VERSION "FL_PT_CANFD"

NS_ :

BS_:

BU_: EMS_ICE EMS_PHEV FLZCU FMCU PDCS1 PDCS2 RMCU RXCU TCU_PHEV TCUR TESTER

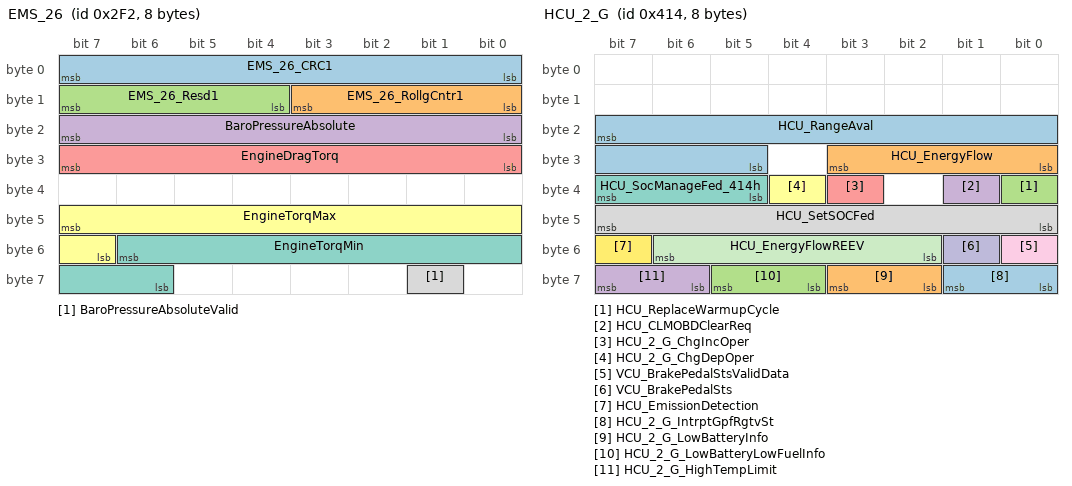
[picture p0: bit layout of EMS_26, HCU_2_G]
BO_ 754 EMS_26: 8 EMS_PHEV
 SG_ EMS_26_CRC1 : 7|8@0+ (1,0) [0|255] "" RXCU
 SG_ EMS_26_RollgCntr1 : 11|4@0+ (1,0) [0|14] "" RXCU
 SG_ EMS_26_Resd1 : 15|4@0+ (1,0) [0|15] "" RXCU
 SG_ BaroPressureAbsolute : 23|8@0+ (0.5,0) [0|127.5] "kPa" RXCU
 SG_ EngineDragTorq : 31|8@0+ (0.5,-125) [-125|0] "NM" RXCU
 SG_ EngineTorqMax : 47|9@0+ (1,-50) [-50|400] "NM" RXCU
 SG_ EngineTorqMin : 54|9@0+ (1,-50) [-50|400] "NM" RXCU
 SG_ BaroPressureAbsoluteValid : 57|1@0+ (1,0) [0|1] "" RXCU

BO_ 777 ISGF_2: 8 FMCU
 SG_ ISGF_ErrLvl : 20|4@0+ (1,0) [0|15] "" RXCU

BO_ 782 RMCU_6: 24 RXCU
 SG_ RMCU_6_CRC : 7|8@0+ (1,0) [0|255] "" Vector__XXX
 SG_ RMCU_6_RollgCntr : 11|4@0+ (1,0) [0|14] "" Vector__XXX
 SG_ RMCU_6_Resd : 15|4@0+ (1,0) [0|15] "" Vector__XXX
 SG_ RMCU_6_Ratio : 23|12@0+ (0.01,1) [8|41.95] "" PDCS1,PDCS2
 SG_ TCUR_SubFaultFlag : 39|32@0+ (1,0) [0|16777215] "" Vector__XXX
 SG_ TCUR_ActrFailrSt : 87|5@0+ (1,0) [0|31] "" Vector__XXX

BO_ 786 ISGF_3: 8 FMCU
 SG_ ISGF_GateDrvSt : 50|2@0+ (1,0) [0|3] "" RXCU

BO_ 808 RMCU_2: 16 RXCU
 SG_ RMCU_2_CRC1 : 7|8@0+ (1,0) [0|255] "" FLZCU,PDCS1,PDCS2
 SG_ RMCU_2_RollgCntr1 : 11|4@0+ (1,0) [0|14] "" FLZCU,PDCS1,PDCS2
 SG_ RMCU_2_Resd1 : 15|4@0+ (1,0) [0|15] "" FLZCU,PDCS1,PDCS2
 SG_ RMCU_2_InverterTemperature : 23|8@0+ (1,-40) [-40|213] "oC" FLZCU,PDCS1,PDCS2
 SG_ RMCU_2_StatorTemperature : 38|9@0+ (1,-40) [-40|460] "oC" FLZCU,PDCS1,PDCS2
 SG_ RMCU_HeatRunFlg : 39|1@0+ (1,0) [0|1] "" FLZCU
 SG_ RMCU_Ratio : 45|11@0+ (0.01,1) [8|15] "" FLZCU
 SG_ RMCU_LowPwrSts : 48|1@0+ (1,0) [0|1] "" FLZCU,PDCS1,PDCS2
 SG_ RMCU_InvSampTemperature : 63|8@0+ (1,-40) [-40|213] "oC" FLZCU,PDCS1,PDCS2
 SG_ RMCU_2_CRC2 : 71|8@0+ (1,0) [0|255] "" FLZCU
 SG_ RMCU_2_RollgCntr2 : 75|4@0+ (1,0) [0|14] "" FLZCU
 SG_ RMCU_2_Resd2 : 79|4@0+ (1,0) [0|15] "" FLZCU
 SG_ RMCU_2_MaxHeatSpeed : 87|16@0+ (1,-32767) [-32767|32766] "rpm" FLZCU
 SG_ RMCU_2_MaxHeatTorque : 103|12@0+ (0.25,0) [0|500] "Nm" FLZCU
 SG_ RMCU_immoResult : 107|3@0+ (1,0) [0|7] "" FLZCU

BO_ 859 FLZCU_5: 8 FLZCU
 SG_ TorqueReductReqRAValidData : 39|1@0+ (1,0) [0|1] "" RXCU

BO_ 884 TMS_4: 64 FLZCU
 SG_ WPump3Duty : 303|8@0+ (0.4,0) [0|100] "%" RXCU
 SG_ CoolingFanDuty : 382|7@0+ (1,0) [0|100] "%" RXCU

BO_ 929 IMMO_MCU_13: 8 FLZCU
 SG_ IMMO_Auth_MCU : 7|64@0+ (1,0) [0|18446744073709551615] "" RXCU

BO_ 938 IMMO_MCU_14: 8 FLZCU
 SG_ IMMO_Teach_MCU : 7|64@0+ (1,0) [0|18446744073709551615] "" RXCU

BO_ 947 MCU_IMMO_13: 8 RXCU
 SG_ MCU_Chall_IMMO : 7|64@0+ (1,0) [0|18446744073709551615] "" FLZCU

BO_ 952 MCU_IMMO_14: 8 RXCU
 SG_ MCU_Teach_IMMO : 7|64@0+ (1,0) [0|18446744073709551615] "" FLZCU

BO_ 1022 FLZCU_40: 64 FLZCU
 SG_ FLZCU_CarMode : 23|3@0+ (1,0) [0|7] "" RXCU

BO_ 1034 HCU_1_G: 8 RXCU
 SG_ HCU_1_G_CRC1 : 7|8@0+ (1,0) [0|255] "" EMS_PHEV,FLZCU
 SG_ HCU_1_G_RollgCntr1 : 11|4@0+ (1,0) [0|14] "" EMS_PHEV,FLZCU
 SG_ HCU_1_G_Resd1 : 15|4@0+ (1,0) [0|15] "" EMS_PHEV,FLZCU
 SG_ HCU_EmPwr : 23|8@0+ (1,-128) [-100|100] "%" FLZCU
 SG_ HCU_VehicleState : 27|4@0+ (1,0) [0|15] "" FLZCU
 SG_ HCU_RunMode : 29|2@0+ (1,0) [0|3] "" FLZCU,FMCU,TCU_PHEV
 SG_ HCU_TMNumber : 31|2@0+ (1,0) [0|3] "" FLZCU
 SG_ HCU_PwrTrnModeDisp : 34|3@0+ (1,0) [0|7] "" FLZCU
 SG_ HCU_IntelligentPowerSupply : 37|3@0+ (1,0) [0|7] "" FLZCU
 SG_ HCU_PowerModeFed : 39|2@0+ (1,0) [0|3] "" FLZCU,TCU_PHEV
 SG_ HCU_LimpHomeMode : 41|2@0+ (1,0) [0|3] "" FLZCU,TCU_PHEV
 SG_ HCU_ISGRegenerateSts : 42|1@0+ (1,0) [0|1] "" FLZCU
 SG_ HCU_EmOverSpdWarn : 43|1@0+ (1,0) [0|1] "" FLZCU
 SG_ HCU_PowertrainFault : 44|1@0+ (1,0) [0|1] "" FLZCU
 SG_ HCU_PrePTReady : 45|1@0+ (1,0) [0|1] "" EMS_PHEV,FLZCU
 SG_ HCU_PowerModeChangeFail : 46|1@0+ (1,0) [0|1] "" FLZCU
 SG_ BMSH_MILReq : 47|1@0+ (1,0) [0|1] "" EMS_PHEV,FLZCU
 SG_ TMF_EngMilLampReq : 48|1@0+ (1,0) [0|1] "" EMS_PHEV,FLZCU
 SG_ TMR_EngMilLampReq : 49|1@0+ (1,0) [0|1] "" EMS_PHEV,FLZCU
 SG_ HCU_MILReq : 50|1@0+ (1,0) [0|1] "" EMS_PHEV,FLZCU
 SG_ HCU_HVReady : 51|1@0+ (1,0) [0|1] "" EMS_PHEV,FLZCU,TCU_PHEV
 SG_ HCU_PTReady : 52|1@0+ (1,0) [0|1] "" EMS_PHEV,FLZCU,TCU_PHEV
 SG_ HCU_ChargingSts : 54|2@0+ (1,0) [0|3] "" FLZCU,FMCU
 SG_ HCU_PtSts : 59|4@0+ (1,0) [0|15] "" FLZCU
 SG_ HCU_InHbStrtRes : 63|4@0+ (1,0) [0|15] "" FLZCU

BO_ 1044 HCU_2_G: 8 RXCU
 SG_ HCU_RangeAval : 23|11@0+ (1,0) [0|2046] "KM" Vector__XXX
 SG_ HCU_EnergyFlow : 27|4@0+ (1,0) [0|15] "" Vector__XXX
 SG_ HCU_ReplaceWarmupCycle : 32|1@0+ (1,0) [0|1] "" EMS_PHEV,FMCU
 SG_ HCU_CLMOBDClearReq : 33|1@0+ (1,0) [0|1] "" Vector__XXX
 SG_ HCU_2_G_ChgIncOper : 35|1@0+ (1,0) [0|1] "" EMS_PHEV
 SG_ HCU_2_G_ChgDepOper : 36|1@0+ (1,0) [0|1] "" EMS_PHEV
 SG_ HCU_SocManageFed_414h : 39|3@0+ (1,0) [0|7] "" Vector__XXX
 SG_ HCU_SetSOCFed : 47|8@0+ (1,0) [0|100] "" Vector__XXX
 SG_ VCU_BrakePedalStsValidData : 48|1@0+ (1,0) [0|1] "" EMS_PHEV,FMCU
 SG_ VCU_BrakePedalSts : 49|1@0+ (1,0) [0|1] "" EMS_PHEV,FMCU
 SG_ HCU_EnergyFlowREEV : 54|5@0+ (1,0) [0|31] "" Vector__XXX
 SG_ HCU_EmissionDetection : 55|1@0+ (1,0) [0|1] "" Vector__XXX
 SG_ HCU_2_G_IntrptGpfRgtvSt : 57|2@0+ (1,0) [0|3] "" EMS_PHEV
 SG_ HCU_2_G_LowBatteryInfo : 59|2@0+ (1,0) [0|3] "" Vector__XXX
 SG_ HCU_2_G_LowBatteryLowFuelInfo : 61|2@0+ (1,0) [0|3] "" Vector__XXX
 SG_ HCU_2_G_HighTempLimit : 63|2@0+ (1,0) [0|3] "" Vector__XXX

BO_ 1057 VCU_7_G: 32 RXCU
 SG_ VCU_shfChk : 16|1@0+ (1,0) [0|1] "" Vector__XXX
 SG_ VCU_PowerLimitSOCLow : 19|3@0+ (1,0) [0|7] "" Vector__XXX
 SG_ VCU_MCU_MilLampReq : 20|1@0+ (1,0) [0|1] "" Vector__XXX
 SG_ VCU_OPDinfo : 23|3@0+ (1,0) [0|7] "" Vector__XXX
 SG_ VCU_ePTDrvPowerPcent : 31|8@0+ (1,-100) [-100|100] "%" Vector__XXX
 SG_ VCU_TowingMode : 33|2@0+ (1,0) [0|3] "" Vector__XXX
 SG_ VCU_EgyRegenLevelHighAllowed : 35|2@0+ (1,0) [0|3] "" Vector__XXX
 SG_ VCU_SportDriveModeAvailable : 36|1@0+ (1,0) [0|1] "" Vector__XXX
 SG_ VCU_RainSnowDriveModeAvailable : 37|1@0+ (1,0) [0|1] "" Vector__XXX
 SG_ VCU_OffRoadDriveModeAvailable : 38|1@0+ (1,0) [0|1] "" Vector__XXX
 SG_ VCU_CampAvailable : 39|1@0+ (1,0) [0|1] "" Vector__XXX
 SG_ VCU_DisChgSOCHighLim : 47|8@0+ (1,0) [1|100] "%" Vector__XXX
 SG_ VCU_DisChgSOCLowLim : 55|8@0+ (1,0) [1|50] "%" Vector__XXX
 SG_ VCU_ChgSocSetFed : 63|8@0+ (1,0) [50|100] "%" Vector__XXX
 SG_ VCU_EngyConsuPer10Km : 87|12@0+ (0.1,-100) [-100|100] "" Vector__XXX
 SG_ VCU_EngyConsuPer25Km : 91|12@0+ (0.1,-100) [-100|100] "" Vector__XXX
 SG_ VCU_EngyConsuPer50Km : 111|12@0+ (0.1,-100) [-100|100] "" Vector__XXX
 SG_ VCU_EngyConsuPer100m : 115|12@0+ (0.1,-100) [-100|100] "" Vector__XXX
 SG_ VCU_DisChrgPwr : 151|8@0+ (0.1,0) [0|25.5] "kW" Vector__XXX
 SG_ VCU_BookChrgSetFailRes : 154|3@0+ (1,0) [0|7] "" Vector__XXX
 SG_ VCU_BookChrgFailRes : 158|4@0+ (1,0) [0|15] "" Vector__XXX
 SG_ VCU_HVILFault : 159|1@0+ (1,0) [0|1] "" Vector__XXX
 SG_ VCUExtendRang : 167|10@0+ (1,0) [0|1022] "KM" Vector__XXX
 SG_ VCU_KeepWarmFailReason : 171|4@0+ (1,0) [0|15] "" Vector__XXX
 SG_ VCU_ExtremeEnergySavingModeAv : 173|1@0+ (1,0) [0|1] "" Vector__XXX
 SG_ VCU_TowModeAvailable : 176|1@0+ (1,0) [0|1] "" Vector__XXX
 SG_ VCU_StopModeSWStsResp : 178|2@0+ (1,0) [0|3] "" Vector__XXX
 SG_ VCU_StopModeSWAllowed : 179|1@0+ (1,0) [0|1] "" Vector__XXX
 SG_ VCU_ChgDisChgLedCtrl : 183|4@0+ (1,0) [0|15] "" Vector__XXX
 SG_ VCU_CPMaxVolt : 191|8@0+ (0.1,0) [0|20] "V" Vector__XXX
 SG_ VCUExtremeEnergySavingModeReq : 211|2@0+ (1,0) [0|3] "" Vector__XXX
 SG_ VCU_EpedalModeSts : 213|1@0+ (1,0) [0|1] "" Vector__XXX
 SG_ VCU_BookChrgStsFb : 215|2@0+ (1,0) [0|3] "" Vector__XXX
 SG_ VCU_HVNM : 219|2@0+ (1,0) [0|3] "" Vector__XXX
 SG_ VCU_DriveMode : 223|3@0+ (1,0) [0|7] "" Vector__XXX
 SG_ HCU_EnterForceEVFailRes : 229|3@0+ (1,0) [0|7] "" Vector__XXX
 SG_ HCU_EngineSelfMaintain : 231|2@0+ (1,0) [0|3] "" Vector__XXX
 SG_ HCU_EnterForceChrgFailRes : 234|3@0+ (1,0) [0|7] "" Vector__XXX
 SG_ HCU_InStartRes : 242|3@0+ (1,0) [0|7] "" Vector__XXX
 SG_ HCU_EnergyRegSetFed : 255|8@0+ (1,0) [0|100] "%" Vector__XXX

BO_ 1064 FLZCU_428h: 32 FLZCU
 SG_ WorkingSts : 28|1@0+ (1,0) [0|1] "" RXCU
 SG_ ADCC_AdsLowPowSts_333h : 37|2@0+ (1,0) [0|3] "" RXCU

BO_ 1075 VCC_2: 8 FLZCU
 SG_ VCC_2_ConfigurationMessageTrg : 23|1@0+ (1,0) [0|1] "" RXCU

BO_ 1097 TMS_HW_449h: 48 FLZCU
 SG_ TMS_RMCU_MotSelfHeatLvlReq : 86|3@0+ (1,0) [0|7] "" RXCU
 SG_ TMS_RMCU_MotSelfHeatEnReq : 87|1@0+ (1,0) [0|1] "" RXCU

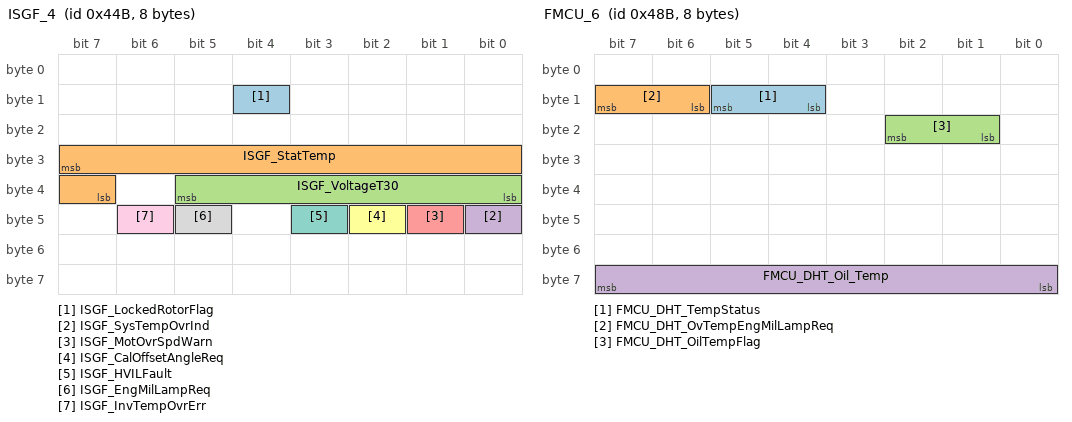
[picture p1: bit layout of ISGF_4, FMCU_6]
BO_ 1099 ISGF_4: 8 FMCU
 SG_ ISGF_LockedRotorFlag : 12|1@0+ (1,0) [0|1] "" RXCU
 SG_ ISGF_StatTemp : 31|9@0+ (1,-40) [-40|469] "oC" RXCU
 SG_ ISGF_VoltageT30 : 37|6@0+ (0.5,0) [0|31] "V" RXCU
 SG_ ISGF_SysTempOvrInd : 40|1@0+ (1,0) [0|1] "" RXCU
 SG_ ISGF_MotOvrSpdWarn : 41|1@0+ (1,0) [0|1] "" RXCU
 SG_ ISGF_CalOffsetAngleReq : 42|1@0+ (1,0) [0|1] "" RXCU
 SG_ ISGF_HVILFault : 43|1@0+ (1,0) [0|1] "" RXCU
 SG_ ISGF_EngMilLampReq : 45|1@0+ (1,0) [0|1] "" RXCU
 SG_ ISGF_InvTempOvrErr : 46|1@0+ (1,0) [0|1] "" RXCU

BO_ 1103 RMCU_4: 24 RXCU
 SG_ RMCU_WPhasecurrent : 23|11@0+ (1,-1023) [-1023|1023] "A" FLZCU
 SG_ RMCU_VPhasecurrent : 26|11@0+ (1,-1023) [-1023|1023] "A" FLZCU
 SG_ RMCU_UPhasecurrent : 47|11@0+ (1,-1023) [-1023|1023] "A" FLZCU
 SG_ RMCU_4_CRC : 71|8@0+ (1,0) [0|255] "" FLZCU
 SG_ RMCU_4_RollgCntr : 75|4@0+ (1,0) [0|14] "" FLZCU
 SG_ RMCU_4_Resd : 79|4@0+ (1,0) [0|15] "" FLZCU
 SG_ RMCU_TempW : 87|8@0+ (1,-40) [-40|213] "oC" FLZCU
 SG_ RMCU_TempV : 95|8@0+ (1,-40) [-40|213] "oC" FLZCU
 SG_ RMCU_TempU : 103|8@0+ (1,-40) [-40|213] "oC" FLZCU
 SG_ RMCU_CoolantTemp : 111|8@0+ (1,-40) [-40|213] "oC" FLZCU,FMCU
 SG_ RMCU_RotorTemp : 119|8@0+ (1,-40) [-40|213] "oC" FLZCU
 SG_ RMCU_Delta_TJ_Coolant : 127|8@0+ (1,-40) [-40|213] "oC" FLZCU
 SG_ RMCU_TMS_MotSelfHeatLvlFb : 147|3@0+ (1,0) [0|7] "" FLZCU,PDCS1,PDCS2
 SG_ RMCU_TMS_MotSelfHeatEnSts : 148|1@0+ (1,0) [0|1] "" FLZCU,PDCS1,PDCS2
 SG_ RMCU_IGBTmode : 151|3@0+ (1,0) [0|7] "" FLZCU

BO_ 1130 TCU_23: 64 PDCS1
 SG_ TCU_23_CRC1 : 7|8@0+ (1,0) [0|255] "" RXCU
 SG_ TCU_23_RollgCntr1 : 11|4@0+ (1,0) [0|14] "" RXCU
 SG_ TCU_23_Resd1 : 15|4@0+ (1,0) [0|15] "" RXCU
 SG_ TCU_23_ErrLever : 17|3@0+ (1,0) [0|7] "" RXCU
 SG_ TCU_23_GBFaultstatus : 23|2@0+ (1,0) [0|3] "" RXCU
 SG_ TCU_23_STAT_LeverModeDisp : 26|3@0+ (1,0) [0|7] "" RXCU
 SG_ TCU_23_GBWarmUpReq : 27|1@0+ (1,0) [0|1] "" RXCU
 SG_ TCU_23_TeachInState : 30|3@0+ (1,0) [0|7] "" RXCU
 SG_ TCU_23_CluSelfLrng : 39|1@0+ (1,0) [0|1] "" RXCU

BO_ 1136 VCC_3: 32 FLZCU
 SG_ VCC_3_CRC : 7|8@0+ (1,0) [0|255] "" RXCU
 SG_ VCC_3_RollgCntr : 11|4@0+ (1,0) [0|14] "" RXCU
 SG_ VCC_3_Resd1 : 15|4@0+ (1,0) [0|15] "" RXCU
 SG_ VCC_3_SN : 23|8@0+ (1,0) [1|32] "" RXCU

BO_ 1162 ONEBOX_1_G: 8 FLZCU
 SG_ VehicleSpeedVSOSig : 23|13@0+ (0.0625,0) [0|511.875] "km/h" RXCU
 SG_ VehicleSpeedVSOSigValidData : 26|1@0+ (1,0) [0|1] "" RXCU

BO_ 1163 FMCU_6: 8 FMCU
 SG_ FMCU_DHT_TempStatus : 13|2@0+ (1,0) [0|3] "" RXCU
 SG_ FMCU_DHT_OvTempEngMilLampReq : 15|2@0+ (1,0) [0|3] "" RXCU
 SG_ FMCU_DHT_OilTempFlag : 18|2@0+ (1,0) [0|3] "" RXCU
 SG_ FMCU_DHT_Oil_Temp : 63|8@0+ (1,0) [0|255] "?C" RXCU

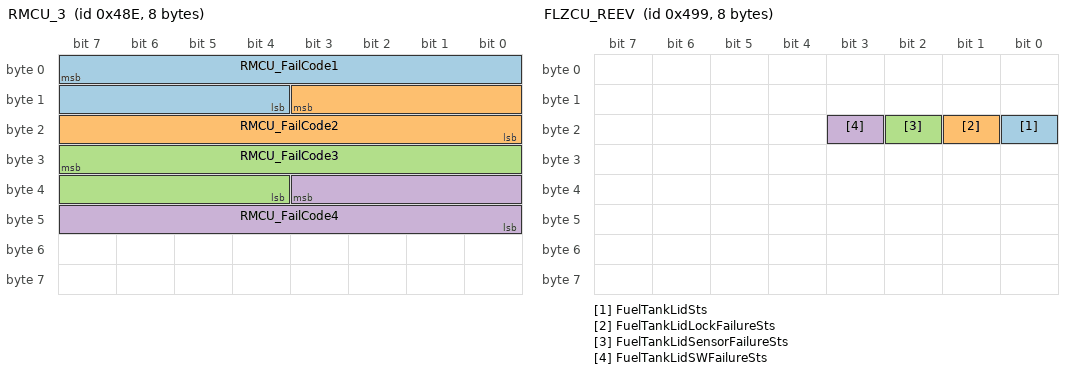
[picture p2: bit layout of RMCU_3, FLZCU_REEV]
BO_ 1166 RMCU_3: 8 RXCU
 SG_ RMCU_FailCode1 : 7|12@0+ (1,0) [0|4095] "" FLZCU,PDCS1,PDCS2
 SG_ RMCU_FailCode2 : 11|12@0+ (1,0) [0|4095] "" FLZCU,PDCS1,PDCS2
 SG_ RMCU_FailCode3 : 31|12@0+ (1,0) [0|4095] "" FLZCU,PDCS1,PDCS2
 SG_ RMCU_FailCode4 : 35|12@0+ (1,0) [0|4095] "" FLZCU,PDCS1,PDCS2

BO_ 1177 FLZCU_REEV: 8 FLZCU
 SG_ FuelTankLidSts : 16|1@0+ (1,0) [0|1] "" RXCU
 SG_ FuelTankLidLockFailureSts : 17|1@0+ (1,0) [0|1] "" RXCU
 SG_ FuelTankLidSensorFailureSts : 18|1@0+ (1,0) [0|1] "" RXCU
 SG_ FuelTankLidSWFailureSts : 19|1@0+ (1,0) [0|1] "" RXCU

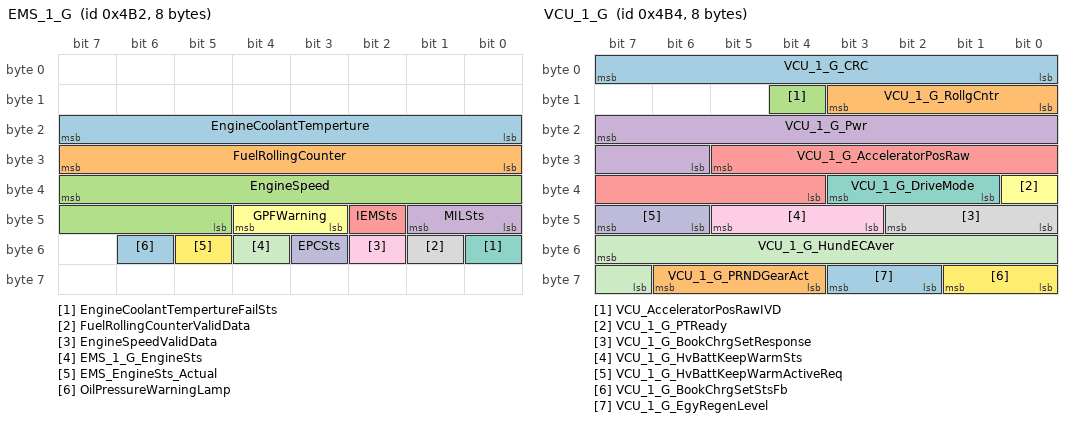
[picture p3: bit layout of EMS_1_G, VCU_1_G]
BO_ 1202 EMS_1_G: 8 EMS_PHEV
 SG_ EngineCoolantTemperture : 23|8@0+ (0.75,-48) [-48|142.5] "℃" RXCU
 SG_ FuelRollingCounter : 31|8@0+ (0.0000788519,0) [0|0.0200283826] "ltr" RXCU
 SG_ EngineSpeed : 39|11@0+ (4,0) [0|8000] "rpm" RXCU
 SG_ MILSts : 41|2@0+ (1,0) [0|3] "" RXCU
 SG_ IEMSts : 42|1@0+ (1,0) [0|1] "" RXCU
 SG_ GPFWarning : 44|2@0+ (1,0) [0|3] "" RXCU
 SG_ EngineCoolantTempertureFailSts : 48|1@0+ (1,0) [0|1] "" RXCU
 SG_ FuelRollingCounterValidData : 49|1@0+ (1,0) [0|1] "" RXCU
 SG_ EngineSpeedValidData : 50|1@0+ (1,0) [0|1] "" RXCU
 SG_ EPCSts : 51|1@0+ (1,0) [0|1] "" RXCU
 SG_ EMS_1_G_EngineSts : 52|1@0+ (1,0) [0|1] "" RXCU
 SG_ EMS_EngineSts_Actual : 53|1@0+ (1,0) [0|1] "" RXCU
 SG_ OilPressureWarningLamp : 54|1@0+ (1,0) [0|1] "" RXCU

BO_ 1204 VCU_1_G: 8 RXCU
 SG_ VCU_1_G_CRC : 7|8@0+ (1,0) [0|255] "" TCU_PHEV
 SG_ VCU_1_G_RollgCntr : 11|4@0+ (1,0) [0|14] "" TCU_PHEV
 SG_ VCU_AcceleratorPosRawIVD : 12|1@0+ (1,0) [0|1] "" FMCU
 SG_ VCU_1_G_Pwr : 23|10@0+ (1,-500) [-500|500] "" Vector__XXX
 SG_ VCU_1_G_AcceleratorPosRaw : 29|10@0+ (0.1,0) [0|100] "%" FMCU
 SG_ VCU_1_G_PTReady : 32|1@0+ (1,0) [0|1] "" RMCU,TCUR
 SG_ VCU_1_G_DriveMode : 35|3@0+ (1,0) [0|7] "" Vector__XXX
 SG_ VCU_1_G_BookChrgSetResponse : 42|3@0+ (1,0) [0|7] "" Vector__XXX
 SG_ VCU_1_G_HvBattKeepWarmSts : 45|3@0+ (1,0) [0|7] "" Vector__XXX
 SG_ VCU_1_G_HvBattKeepWarmActiveReq : 47|2@0+ (1,0) [0|3] "" Vector__XXX
 SG_ VCU_1_G_HundECAver : 55|9@0+ (0.1,0) [0|51] "kwh" Vector__XXX
 SG_ VCU_1_G_BookChrgSetStsFb : 57|2@0+ (1,0) [0|3] "" Vector__XXX
 SG_ VCU_1_G_EgyRegenLevel : 59|2@0+ (1,0) [0|3] "" Vector__XXX
 SG_ VCU_1_G_PRNDGearAct : 62|3@0+ (1,0) [0|7] "" EMS_PHEV,FMCU,RMCU,TCU_PHEV,TCUR

BO_ 1207 TMS_TDU_2: 64 FLZCU
 SG_ WPump3Duty_FB : 87|8@0+ (0.4,0) [0|100] "%" RXCU
 SG_ WPump3FltSt : 91|4@0+ (1,0) [0|15] "" RXCU
 SG_ CoolingFanFlt : 250|3@0+ (1,0) [0|7] "" RXCU

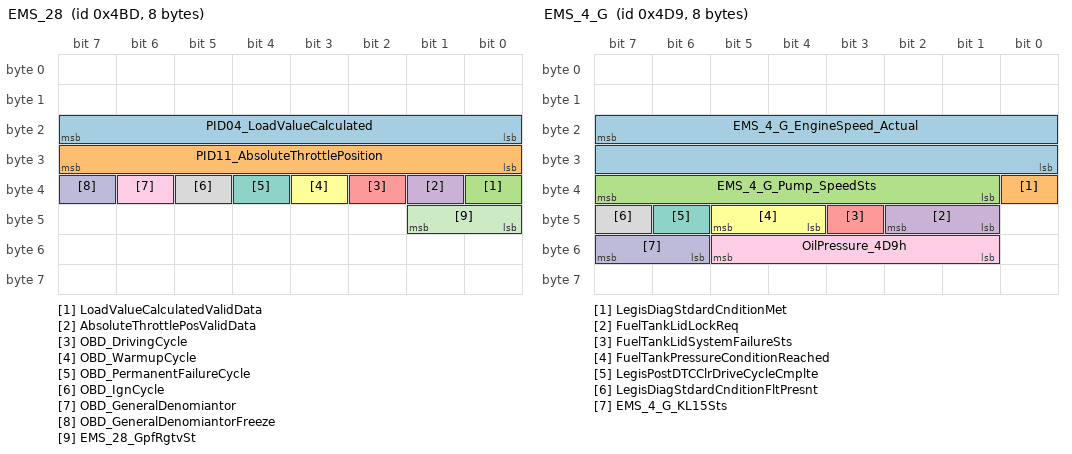
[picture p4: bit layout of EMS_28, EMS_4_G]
BO_ 1213 EMS_28: 8 EMS_PHEV
 SG_ PID04_LoadValueCalculated : 23|8@0+ (0.392,0) [0|99.96] "%" RXCU
 SG_ PID11_AbsoluteThrottlePosition : 31|8@0+ (0.392,0) [0|99.96] "%" RXCU
 SG_ LoadValueCalculatedValidData : 32|1@0+ (1,0) [0|1] "" RXCU
 SG_ AbsoluteThrottlePosValidData : 33|1@0+ (1,0) [0|1] "" RXCU
 SG_ OBD_DrivingCycle : 34|1@0+ (1,0) [0|1] "" RXCU
 SG_ OBD_WarmupCycle : 35|1@0+ (1,0) [0|1] "" RXCU
 SG_ OBD_PermanentFailureCycle : 36|1@0+ (1,0) [0|1] "" RXCU
 SG_ OBD_IgnCycle : 37|1@0+ (1,0) [0|1] "" RXCU
 SG_ OBD_GeneralDenomiantor : 38|1@0+ (1,0) [0|1] "" RXCU
 SG_ OBD_GeneralDenomiantorFreeze : 39|1@0+ (1,0) [0|1] "" RXCU
 SG_ EMS_28_GpfRgtvSt : 41|2@0+ (1,0) [0|3] "" RXCU

BO_ 1241 EMS_4_G: 8 EMS_PHEV
 SG_ EMS_4_G_EngineSpeed_Actual : 23|16@0+ (0.25,0) [0|16383] "rpm" RXCU
 SG_ LegisDiagStdardCnditionMet : 32|1@0+ (1,0) [0|1] "" RXCU
 SG_ EMS_4_G_Pump_SpeedSts : 39|7@0+ (1,0) [0|100] "%" RXCU
 SG_ FuelTankLidLockReq : 42|2@0+ (1,0) [0|3] "" RXCU
 SG_ FuelTankLidSystemFailureSts : 43|1@0+ (1,0) [0|1] "" RXCU
 SG_ FuelTankPressureConditionReached : 45|2@0+ (1,0) [0|3] "" RXCU
 SG_ LegisPostDTCClrDriveCycleCmplte : 46|1@0+ (1,0) [0|1] "" RXCU
 SG_ LegisDiagStdardCnditionFltPresnt : 47|1@0+ (1,0) [0|1] "" RXCU
 SG_ OilPressure_4D9h : 53|5@0+ (0.05,0) [0|1.15] "Mpa" RXCU
 SG_ EMS_4_G_KL15Sts : 55|2@0+ (1,0) [0|3] "" RXCU

BO_ 1252 ICC_COM_1: 8 FLZCU
 SG_ TotalOdometer_km_OBD : 23|24@0+ (0.1,0) [0|999999.9] "km" RXCU
 SG_ TotalOdometer_km_OBDValidData : 60|1@0+ (1,0) [0|1] "" RXCU

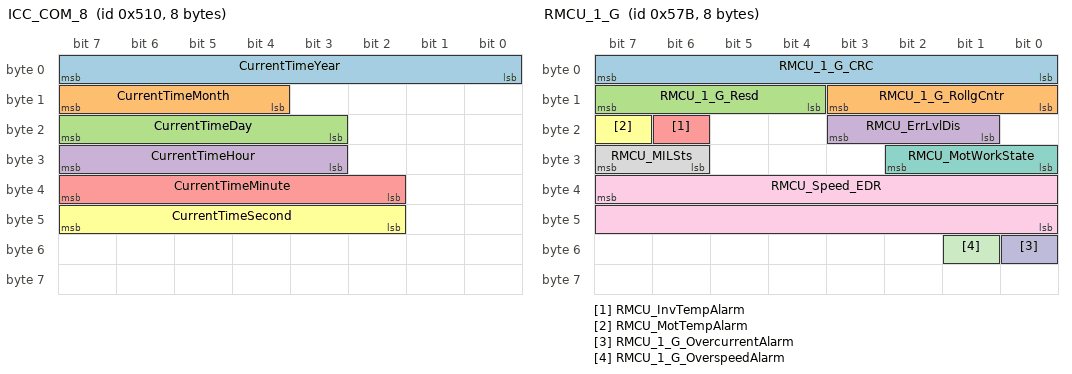
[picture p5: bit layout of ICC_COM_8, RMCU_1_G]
BO_ 1296 ICC_COM_8: 8 FLZCU
 SG_ CurrentTimeYear : 7|8@0+ (1,2000) [2000|2255] "" RXCU
 SG_ CurrentTimeMonth : 15|4@0+ (1,0) [1|12] "" RXCU
 SG_ CurrentTimeDay : 23|5@0+ (1,0) [1|31] "" RXCU
 SG_ CurrentTimeHour : 31|5@0+ (1,0) [0|23] "" RXCU
 SG_ CurrentTimeMinute : 39|6@0+ (1,0) [0|59] "" RXCU
 SG_ CurrentTimeSecond : 47|6@0+ (1,0) [0|59] "" RXCU

BO_ 1307 RMCU_RemoteDiag_51Bh: 32 RXCU
 SG_ RMCU_TotalFaultNum_51Bh : 7|8@0+ (1,0) [0|255] "" FLZCU
 SG_ RMCU_FrameIndex_51Bh : 12|5@0+ (1,0) [0|31] "" FLZCU
 SG_ RMCU_SupplierNum_51Bh : 15|3@0+ (1,0) [0|7] "" FLZCU
 SG_ RMCU_FaultNum1_51Bh : 23|12@0+ (1,0) [0|4095] "" FLZCU
 SG_ RMCU_FaultNum2_51Bh : 27|12@0+ (1,0) [0|4095] "" FLZCU
 SG_ RMCU_FaultNum3_51Bh : 47|12@0+ (1,0) [0|4095] "" FLZCU
 SG_ RMCU_FaultNum4_51Bh : 51|12@0+ (1,0) [0|4095] "" FLZCU
 SG_ RMCU_FaultNum5_51Bh : 71|12@0+ (1,0) [0|4095] "" FLZCU
 SG_ RMCU_FaultNum6_51Bh : 75|12@0+ (1,0) [0|4095] "" FLZCU
 SG_ RMCU_FaultNum7_51Bh : 95|12@0+ (1,0) [0|4095] "" FLZCU
 SG_ RMCU_FaultNum8_51Bh : 99|12@0+ (1,0) [0|4095] "" FLZCU
 SG_ RMCU_FaultNum9_51Bh : 119|12@0+ (1,0) [0|4095] "" FLZCU
 SG_ RMCU_FaultNum10_51Bh : 123|12@0+ (1,0) [0|4095] "" FLZCU
 SG_ RMCU_FaultNum11_51Bh : 143|12@0+ (1,0) [0|4095] "" FLZCU
 SG_ RMCU_FaultNum12_51Bh : 147|12@0+ (1,0) [0|4095] "" FLZCU
 SG_ RMCU_FaultNum13_51Bh : 167|12@0+ (1,0) [0|4095] "" FLZCU
 SG_ RMCU_FaultNum14_51Bh : 171|12@0+ (1,0) [0|4095] "" FLZCU
 SG_ RMCU_FaultNum15_51Bh : 191|12@0+ (1,0) [0|4095] "" FLZCU
 SG_ RMCU_FaultNum16_51Bh : 195|12@0+ (1,0) [0|4095] "" FLZCU
 SG_ RMCU_FaultNum17_51Bh : 215|12@0+ (1,0) [0|4095] "" FLZCU
 SG_ RMCU_FaultNum18_51Bh : 219|12@0+ (1,0) [0|4095] "" FLZCU
 SG_ RMCU_FaultNum19_51Bh : 239|12@0+ (1,0) [0|4095] "" FLZCU
 SG_ RMCU_FaultNum20_51Bh : 243|12@0+ (1,0) [0|4095] "" FLZCU

BO_ 1314 HCU_25: 64 RXCU
 SG_ HCU_CRC1_522h : 7|8@0+ (1,0) [0|255] "" Vector__XXX
 SG_ HCU_RollgCntr1_522h : 11|4@0+ (1,0) [0|14] "" Vector__XXX
 SG_ HCU_Resd1_522h : 15|4@0+ (1,0) [0|15] "" Vector__XXX
 SG_ HCU_V2lDisChgBck : 17|2@0+ (1,0) [0|3] "" Vector__XXX
 SG_ HCU_DisChgMemFed : 19|2@0+ (1,0) [0|3] "" Vector__XXX
 SG_ HCU_V2VDisChgBck : 21|2@0+ (1,0) [0|3] "" Vector__XXX
 SG_ HCU_V2l_IntlDisChgBck : 23|2@0+ (1,0) [0|3] "" Vector__XXX
 SG_ HCU_FuelDetnOpDefeated : 25|2@0+ (1,0) [0|3] "" Vector__XXX
 SG_ HCU_FuelDetnModSwtFed : 27|2@0+ (1,0) [0|3] "" Vector__XXX
 SG_ HCU_FuelDetnStateFed : 29|2@0+ (1,0) [0|3] "" Vector__XXX
 SG_ HCU_HVDownRepairModeFed : 31|2@0+ (1,0) [0|3] "" Vector__XXX
 SG_ HCU_SumFuCns : 37|9@0+ (0.1,0) [0|50] "L/km" Vector__XXX
 SG_ HCU_TrailerMode : 39|2@0+ (1,0) [0|3] "" Vector__XXX
 SG_ HCU_TABSwtFed_522h : 40|2@0+ (1,0) [0|3] "" Vector__XXX
 SG_ HCU_MotSelfHeatLvlReq : 43|3@0+ (1,0) [0|7] "" RMCU
 SG_ HCU_MotSelfHeatEnReq : 44|1@0+ (1,0) [0|1] "" RMCU
 SG_ HCU_KeyDriveModememory : 49|2@0+ (1,0) [0|3] "" Vector__XXX
 SG_ HCU_DrivePowerDispSetFed : 51|2@0+ (1,0) [0|3] "" Vector__XXX
 SG_ HCU_TCMStsReq_522h : 54|1@0+ (1,0) [0|1] "" Vector__XXX
 SG_ HCU_EXPERTNormFed : 57|2@0+ (1,0) [0|3] "" Vector__XXX
 SG_ HCU_4LModeFed : 58|1@0+ (1,0) [0|1] "" Vector__XXX
 SG_ HCU_EXPERTEcoFed : 60|2@0+ (1,0) [0|3] "" Vector__XXX
 SG_ HCU_SingleRegnRmn : 61|1@0+ (1,0) [0|1] "" Vector__XXX
 SG_ HCU_DRIFTModeSts : 63|2@0+ (1,0) [0|3] "" Vector__XXX
 SG_ HCU_CRC2_522h : 71|8@0+ (1,0) [0|255] "" Vector__XXX
 SG_ HCU_RollgCntr2_522h : 75|4@0+ (1,0) [0|14] "" Vector__XXX
 SG_ HCU_Resd2_522h : 79|4@0+ (1,0) [0|15] "" Vector__XXX
 SG_ HCU_EXPERTAWDFed : 81|2@0+ (1,0) [0|3] "" Vector__XXX
 SG_ HCU_EXPERTRWDFed : 83|2@0+ (1,0) [0|3] "" Vector__XXX
 SG_ HCU_CrossaxisFed : 85|2@0+ (1,0) [0|3] "" Vector__XXX
 SG_ HCU_EXPERTSportFed : 87|2@0+ (1,0) [0|3] "" Vector__XXX
 SG_ HCU_StopChrgnModeFed : 89|2@0+ (1,0) [0|3] "" Vector__XXX
 SG_ HCU_StopChrgnFed : 91|2@0+ (1,0) [0|3] "" Vector__XXX
 SG_ HCU_CLIMBFed : 93|2@0+ (1,0) [0|3] "" Vector__XXX
 SG_ HCU_EXPERTAutoFed : 95|2@0+ (1,0) [0|3] "" Vector__XXX
 SG_ HCU_HEV_FunctionLimit : 96|1@0+ (1,0) [0|1] "" Vector__XXX
 SG_ HCU_ParkingChargeReminder : 97|1@0+ (1,0) [0|1] "" Vector__XXX
 SG_ HCU_PowerCut : 98|1@0+ (1,0) [0|1] "" Vector__XXX
 SG_ HCU_IMMOReleaseSignal : 99|1@0+ (1,0) [0|1] "" Vector__XXX
 SG_ HCU_LVPowSupSYSAbn_lit : 100|1@0+ (1,0) [0|1] "" Vector__XXX
 SG_ HCU_ChrgnFctMemSt : 102|2@0+ (1,0) [0|3] "" Vector__XXX
 SG_ HCU_PowerModeChangeInhibit : 104|1@0+ (1,0) [0|1] "" Vector__XXX
 SG_ HCU_DisconnectChagWarn : 105|1@0+ (1,0) [0|1] "" Vector__XXX
 SG_ HCU_EngineRunClmReq : 106|1@0+ (1,0) [0|1] "" Vector__XXX
 SG_ HCU_VehicleSpeedMax_Limit : 107|1@0+ (1,0) [0|1] "" Vector__XXX
 SG_ HCU_AccleAbility_Limit : 108|1@0+ (1,0) [0|1] "" Vector__XXX
 SG_ HCU_DriveInhibit_GearP : 109|1@0+ (1,0) [0|1] "" Vector__XXX
 SG_ HCU_SetModeNotChange : 110|1@0+ (1,0) [0|1] "" Vector__XXX
 SG_ HCU_UTURNSnowFed : 111|1@0+ (1,0) [0|1] "" Vector__XXX
 SG_ HCU_PowerLevel : 114|3@0+ (1,0) [0|7] "" Vector__XXX
 SG_ HCU_TowingModeEna : 115|1@0+ (1,0) [0|1] "" Vector__XXX
 SG_ HCU_LeaveVehicleWarning : 116|1@0+ (1,0) [0|1] "" Vector__XXX
 SG_ HCU_DedicatedModeInhibit : 117|1@0+ (1,0) [0|1] "" Vector__XXX
 SG_ HCU_DisChargeStopFault : 119|2@0+ (1,0) [0|3] "" Vector__XXX
 SG_ HCU_RearEDLSts : 123|4@0+ (1,0) [0|15] "" Vector__XXX
 SG_ HCU_FrntEDLSts : 127|4@0+ (1,0) [0|15] "" Vector__XXX
 SG_ HCU_CRC3_522h : 135|8@0+ (1,0) [0|255] "" Vector__XXX
 SG_ HCU_RollgCntr3_522h : 139|4@0+ (1,0) [0|14] "" Vector__XXX
 SG_ HCU_Resd3_522h : 143|4@0+ (1,0) [0|15] "" Vector__XXX
 SG_ HCU_CruiseLimitSpeedValue : 146|13@0+ (0.0625,0) [0|511.875] "km/h" Vector__XXX
 SG_ HCU_DriveMode_JT : 151|5@0+ (1,0) [0|31] "" FMCU,RMCU,TCU_PHEV,TCUR
 SG_ HCU_SocManageFed : 162|3@0+ (1,0) [0|7] "" Vector__XXX
 SG_ HCU_SinglePedalMemFed : 163|1@0+ (1,0) [0|1] "" Vector__XXX
 SG_ HCU_CCOSwtFed : 165|2@0+ (1,0) [0|3] "" Vector__XXX
 SG_ HCU_Pwr : 175|12@0+ (1,-2000) [-2000|2000] "KW" Vector__XXX
 SG_ HCU_DrvGearShiftFailureIndcn : 179|4@0+ (1,0) [0|15] "" Vector__XXX
 SG_ HCU_UTURNSandFed : 184|1@0+ (1,0) [0|1] "" Vector__XXX
 SG_ HCU_CruiseControlStatus : 186|2@0+ (1,0) [0|3] "" Vector__XXX
 SG_ HCU_EXPERTEESPSet : 188|2@0+ (1,0) [0|3] "" Vector__XXX
 SG_ HCU_EgyRegenLevel : 191|3@0+ (1,0) [0|7] "" Vector__XXX
 SG_ HCU_CRC4_522h : 199|8@0+ (1,0) [0|255] "" Vector__XXX
 SG_ HCU_RollgCntr4_522h : 203|4@0+ (1,0) [0|14] "" Vector__XXX
 SG_ HCU_Resd4_522h : 207|4@0+ (1,0) [0|15] "" Vector__XXX
 SG_ HCU_EngyFlowToDisp : 211|5@0+ (1,0) [0|31] "" Vector__XXX
 SG_ HCU_UTURNGrassFed : 212|1@0+ (1,0) [0|1] "" Vector__XXX
 SG_ HCU_UTURNMudFed : 213|1@0+ (1,0) [0|1] "" Vector__XXX
 SG_ HCU_LTCDispFed : 215|2@0+ (1,0) [0|3] "" Vector__XXX
 SG_ HCU_iTAS_Warn : 217|3@0+ (1,0) [0|7] "" Vector__XXX
 SG_ HCU_iCCO_Warn : 221|4@0+ (1,0) [0|15] "" Vector__XXX
 SG_ HCU_DriveModeChangeFail : 222|1@0+ (1,0) [0|1] "" Vector__XXX
 SG_ HCU_25_Crossaxis_Warn : 225|3@0+ (1,0) [0|7] "" Vector__XXX
 SG_ HCU_25_EDLFed : 227|2@0+ (1,0) [0|3] "" Vector__XXX
 SG_ HCU_DraggingModeRemind : 230|3@0+ (1,0) [0|7] "" Vector__XXX
 SG_ HCU_iTASSceneReq : 232|3@0+ (1,0) [0|7] "" Vector__XXX
 SG_ HCU_25_iTAS_SlopWarn : 234|2@0+ (1,0) [0|3] "" Vector__XXX
 SG_ HCU_ExterTempLowHint : 236|2@0+ (1,0) [0|3] "" Vector__XXX
 SG_ HCU_iTAS_Active : 238|2@0+ (1,0) [0|3] "" Vector__XXX
 SG_ HCU_25_VehSpdOffroadRmn : 240|1@0+ (1,0) [0|1] "" Vector__XXX
 SG_ HCU_DrivingModReq : 245|5@0+ (1,0) [0|31] "" Vector__XXX
 SG_ HCU_25_ADS_FctSts : 248|1@0+ (1,0) [0|1] "" FMCU,RMCU,TCUR
 SG_ HCU_25_DRIFTModeSetReq : 251|3@0+ (1,0) [0|7] "" Vector__XXX
 SG_ HCU_25_CrossaxisReq : 253|2@0+ (1,0) [0|3] "" Vector__XXX
 SG_ HCU_25_CCOSwtReq : 255|2@0+ (1,0) [0|3] "" Vector__XXX
 SG_ HCU_CRC5_522h : 263|8@0+ (1,0) [0|255] "" Vector__XXX
 SG_ HCU_RollgCntr5_522h : 267|4@0+ (1,0) [0|14] "" Vector__XXX
 SG_ HCU_Resd5_522h : 271|4@0+ (1,0) [0|15] "" Vector__XXX
 SG_ HCU_25_ErrorCode : 279|16@0+ (1,0) [0|65535] "" Vector__XXX
 SG_ HCU_25_ErrorCount : 295|8@0+ (1,0) [0|255] "" Vector__XXX
 SG_ HCU_25_iDRIFT_Warn : 298|3@0+ (1,0) [0|7] "" Vector__XXX
 SG_ HCU_25_SetVehSpdOffroad : 300|2@0+ (1,0) [0|3] "" Vector__XXX
 SG_ HCU_25_LaunchMod_Warn : 303|3@0+ (1,0) [0|7] "" Vector__XXX
 SG_ HCU_25_TAB_Warn : 307|3@0+ (1,0) [0|7] "" Vector__XXX
 SG_ HCU_25_CCO_TextDisp : 311|4@0+ (1,0) [0|15] "" Vector__XXX
 SG_ HCU_25_DCM_Warn : 315|4@0+ (1,0) [0|15] "" Vector__XXX
 SG_ HCU_25_CCMFed : 317|2@0+ (1,0) [0|3] "" Vector__XXX
 SG_ HCU_25_TABReq : 319|2@0+ (1,0) [0|3] "" Vector__XXX
 SG_ HCU_SumElecCns : 339|12@0+ (0.1,-100) [-100|100] "kwh/100km" Vector__XXX
 SG_ HCU_CrossBorderSts : 341|2@0+ (1,0) [0|3] "" Vector__XXX
 SG_ HCU_DischgSetSOCFed : 367|8@0+ (1,0) [0|100] "%" Vector__XXX
 SG_ HCU_facCleverDrvAct_522h : 369|5@0+ (0.1,-1) [-1|2.1] "" Vector__XXX
 SG_ HCU_stCleverDrvAct_522h : 371|2@0+ (1,0) [0|3] "" Vector__XXX
 SG_ HCU_stCleverRgnAct_522h : 373|2@0+ (1,0) [0|3] "" Vector__XXX
 SG_ HCU_stCleverMainAct_522h : 375|2@0+ (1,0) [0|3] "" Vector__XXX
 SG_ EnergySavingModeSts_522h : 378|2@0+ (1,0) [0|3] "" Vector__XXX
 SG_ HCU_facCleverDrvActRstFed_522h : 380|2@0+ (1,0) [0|3] "" Vector__XXX
 SG_ HCU_SailramainingT_Indc_522h : 407|16@0+ (1,0) [0|65535] "s" Vector__XXX
 SG_ HCU_ATCM_Operation_REQ_522h : 416|3@0+ (1,0) [0|7] "" Vector__XXX
 SG_ HCU_ModeSwFailureIndc_522h : 419|3@0+ (1,0) [0|7] "" Vector__XXX
 SG_ HCU_Sailmode_522h : 423|4@0+ (1,0) [0|15] "" Vector__XXX
 SG_ HCU_CarSickRelfModeFb : 425|2@0+ (1,0) [0|3] "" Vector__XXX
 SG_ HCU_DeepSnowSts_522h : 427|2@0+ (1,0) [0|3] "" Vector__XXX
 SG_ DriveModeChangeFailReason_522h : 429|2@0+ (1,0) [0|3] "" Vector__XXX
 SG_ HCU_CLIMBDisReason_522h : 433|4@0+ (1,0) [0|15] "" Vector__XXX
 SG_ HCU_CarSickRelfModeDisReason : 436|3@0+ (1,0) [0|7] "" Vector__XXX
 SG_ HCU_DCMSwtFed : 439|3@0+ (1,0) [0|7] "" FMCU,RMCU
 SG_ HCU_LightSandSts_522h : 445|2@0+ (1,0) [0|3] "" Vector__XXX

BO_ 1315 RMCU_2_G: 16 RXCU
 SG_ RMCU_2_G_InverterTemperature : 23|8@0+ (1,-40) [-40|213] "oC" FLZCU
 SG_ RMCU_2_G_StatorTemperature : 31|9@0+ (1,-40) [-40|460] "oC" FLZCU
 SG_ RMCU_2_G_OutputTorque : 35|12@0+ (0.25,-500) [-500|500] "Nm" FLZCU
 SG_ RMCU_2_G_Speed : 55|16@0+ (1,-32767) [-32767|32766] "rpm" FLZCU
 SG_ RMCU_2_GVoltageHV : 81|10@0+ (1,0) [0|1021] "V" FLZCU
 SG_ RMCU_2_G_CurrentHV : 98|11@0+ (1,-1023) [-1023|1021] "A" FLZCU

BO_ 1338 FMCU_1_G: 8 FMCU
 SG_ FMCU_MotWorkState : 21|2@0+ (1,0) [0|3] "" RXCU

BO_ 1403 RMCU_1_G: 8 RXCU
 SG_ RMCU_1_G_CRC : 7|8@0+ (1,0) [0|255] "" FLZCU,PDCS1,PDCS2
 SG_ RMCU_1_G_RollgCntr : 11|4@0+ (1,0) [0|14] "" FLZCU,PDCS1,PDCS2
 SG_ RMCU_1_G_Resd : 15|4@0+ (1,0) [0|15] "" FLZCU,PDCS1,PDCS2
 SG_ RMCU_ErrLvlDis : 19|3@0+ (1,0) [0|7] "" FLZCU,PDCS1,PDCS2
 SG_ RMCU_InvTempAlarm : 22|1@0+ (1,0) [0|1] "" FLZCU,PDCS1,PDCS2
 SG_ RMCU_MotTempAlarm : 23|1@0+ (1,0) [0|1] "" FLZCU,PDCS1,PDCS2
 SG_ RMCU_MotWorkState : 26|3@0+ (1,0) [0|7] "" FLZCU,PDCS1,PDCS2
 SG_ RMCU_MILSts : 31|2@0+ (1,0) [0|3] "" FLZCU,PDCS1,PDCS2
 SG_ RMCU_Speed_EDR : 39|16@0+ (1,-32767) [-32767|32766] "rpm" FLZCU,PDCS1,PDCS2
 SG_ RMCU_1_G_OvercurrentAlarm : 48|1@0+ (1,0) [0|1] "" FLZCU
 SG_ RMCU_1_G_OverspeedAlarm : 49|1@0+ (1,0) [0|1] "" FLZCU

BO_ 1407 RMCU_Version: 16 RXCU
 SG_ RMCU_Version_CRC1 : 7|8@0+ (1,0) [0|255] "" Vector__XXX
 SG_ RMCU_Version_RollgCntr1 : 11|4@0+ (1,0) [0|14] "" Vector__XXX
 SG_ RMCU_Version_Resd1 : 15|4@0+ (1,0) [0|15] "" Vector__XXX
 SG_ RMCU_SupplierCode : 23|16@0+ (1,0) [0|65535] "" Vector__XXX
 SG_ RMCU_HwVersion : 39|8@0+ (1,0) [0|255] "" Vector__XXX
 SG_ RMCU_SwMajorVersion : 47|8@0+ (1,0) [0|255] "" Vector__XXX
 SG_ RMCU_SwMinorVersion : 55|8@0+ (1,0) [0|255] "" Vector__XXX
 SG_ RMCU_SwPatchVersion : 63|8@0+ (1,0) [0|255] "" Vector__XXX
 SG_ TCUR_SwVersion : 87|24@0+ (1,0) [0|16777215] "" Vector__XXX

BO_ 1479 FMCU_11: 32 FMCU
 SG_ FMCU_BoostInputVoltAct : 81|10@0+ (1,0) [0|1021] "V" RXCU
 SG_ FMCU_BoostModeAct : 83|2@0+ (1,0) [0|3] "" RXCU
 SG_ FMCU_BoostPhaseCurrentA : 103|11@0+ (1,-1023) [-1023|1023] "A" RXCU
 SG_ FMCU_BoostPhaseCurrentB : 108|11@0+ (1,-1023) [-1023|1023] "A" RXCU
 SG_ FMCU_BoostInductTempA : 127|8@0+ (1,-40) [-40|213] "?C" RXCU
 SG_ FMCU_BoostInductTempB : 151|8@0+ (1,-40) [-40|213] "?C" RXCU
 SG_ FMCU_BoostModuleTempA : 159|8@0+ (1,-40) [-40|213] "?C" RXCU
 SG_ FMCU_BoostModuleTempB : 167|8@0+ (1,-40) [-40|213] "?C" RXCU
 SG_ FMCU_GM_Oil_Valve_Current : 181|10@0+ (0.01,0) [0|10] "A" RXCU
 SG_ FMCU_GM_Oil_Valve_Sts : 183|2@0+ (1,0) [0|3] "" RXCU

BO_ 1521 EMS_RemoteDiag: 32 EMS_ICE
 SG_ EMS_TotalFaultNum : 7|8@0+ (1,0) [0|255] "" RXCU
 SG_ EMS_FrameIndex : 12|5@0+ (1,0) [0|31] "" RXCU
 SG_ EMS_SupplierNum : 15|3@0+ (1,0) [0|7] "" RXCU
 SG_ EMS_FaultNum1 : 23|12@0+ (1,0) [0|4095] "" RXCU
 SG_ EMS_FaultNum2 : 27|12@0+ (1,0) [0|4095] "" RXCU
 SG_ EMS_FaultNum3 : 47|12@0+ (1,0) [0|4095] "" RXCU
 SG_ EMS_FaultNum4 : 51|12@0+ (1,0) [0|4095] "" RXCU
 SG_ EMS_FaultNum5 : 71|12@0+ (1,0) [0|4095] "" RXCU
 SG_ EMS_FaultNum6 : 75|12@0+ (1,0) [0|4095] "" RXCU
 SG_ EMS_FaultNum7 : 95|12@0+ (1,0) [0|4095] "" RXCU
 SG_ EMS_FaultNum8 : 99|12@0+ (1,0) [0|4095] "" RXCU
 SG_ EMS_FaultNum9 : 119|12@0+ (1,0) [0|4095] "" RXCU
 SG_ EMS_FaultNum10 : 123|12@0+ (1,0) [0|4095] "" RXCU
 SG_ EMS_FaultNum11 : 143|12@0+ (1,0) [0|4095] "" RXCU
 SG_ EMS_FaultNum12 : 147|12@0+ (1,0) [0|4095] "" RXCU
 SG_ EMS_FaultNum13 : 167|12@0+ (1,0) [0|4095] "" RXCU
 SG_ EMS_FaultNum14 : 171|12@0+ (1,0) [0|4095] "" RXCU
 SG_ EMS_FaultNum15 : 191|12@0+ (1,0) [0|4095] "" RXCU
 SG_ EMS_FaultNum16 : 195|12@0+ (1,0) [0|4095] "" RXCU
 SG_ EMS_FaultNum17 : 215|12@0+ (1,0) [0|4095] "" RXCU
 SG_ EMS_FaultNum18 : 219|12@0+ (1,0) [0|4095] "" RXCU
 SG_ EMS_FaultNum19 : 239|12@0+ (1,0) [0|4095] "" RXCU
 SG_ EMS_FaultNum20 : 243|12@0+ (1,0) [0|4095] "" RXCU

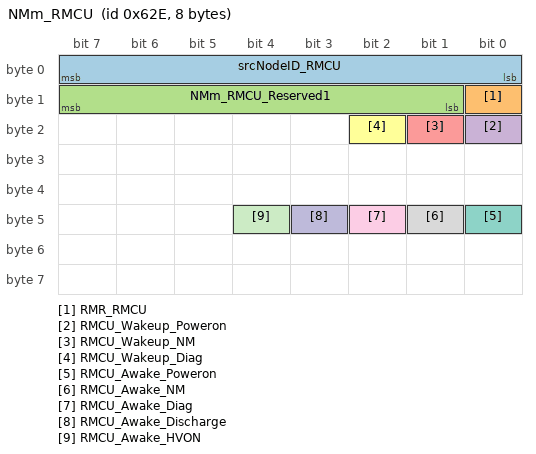
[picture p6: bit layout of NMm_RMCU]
BO_ 1582 NMm_RMCU: 8 RXCU
 SG_ srcNodeID_RMCU : 7|8@0+ (1,0) [0|255] "" Vector__XXX
 SG_ RMR_RMCU : 8|1@0+ (1,0) [0|1] "" Vector__XXX
 SG_ NMm_RMCU_Reserved1 : 15|7@0+ (1,0) [0|127] "" Vector__XXX
 SG_ RMCU_Wakeup_Poweron : 16|1@0+ (1,0) [0|1] "" Vector__XXX
 SG_ RMCU_Wakeup_NM : 17|1@0+ (1,0) [0|1] "" Vector__XXX
 SG_ RMCU_Wakeup_Diag : 18|1@0+ (1,0) [0|1] "" Vector__XXX
 SG_ RMCU_Awake_Poweron : 40|1@0+ (1,0) [0|1] "" Vector__XXX
 SG_ RMCU_Awake_NM : 41|1@0+ (1,0) [0|1] "" Vector__XXX
 SG_ RMCU_Awake_Diag : 42|1@0+ (1,0) [0|1] "" Vector__XXX
 SG_ RMCU_Awake_Discharge : 43|1@0+ (1,0) [0|1] "" Vector__XXX
 SG_ RMCU_Awake_HVON : 44|1@0+ (1,0) [0|1] "" Vector__XXX

BO_ 1818 Diag_RMCU_REQ: 64 FLZCU
 SG_ Diag_RMCU_REQ : 7|64@0+ (1,0) [0|18446744073709551615] "" RXCU

BO_ 1843 Diag_TCUR_REQ: 64 FLZCU
 SG_ Diag_TCUR_REQ : 7|64@0+ (1,0) [0|18446744073709551615] "" RXCU

BO_ 1946 Diag_RMCU_RES: 64 RXCU
 SG_ Diag_RMCU_RES : 7|64@0+ (1,0) [0|18446744073709551615] "" FLZCU

BO_ 1971 Diag_TCUR_RES: 64 RXCU
 SG_ Diag_TCUR_RES : 7|64@0+ (1,0) [0|18446744073709551615] "" FLZCU

BO_ 2015 DIAG_OBD_REQ_Broadcast: 8 FLZCU
 SG_ Diag_Functional_REQ : 7|64@0+ (1,0) [0|18446744073709551615] "" RXCU

BO_ 2019 Diag_OBD_RMCU_REQ: 64 FLZCU
 SG_ Diag_OBD_RMCU_REQ : 7|64@0+ (1,0) [0|18446744073709551615] "" RXCU

BO_ 2027 Diag_OBD_RMCU_RES: 8 RXCU
 SG_ Diag_OBD_RMCU_RES : 7|64@0+ (1,0) [0|255] "" FLZCU

BO_TX_BU_ 754 : EMS_PHEV,PDCS1,PDCS2;
BO_TX_BU_ 1130 : PDCS1,TCU_PHEV;
BO_TX_BU_ 1202 : EMS_PHEV,PDCS1,PDCS2;
BO_TX_BU_ 1213 : EMS_PHEV,PDCS1,PDCS2;
BO_TX_BU_ 1241 : EMS_PHEV,PDCS1,PDCS2;
BO_TX_BU_ 1521 : EMS_ICE,EMS_PHEV,PDCS1,PDCS2;
CM_ BO_ 1064 "捷途新增(信号路由)";
CM_ BO_ 1315 "PT-DK";
CM_ BO_ 1818 "8~64字节自适应";
CM_ BO_ 1843 "8~64字节自适应";
CM_ BO_ 1946 "8~64字节自适应";
CM_ BO_ 1971 "8~64字节自适应";
CM_ BO_ 2019 "8~64Byte自适应";
CM_ SG_ 754 EMS_26_CRC1 "Profile1A:E2E CRC (SAE J1850 CRC-8) for 8 Bytes
DataID:0x0090";
CM_ SG_ 754 EMS_26_RollgCntr1 "Profile1A:E2E Rolling message counter(the maximum value of Alive counter is 14)";
CM_ SG_ 754 EMS_26_Resd1 "Profile1A:E2E Reserved";
CM_ SG_ 754 BaroPressureAbsolute "Barometric Pressure Absolute
环境压力";
CM_ SG_ 754 EngineDragTorq "Engine drag Torque capability: minimum Torque(fuel off)
倒拖扭矩";
CM_ SG_ 754 EngineTorqMax "Maximum predicted engine Torque capacity
发动机最大扭矩";
CM_ SG_ 754 EngineTorqMin "Engine Torque capability: minimum run Torque (fuel on)
发动机最小扭矩";
CM_ SG_ 754 BaroPressureAbsoluteValid "环境压力有效位Barometric Pressure Absolute Validity";
CM_ SG_ 777 ISGF_ErrLvl "前发电机故障等级Error Level";
CM_ SG_ 782 RMCU_6_CRC "Profile1A:E2E CRC (SAE J1850 CRC-8) for 8 Bytes
DataID:No ASIL requirements.Not configure
CRC Reserved.";
CM_ SG_ 782 RMCU_6_RollgCntr "Profile1A:E2E Rolling message counter(the maximum value of Alive counter is 14)";
CM_ SG_ 782 RMCU_6_Resd "Profile1A:E2E Reserved";
CM_ SG_ 782 RMCU_6_Ratio "新增后驱动电机控制器速比（捷途使用）Gearbox Ratio";
CM_ SG_ 782 TCUR_SubFaultFlag "新增TCUR转发信号
TCUR子故障";
CM_ SG_ 782 TCUR_ActrFailrSt "新增TCUR转发信号
TCUR应用层故障状态";
CM_ SG_ 786 ISGF_GateDrvSt "前发电机驱动状态state of gate driver";
CM_ SG_ 808 RMCU_2_CRC1 "Profile1A:E2E CRC (SAE J1850 CRC-8) for 8 Bytes
DataID:0x005B";
CM_ SG_ 808 RMCU_2_RollgCntr1 "Profile1A:E2E Rolling message counter(the maximum value of Alive counter is 14)";
CM_ SG_ 808 RMCU_2_Resd1 "Profile1A:E2E Reserved";
CM_ SG_ 808 RMCU_2_InverterTemperature "后驱动电机逆变器结温温度Current temperature of inverter";
CM_ SG_ 808 RMCU_2_StatorTemperature "后驱动电机定子温度Temperature of stator";
CM_ SG_ 808 RMCU_Ratio "后驱动电机控制器速比(股份使用，捷途不使用)Gearbox Ratio";
CM_ SG_ 808 RMCU_InvSampTemperature "后驱动电机控制器逆变器温度Current temperature of inverter";
CM_ SG_ 808 RMCU_2_CRC2 "Profile1A:E2E CRC (SAE J1850 CRC-8) for 8 Bytes
DataID:No ASIL requirements.Not configure
CRC Reserved.";
CM_ SG_ 808 RMCU_2_RollgCntr2 "Profile1A:E2E Rolling message counter(the maximum value of Alive counter is 14)";
CM_ SG_ 808 RMCU_2_Resd2 "Profile1A:E2E Reserved";
CM_ SG_ 808 RMCU_2_MaxHeatSpeed "RMCU motor heat speed";
CM_ SG_ 808 RMCU_2_MaxHeatTorque "Electric machine maximum heat torque";
CM_ SG_ 808 RMCU_immoResult "捷途目前不使用MCU immo 认证结果,
0:未配置，1：认证通过，2：认证失败，3：认证中，4：未进行认证(如OFF状态下)";
CM_ SG_ 884 WPump3Duty "Motor Use Water Pump Duty
电机用电子水泵工作占空比";
CM_ SG_ 884 CoolingFanDuty "CoolingFan Working Duty
冷却风扇工作占空比";
CM_ SG_ 1022 FLZCU_CarMode "整车模式";
CM_ SG_ 1034 HCU_1_G_CRC1 "Profile1A:E2E CRC (SAE J1850 CRC-8) for 8 Bytes
DataID:0x009A";
CM_ SG_ 1034 HCU_1_G_RollgCntr1 "Profile1A:E2E Rolling message counter(the maximum value of Alive counter is 14)";
CM_ SG_ 1034 HCU_1_G_Resd1 "Profile1A:E2E Reserved";
CM_ SG_ 1034 HCU_EmPwr "E-Motor power indication";
CM_ SG_ 1034 HCU_PwrTrnModeDisp "Powertrain mode for displaying energy flow";
CM_ SG_ 1034 HCU_IntelligentPowerSupply "Intelligent Power Supply For small battery";
CM_ SG_ 1034 HCU_PowerModeFed "Power mode Feedback";
CM_ SG_ 1034 HCU_LimpHomeMode "HCU sends limphome function indication to ICM   REEV Only, for dual-clutch problem";
CM_ SG_ 1034 HCU_PowertrainFault "Powertrain fault";
CM_ SG_ 1034 HCU_PowerModeChangeFail "(Once triggered,send 5 frames 'Active 'immediately, then send 'No active')";
CM_ SG_ 1034 BMSH_MILReq "0x40A MIL request";
CM_ SG_ 1034 TMF_EngMilLampReq "MIL lamp on request(TMF)";
CM_ SG_ 1034 TMR_EngMilLampReq "MIL lamp on request(TMR)";
CM_ SG_ 1034 HCU_MILReq "MIL lamp on request(HCU)";
CM_ SG_ 1034 HCU_HVReady "HV Ready indication";
CM_ SG_ 1034 HCU_PTReady "Drive Ready indication";
CM_ SG_ 1034 HCU_ChargingSts "charge status";
CM_ SG_ 1034 HCU_PtSts "动力运行状态";
CM_ SG_ 1034 HCU_InHbStrtRes "禁止启动的原因";
CM_ SG_ 1044 HCU_RangeAval "Range Available";
CM_ SG_ 1044 HCU_EnergyFlow "Energy Flow（股份信号D01不使用)";
CM_ SG_ 1044 HCU_ReplaceWarmupCycle "Replace warm-up cycle 替代暖机循环（股份信号D01不使用)";
CM_ SG_ 1044 HCU_CLMOBDClearReq "Mode $04 clear OBD information request flag
当有$04 清故障码服务时，HCU周期发送0x1 Request，当收到CLM反馈的清故障码状态完成时，再发0x0 No Request（股份信号D01不使用)";
CM_ SG_ 1044 HCU_2_G_ChgIncOper "Charge Increasing Operation";
CM_ SG_ 1044 HCU_2_G_ChgDepOper "Charge Depleting Operation";
CM_ SG_ 1044 HCU_SocManageFed_414h "Soc Manage Feedback（股份信号D01不使用)";
CM_ SG_ 1044 HCU_SetSOCFed "Set SOC Feedback";
CM_ SG_ 1044 HCU_EnergyFlowREEV "REEV Energy Flow增程器能量流";
CM_ SG_ 1044 HCU_EmissionDetection "排放检测模式状态";
CM_ SG_ 1044 HCU_2_G_IntrptGpfRgtvSt "Interrupt GPF Regenerativestate";
CM_ SG_ 1044 HCU_2_G_LowBatteryInfo "0x1:No Request  无需显示
0x2:Request  弹窗提示动力电池电量过低，请立即插枪充电或切换到Ready充电（股份信号D01不使用)
0x3:Sail Request 航行模式下的低电量提示";
CM_ SG_ 1044 HCU_2_G_LowBatteryLowFuelInfo "No Request 无需显示
Request 弹窗提示“油量电量均过低，请立即加油或充电”（股份信号D01不使用)";
CM_ SG_ 1044 HCU_2_G_HighTempLimit "未限速
高温限速（股份信号D01不使用)";
CM_ SG_ 1057 VCU_shfChk "上报N档文字提醒信息";
CM_ SG_ 1057 VCU_PowerLimitSOCLow "上报低电量提醒信息";
CM_ SG_ 1057 VCU_MCU_MilLampReq "上报防盗认证提醒信息";
CM_ SG_ 1057 VCU_OPDinfo "上报单踏板退出信息";
CM_ SG_ 1057 VCU_ePTDrvPowerPcent "上报功率占比信息";
CM_ SG_ 1057 VCU_TowingMode "上报拖车模式提醒信息";
CM_ SG_ 1057 VCU_EgyRegenLevelHighAllowed "强回收按钮是否可用";
CM_ SG_ 1057 VCU_SportDriveModeAvailable "运动驾驶模式是否可用";
CM_ SG_ 1057 VCU_RainSnowDriveModeAvailable "雨雪驾驶模式是否可用";
CM_ SG_ 1057 VCU_OffRoadDriveModeAvailable "越野模式是否可用";
CM_ SG_ 1057 VCU_CampAvailable "露营模式可用状态";
CM_ SG_ 1057 VCU_DisChgSOCHighLim "提供整车对外放电SOC调节上限";
CM_ SG_ 1057 VCU_DisChgSOCLowLim "提供整车对外放电SOC调节下限";
CM_ SG_ 1057 VCU_ChgSocSetFed "SOC设置反馈";
CM_ SG_ 1057 VCU_EngyConsuPer10Km "最近行驶10Km换算的平均百公里电耗";
CM_ SG_ 1057 VCU_EngyConsuPer25Km "最近行驶25Km换算的平均百公里电耗";
CM_ SG_ 1057 VCU_EngyConsuPer50Km "最近行驶50Km换算的平均百公里电耗";
CM_ SG_ 1057 VCU_EngyConsuPer100m "最近行驶100m换算的平均百公里电耗";
CM_ SG_ 1057 VCU_DisChrgPwr "对外供电功率";
CM_ SG_ 1057 VCU_BookChrgSetFailRes "预约失败原因反馈";
CM_ SG_ 1057 VCU_BookChrgFailRes "无法进入预约充电原因反馈";
CM_ SG_ 1057 VCU_HVILFault "高压互锁状态";
CM_ SG_ 1057 VCUExtendRang "极致节能模式增加里程值";
CM_ SG_ 1057 VCU_KeepWarmFailReason "保温失败原因";
CM_ SG_ 1057 VCU_ExtremeEnergySavingModeAv "极致节能模式状态";
CM_ SG_ 1057 VCU_TowModeAvailable "拖车模式是否可用";
CM_ SG_ 1057 VCU_StopModeSWStsResp "停止模式状态开关反馈";
CM_ SG_ 1057 VCU_StopModeSWAllowed "停止模式状态开关是否可用反馈";
CM_ SG_ 1057 VCU_ChgDisChgLedCtrl "车辆充电指示灯控制状态";
CM_ SG_ 1057 VCU_CPMaxVolt "慢充桩CP电压";
CM_ SG_ 1057 VCUExtremeEnergySavingModeReq "极致节能模式请求";
CM_ SG_ 1057 VCU_EpedalModeSts "E-Pedal实际开启/关闭状态";
CM_ SG_ 1057 VCU_BookChrgStsFb "预约充电状态";
CM_ SG_ 1057 VCU_HVNM "高压维持网络";
CM_ SG_ 1057 VCU_DriveMode "Driving modes";
CM_ SG_ 1057 HCU_EnterForceEVFailRes "不允许进入强制纯电模式原因";
CM_ SG_ 1057 HCU_EngineSelfMaintain "增程发动机自启维护";
CM_ SG_ 1057 HCU_EnterForceChrgFailRes "不允许进入强制发电模式原因";
CM_ SG_ 1057 HCU_InStartRes "无法启动的原因";
CM_ SG_ 1057 HCU_EnergyRegSetFed "能量回收强度调节设置反馈";
CM_ SG_ 1064 WorkingSts "Not_active-关闭空调
Active--打开空调
0x0:Off
0x1:On";
CM_ SG_ 1097 TMS_RMCU_MotSelfHeatLvlReq "电驱自发热档位需求";
CM_ SG_ 1097 TMS_RMCU_MotSelfHeatEnReq "电驱自发热使能开关";
CM_ SG_ 1099 ISGF_LockedRotorFlag "前发电机堵转标志位";
CM_ SG_ 1099 ISGF_StatTemp "前发电机电机温度";
CM_ SG_ 1099 ISGF_VoltageT30 "前发电机控制器KL30电压";
CM_ SG_ 1099 ISGF_SysTempOvrInd "前发电机系统过温故障灯（捷途D01不使用）";
CM_ SG_ 1099 ISGF_MotOvrSpdWarn "前发电机超速报警";
CM_ SG_ 1099 ISGF_CalOffsetAngleReq "前发电机角标请求";
CM_ SG_ 1099 ISGF_HVILFault "前发电机高压互锁故障（捷途D01不使用）";
CM_ SG_ 1099 ISGF_EngMilLampReq "前发电机MIL灯请求";
CM_ SG_ 1099 ISGF_InvTempOvrErr "前发电机控制器过温故障";
CM_ SG_ 1103 RMCU_WPhasecurrent "后电机控制器W相电流W Phase current";
CM_ SG_ 1103 RMCU_VPhasecurrent "后电机控制器V相电流V Phase current";
CM_ SG_ 1103 RMCU_UPhasecurrent "后电机控制器U相电流U Phase current";
CM_ SG_ 1103 RMCU_4_CRC "Profile1A:E2E CRC (SAE J1850 CRC-8) for 8 Bytes
DataID:0x0085";
CM_ SG_ 1103 RMCU_4_RollgCntr "Profile1A:E2E Rolling message counter(the maximum value of Alive counter is 14)";
CM_ SG_ 1103 RMCU_4_Resd "Profile1A:E2E Reserved";
CM_ SG_ 1103 RMCU_TempW "后驱动电机控制器W相温度Temperature of phase W of NTC";
CM_ SG_ 1103 RMCU_TempV "后驱动电机控制器V相温度Temperature of phase V of NTC";
CM_ SG_ 1103 RMCU_TempU "后驱动电机控制器U相温度Temperature of phase U of NTC";
CM_ SG_ 1103 RMCU_CoolantTemp "后驱动电机控制器冷却液温度Temperature of inverter cooling water";
CM_ SG_ 1103 RMCU_RotorTemp "后驱动电机控制器转子温度Temperature of rotor";
CM_ SG_ 1103 RMCU_Delta_TJ_Coolant "捷途目前不使用Temperature of Tj minus coolant";
CM_ SG_ 1103 RMCU_TMS_MotSelfHeatLvlFb "电驱自发热开启档位";
CM_ SG_ 1103 RMCU_TMS_MotSelfHeatEnSts "电驱自发热使能开关状态";
CM_ SG_ 1103 RMCU_IGBTmode "后驱动电机控制器IGBT模式Motor drive state";
CM_ SG_ 1130 TCU_23_CRC1 "Profile1A:E2E CRC (SAE J1850 CRC-8) for 8 Bytes
DataID:No ASIL requirements.Not configure
CRC Reserved.";
CM_ SG_ 1130 TCU_23_RollgCntr1 "Profile1A:E2E Rolling message counter(the maximum value of Alive counter is 14)";
CM_ SG_ 1130 TCU_23_Resd1 "Profile1A:E2E Reserved";
CM_ SG_ 1130 TCU_23_ErrLever "换挡故障等级（T1J FL2智驾版3DHT新增故障等级5）";
CM_ SG_ 1130 TCU_23_GBFaultstatus "换挡故障状态";
CM_ SG_ 1130 TCU_23_STAT_LeverModeDisp "换挡杆位置显示（T1J FL2智驾版3DHT使用）";
CM_ SG_ 1130 TCU_23_GBWarmUpReq "变速箱暖机请求（T1J FL2智驾版3DHT使用）";
CM_ SG_ 1130 TCU_23_TeachInState "TCU自学习状态";
CM_ SG_ 1130 TCU_23_CluSelfLrng "离合器自学习状态（T1J FL2智驾版3DHT使用）";
CM_ SG_ 1136 VCC_3_CRC "Profile1A:E2E CRC (SAE J1850 CRC-8) for 32 Bytes
DataID:0x0070";
CM_ SG_ 1136 VCC_3_RollgCntr "Profile1A:E2E Rolling message counter(the maximum value of Alive counter is 14)";
CM_ SG_ 1136 VCC_3_Resd1 "Profile1A:E2E Reserved";
CM_ SG_ 1136 VCC_3_SN "Message ID信号值.当VCC成功被写入配置信息时，VCC以100ms的周期滚动发送报文，Message ID信号值从1到32循环发送。";
CM_ SG_ 1162 VehicleSpeedVSOSig "Vehicle Speed";
CM_ SG_ 1162 VehicleSpeedVSOSigValidData "Valid check bit of the signal VehicleSpeedVSOSig";
CM_ SG_ 1163 FMCU_DHT_TempStatus "DHT变速箱温度状态";
CM_ SG_ 1163 FMCU_DHT_OvTempEngMilLampReq "DHT过温请求点亮MIL故障灯";
CM_ SG_ 1163 FMCU_DHT_OilTempFlag "DHT变速箱油温信号有效标志";
CM_ SG_ 1163 FMCU_DHT_Oil_Temp "DHT变速箱油温";
CM_ SG_ 1166 RMCU_FailCode1 "后驱动电机故障码1";
CM_ SG_ 1166 RMCU_FailCode2 "后驱动电机故障码2";
CM_ SG_ 1166 RMCU_FailCode3 "后驱动电机故障码3";
CM_ SG_ 1166 RMCU_FailCode4 "后驱动电机故障码4";
CM_ SG_ 1177 FuelTankLidSts "加油小门开关状态";
CM_ SG_ 1177 FuelTankLidLockFailureSts "加油小门门锁故障状态";
CM_ SG_ 1177 FuelTankLidSensorFailureSts "油箱门位置传感器故障信号";
CM_ SG_ 1177 FuelTankLidSWFailureSts "加油小门硬开关故障状态";
CM_ SG_ 1202 EngineCoolantTemperture "Engine Coolant Temperture
发动机冷却液温度";
CM_ SG_ 1202 FuelRollingCounter "Instantaneous fuel consumption pulse signal
瞬时油耗脉冲信号";
CM_ SG_ 1202 EngineSpeed "Engine Speed
PHEV上此信号发送真实转速（给BCM使用）";
CM_ SG_ 1202 MILSts "MIL Status
MIL灯状态";
CM_ SG_ 1202 IEMSts "IEM Status
IEM状态";
CM_ SG_ 1202 GPFWarning "This signal indicates the status of GPF warning which need ICM to  inform driver. 
0x1: Green light, may display 'GPF is full. Need  highspeed road drive to clean GPF”
0x2: Yellow light, may display'GPF is overlimited. Need to contact 4s to check and repair GPF'
GPF报警灯";
CM_ SG_ 1202 EngineCoolantTempertureFailSts "Valid check bit of the signal EngineCoolantTemperture
发动机冷却液温度故障状态";
CM_ SG_ 1202 FuelRollingCounterValidData "Valid check bit of the signal FuelRollingCounter
瞬时油耗有效位";
CM_ SG_ 1202 EngineSpeedValidData "Valid check bit of the signal EngineSpeed
发动机转速有效位";
CM_ SG_ 1202 EPCSts "EPC status
EPC状态";
CM_ SG_ 1202 EMS_1_G_EngineSts "Engine Status
If this value is 1, indicate that  the engine is started successfully. 
在PHEV上，此信号发送模拟的发动机状态；";
CM_ SG_ 1202 EMS_EngineSts_Actual "PHEV上，根据发动机真实的状态发送";
CM_ SG_ 1202 OilPressureWarningLamp "Oil Pressure Worning Lamp
机油压力报警灯";
CM_ SG_ 1204 VCU_1_G_CRC "Profile1A:E2E CRC (SAE J1850 CRC-8) for 8 Bytes
DataID:0x005C";
CM_ SG_ 1204 VCU_1_G_RollgCntr "Profile1A:E2E Rolling message counter(the maximum value of Alive counter is 14)";
CM_ SG_ 1204 VCU_1_G_Pwr "instant power（股份信号D01未使用）";
CM_ SG_ 1204 VCU_1_G_AcceleratorPosRaw "真实油门开度
Raw position of the accelerator pedal (unfiltered). Represents always raw pedal position without any other influcence only mandatory to calculated gradient acceleration pedal.";
CM_ SG_ 1204 VCU_1_G_PTReady "PT Ready indication";
CM_ SG_ 1204 VCU_1_G_DriveMode "Driving modes（股份信号D01未使用）";
CM_ SG_ 1204 VCU_1_G_HvBattKeepWarmSts "插枪保温状态";
CM_ SG_ 1204 VCU_1_G_HvBattKeepWarmActiveReq "插枪保温开启请求";
CM_ SG_ 1204 VCU_1_G_HundECAver "average consumption per hundred KM（股份信号D01未使用）";
CM_ SG_ 1204 VCU_1_G_BookChrgSetStsFb "预约充电设置与否状态反馈";
CM_ SG_ 1204 VCU_1_G_EgyRegenLevel "power regeneration level（股份信号D01未使用）";
CM_ SG_ 1204 VCU_1_G_PRNDGearAct "Gear indication";
CM_ SG_ 1207 WPump3Duty_FB "Water Pump3 Duty Feedback
电机水泵3工作占空比反馈";
CM_ SG_ 1207 WPump3FltSt "Water Pump3 Fail Status
电机水泵3故障状态";
CM_ SG_ 1207 CoolingFanFlt "Cooling Fan Fail Status
冷却风扇故障状态（捷途不发，预留）";
CM_ SG_ 1213 PID04_LoadValueCalculated "发动机负载";
CM_ SG_ 1213 PID11_AbsoluteThrottlePosition "绝对节气门位置";
CM_ SG_ 1213 LoadValueCalculatedValidData "发动机负载有效位";
CM_ SG_ 1213 AbsoluteThrottlePosValidData "绝对节气门位置有效位";
CM_ SG_ 1213 OBD_DrivingCycle "DrivingCycle 驾驶循环";
CM_ SG_ 1213 OBD_WarmupCycle "暖机循环";
CM_ SG_ 1213 OBD_PermanentFailureCycle "永久故障码清除";
CM_ SG_ 1213 OBD_IgnCycle "发动机点火循环";
CM_ SG_ 1213 OBD_GeneralDenomiantor "通用分母";
CM_ SG_ 1213 OBD_GeneralDenomiantorFreeze "通用分母冻结";
CM_ SG_ 1213 EMS_28_GpfRgtvSt "GPF状态信号
0为初始值
1为再生过程中
2为意外退出
3为再生已完成";
CM_ SG_ 1241 EMS_4_G_EngineSpeed_Actual "PHEV:Actual Engine speed";
CM_ SG_ 1241 LegisDiagStdardCnditionMet "Legislated Diagnostics Standard Conditions Met
符合法定诊断标准条件";
CM_ SG_ 1241 EMS_4_G_Pump_SpeedSts "发动机水泵转速实时占空比反馈";
CM_ SG_ 1241 FuelTankLidLockReq "加油小门门锁上锁请求";
CM_ SG_ 1241 FuelTankLidSystemFailureSts "加油小门系统故障信号";
CM_ SG_ 1241 FuelTankPressureConditionReached "油箱压力状态信号";
CM_ SG_ 1241 LegisDiagStdardCnditionFltPresnt "Legislated Diagnostics Standard Conditions Fault Present立法诊断标准条件故障存在";
CM_ SG_ 1241 OilPressure_4D9h "机油压力相对压力";
CM_ SG_ 1241 EMS_4_G_KL15Sts "EMS KL15 Status indicator";
CM_ SG_ 1252 TotalOdometer_km_OBD "GB18285-2018新增OBD输出检查要求车辆累积行驶里程信号。";
CM_ SG_ 1296 CurrentTimeYear "时间（年)";
CM_ SG_ 1296 CurrentTimeMonth "时间（月）";
CM_ SG_ 1296 CurrentTimeDay "时间（日）";
CM_ SG_ 1296 CurrentTimeHour "时间（时）";
CM_ SG_ 1296 CurrentTimeMinute "时间（分）";
CM_ SG_ 1296 CurrentTimeSecond "时间（秒）";
CM_ SG_ 1307 RMCU_TotalFaultNum_51Bh "当前故障总数";
CM_ SG_ 1307 RMCU_FrameIndex_51Bh "帧序号";
CM_ SG_ 1307 RMCU_SupplierNum_51Bh "供应商代码";
CM_ SG_ 1307 RMCU_FaultNum1_51Bh "故障列表1";
CM_ SG_ 1307 RMCU_FaultNum2_51Bh "故障列表2";
CM_ SG_ 1307 RMCU_FaultNum3_51Bh "故障列表3";
CM_ SG_ 1307 RMCU_FaultNum4_51Bh "故障列表4";
CM_ SG_ 1307 RMCU_FaultNum5_51Bh "故障列表5";
CM_ SG_ 1307 RMCU_FaultNum6_51Bh "故障列表6";
CM_ SG_ 1307 RMCU_FaultNum7_51Bh "故障列表7";
CM_ SG_ 1307 RMCU_FaultNum8_51Bh "故障列表8";
CM_ SG_ 1307 RMCU_FaultNum9_51Bh "故障列表9";
CM_ SG_ 1307 RMCU_FaultNum10_51Bh "故障列表10";
CM_ SG_ 1307 RMCU_FaultNum11_51Bh "故障列表11";
CM_ SG_ 1307 RMCU_FaultNum12_51Bh "故障列表12";
CM_ SG_ 1307 RMCU_FaultNum13_51Bh "故障列表13";
CM_ SG_ 1307 RMCU_FaultNum14_51Bh "故障列表14";
CM_ SG_ 1307 RMCU_FaultNum15_51Bh "故障列表15";
CM_ SG_ 1307 RMCU_FaultNum16_51Bh "故障列表16";
CM_ SG_ 1307 RMCU_FaultNum17_51Bh "故障列表17";
CM_ SG_ 1307 RMCU_FaultNum18_51Bh "故障列表18";
CM_ SG_ 1307 RMCU_FaultNum19_51Bh "故障列表19";
CM_ SG_ 1307 RMCU_FaultNum20_51Bh "故障列表20";
CM_ SG_ 1314 HCU_CRC1_522h "Profile1A:E2E CRC (SAE J1850 CRC-8) for 8 Bytes
DataID:Reserved";
CM_ SG_ 1314 HCU_RollgCntr1_522h "Profile1A:E2E Rolling message counter(the maximum value of Alive counter is 14)";
CM_ SG_ 1314 HCU_V2lDisChgBck "V2L外放电开关反馈";
CM_ SG_ 1314 HCU_DisChgMemFed "V2L外放电记忆开关反馈";
CM_ SG_ 1314 HCU_V2VDisChgBck "V2V放电开关反馈";
CM_ SG_ 1314 HCU_V2l_IntlDisChgBck "V2L内放电开关反馈";
CM_ SG_ 1314 HCU_FuelDetnOpDefeated "燃油检测开启失败提示";
CM_ SG_ 1314 HCU_FuelDetnModSwtFed "燃油检测开关反馈";
CM_ SG_ 1314 HCU_FuelDetnStateFed "燃油检测模式状态反馈";
CM_ SG_ 1314 HCU_HVDownRepairModeFed "断高压维修模式开关反馈";
CM_ SG_ 1314 HCU_SumFuCns "自清零后累计百公里油耗显示(仅仪表使用)";
CM_ SG_ 1314 HCU_TrailerMode "被拖模式开关反馈";
CM_ SG_ 1314 HCU_TABSwtFed_522h "ICC坦克转向开关反馈
0x0:Not_Active 使能位
0x1:Active 激活
0x2:Stand_by 就绪
0x3:Failed 失败";
CM_ SG_ 1314 HCU_MotSelfHeatLvlReq "电驱自发热档位需求";
CM_ SG_ 1314 HCU_MotSelfHeatEnReq "电驱自发热使能开关";
CM_ SG_ 1314 HCU_KeyDriveModememory "驾驶模式记忆开关反馈";
CM_ SG_ 1314 HCU_DrivePowerDispSetFed "驱动系统功率显示方式开关反馈";
CM_ SG_ 1314 HCU_TCMStsReq_522h "TCM使能状态";
CM_ SG_ 1314 HCU_EXPERTNormFed "专家模式动力设置标准模式开关反馈";
CM_ SG_ 1314 HCU_4LModeFed "低速四驱开关反馈";
CM_ SG_ 1314 HCU_EXPERTEcoFed "专家模式动力设置柔和模式开关反馈";
CM_ SG_ 1314 HCU_SingleRegnRmn "当车机收到HCU发送信号“HCU_SingleRegnRmn =0x1”时，弹框提示“单踏板受限已退出，请注意安全驾驶！”，并播放报警音持续3s；
当车机收到HCU发送信号“HCU_SingleRegnRmn=0x0”时，停止提示，并停止报警音；";
CM_ SG_ 1314 HCU_DRIFTModeSts "通过大屏设置漂移模式灵敏度开关反馈
0x0:不动作
0x1:入门
0x2:大师
0x3:专家";
CM_ SG_ 1314 HCU_CRC2_522h "Profile1A:E2E CRC (SAE J1850 CRC-8) for 8 Bytes
DataID:Reserved";
CM_ SG_ 1314 HCU_RollgCntr2_522h "Profile1A:E2E Rolling message counter(the maximum value of Alive counter is 14)";
CM_ SG_ 1314 HCU_EXPERTAWDFed "专家模式驱动形式四驱开关设置反馈";
CM_ SG_ 1314 HCU_EXPERTRWDFed "专家模式驱动形式后驱开关设置反馈";
CM_ SG_ 1314 HCU_CrossaxisFed "专家模式交叉轴模式开关设置反馈";
CM_ SG_ 1314 HCU_EXPERTSportFed "专家模式动力设置激进模式开关反馈";
CM_ SG_ 1314 HCU_StopChrgnModeFed "驻车发电模式开关反馈";
CM_ SG_ 1314 HCU_StopChrgnFed "驻车发电开关反馈";
CM_ SG_ 1314 HCU_CLIMBFed "防溜设置开关反馈";
CM_ SG_ 1314 HCU_EXPERTAutoFed "专家模式驱动形式Auto开关设置反馈";
CM_ SG_ 1314 HCU_HEV_FunctionLimit "仪表文字提示“HEV模式不可用”";
CM_ SG_ 1314 HCU_ParkingChargeReminder "仪表文字提示“请先驻车再充电”";
CM_ SG_ 1314 HCU_PowerCut "仪表文字提示“动力即将切断，请靠边停车”";
CM_ SG_ 1314 HCU_IMMOReleaseSignal "防盗报警指示灯信号";
CM_ SG_ 1314 HCU_LVPowSupSYSAbn_lit "低压供电系统异常状态";
CM_ SG_ 1314 HCU_ChrgnFctMemSt "强制保电记忆开关反馈";
CM_ SG_ 1314 HCU_PowerModeChangeInhibit "仪表文字提示“为保障越野性能，模式无法切换”";
CM_ SG_ 1314 HCU_DisconnectChagWarn "仪表文字提示“请拔下充电枪”";
CM_ SG_ 1314 HCU_EngineRunClmReq "仪表文字提示“空调请求发动机运行中”";
CM_ SG_ 1314 HCU_VehicleSpeedMax_Limit "仪表文字提示“最高车速受限，请尽快联系售后检修”";
CM_ SG_ 1314 HCU_AccleAbility_Limit "仪表文字提示“加速性能受限，请尽快联系售后检修”";
CM_ SG_ 1314 HCU_DriveInhibit_GearP "仪表文字提示“动力受限，进入P挡后无法再次行驶，请尽快联系售后检修”";
CM_ SG_ 1314 HCU_SetModeNotChange "仪表文字提示“模式禁止切换”";
CM_ SG_ 1314 HCU_UTURNSnowFed "极限调头雪地场景反馈";
CM_ SG_ 1314 HCU_PowerLevel "仪表驱动能力等级";
CM_ SG_ 1314 HCU_TowingModeEna "大屏被拖提醒文字提示ICC接收
0x1时，大屏文字提示“切换至被拖模式需满足以下条件：1、挡位处于P挡；2、踩下刹车；3、车辆不在充电状态”";
CM_ SG_ 1314 HCU_LeaveVehicleWarning "仪表声音提醒";
CM_ SG_ 1314 HCU_DedicatedModeInhibit "仪表文字提示“当前模式不可用，请切换至越野模式”";
CM_ SG_ 1314 HCU_DisChargeStopFault "0x1时仪表文字提示“电池电量过低，放电停止”0x2时仪表文字提示“燃油不足，放电停止”";
CM_ SG_ 1314 HCU_RearEDLSts "后差速锁状态
0x0:不锁
0x1:解锁
0x2:锁止
0x3:切换提醒
0x4:不满足锁止条件
0x5:差速锁无法锁止故障
0x6:差速锁无法解锁故障";
CM_ SG_ 1314 HCU_FrntEDLSts "前差速锁状态
0x0: 不锁
0x1: 解锁
0x2：锁止
0x3：切换提醒
0x4：不满足锁止条件
0x5：差速锁无法锁止故障
0x6：差速锁无法解锁故障
0x7：提示需挂入后锁和4L
0x8：提示开启后锁
0x9：提示开启4L";
CM_ SG_ 1314 HCU_CRC3_522h "Profile1A:E2E CRC (SAE J1850 CRC-8) for 8 Bytes
DataID:Reserved";
CM_ SG_ 1314 HCU_RollgCntr3_522h "Profile1A:E2E Rolling message counter(the maximum value of Alive counter is 14)";
CM_ SG_ 1314 HCU_CruiseLimitSpeedValue "定速巡航设定车速";
CM_ SG_ 1314 HCU_DriveMode_JT "驾驶模式反馈
0x0:经济
0x1:标准
0x2:运动
0x3:雪/草地
0x4:泥地
0x5:越野
0x6:沙地
0x7:岩石
0x8:专家
0x9:智能
0xA:涉水
0xB:极限掉头
0xC:漂移
0xD:拖挂
0xE:越野竞速
0xF:晕车舒缓
0x10:智慧能量管理
0x11:纵横征服
0x12~0x1F：预留";
CM_ SG_ 1314 HCU_SocManageFed "Soc_Manage_Feedback";
CM_ SG_ 1314 HCU_SinglePedalMemFed "单踏板记忆开关反馈";
CM_ SG_ 1314 HCU_CCOSwtFed "越野蠕行开关反馈";
CM_ SG_ 1314 HCU_Pwr "instant_power";
CM_ SG_ 1314 HCU_UTURNSandFed "极限调头泥地场景开关反馈";
CM_ SG_ 1314 HCU_CruiseControlStatus "定速巡航指示灯";
CM_ SG_ 1314 HCU_EXPERTEESPSet "关闭牵引力控制系统&车身稳定控制系统（TCS&VDC_OFF）
全开（TCS、VDC等与ESP有关功能全部开启）
全关（TCS、VDC及RMI放侧翻、DTC发动机拖滞力矩管理）";
CM_ SG_ 1314 HCU_EgyRegenLevel "power_regeneration_level";
CM_ SG_ 1314 HCU_CRC4_522h "Profile1A:E2E CRC (SAE J1850 CRC-8) for 8 Bytes
DataID:0x0114";
CM_ SG_ 1314 HCU_RollgCntr4_522h "Profile1A:E2E Rolling message counter(the maximum value of Alive counter is 14)";
CM_ SG_ 1314 HCU_EngyFlowToDisp "0x0:初始化
0x1:无能量流状态
0x2:发动机单独运行
0x3:纯电前驱
0x4:纯电前驱回馈
0x5:纯电后驱
0x6:纯电后驱回馈
0x7:纯电四驱
0x8:纯电四驱回馈
0x9:串联前驱电池充电
0xA:串联前驱电池放电
0xB:串联前驱电池无电流
0xC:串联前驱回馈
0xD:串联后驱电池充电
0xE:串联后驱电池放电
0xF:串联后驱电池无电流
0x10:串联后驱回馈
0x11:串联四驱电池充电
0x12:串联四驱电池放电
0x13:串联四驱电池无电流
0x14:串联四驱回馈
0x15:并联前驱电池充电
0x16:并联前驱电池放电
0x17:并联前驱电池无电流
0x18:并联前驱回馈
0x19:并联四驱电池充电
0x1A:并联四驱电池放电
0x1B:并联四驱电池无电流
0x1C:并联四驱回馈
0x1D:原地发电电池充电
0x1E:原地发电电池放电
0x1F:原地发电电池无电流";
CM_ SG_ 1314 HCU_UTURNGrassFed "极限调头草地场景反馈";
CM_ SG_ 1314 HCU_UTURNMudFed "极限调头沙地场景开关反馈";
CM_ SG_ 1314 HCU_LTCDispFed "续航里程选择开关反馈";
CM_ SG_ 1314 HCU_iTAS_Warn "0x0: 无提示
0x1:iTAS功能已激活，无法锁止后桥差速锁
0x2:请释放EPB
0x3:当前车速过高，请减速
0x4：制动盘温度过高，极限掉头功能已退出
0x5：车辆被卡住，极限掉头功能退出
0x6：极限掉头使用时间到达极限，功能退出
0x7：请切换至D档开启极限掉头";
CM_ SG_ 1314 HCU_iCCO_Warn "0x0: 无提示
0x1:请释放EPB
0x2:当前车速过高，请减速
0x3:请关好车门，系好安全带
0x4:请切换至D档或N档开启越野蠕行
0x5:请关闭 APA/ACC/CC巡航
0x6:请退出HDC陡坡缓降/自动驻车
0x7:请手动切换驾驶模式至雪地或泥地或沙地或岩石
0x8:请踩制动踏板
0x9:iCCO越野蠕行已退出";
CM_ SG_ 1314 HCU_DriveModeChangeFail "驾驶模式切换不满足条件，提示“请停车后退出当前驾驶模式”";
CM_ SG_ 1314 HCU_25_Crossaxis_Warn "0x0: 无提示
0x1:请释放EPB
0x2:当前车速过高，交叉轴功能已退出
0x3:请切换至D档开启交叉轴功能
0x4:请关好车门，系好安全带
0x5:请将车辆静止后踩制动踏板
0x6:进入交叉轴模式后进行空簧高度调节";
CM_ SG_ 1314 HCU_25_EDLFed "中央差速锁显示信号";
CM_ SG_ 1314 HCU_DraggingModeRemind "0x0: 无提示
0x1:禁用ECO和越野模式
0x2:拖挂模式下仅支持Normal和Sport
0x3:ECO和越野模式恢复
0x4~0x7:预留";
CM_ SG_ 1314 HCU_iTASSceneReq "iTAS场景选择信息";
CM_ SG_ 1314 HCU_25_iTAS_SlopWarn "极限调头坡度条件不满足提醒
0x0:无提示
0x1:地面坡度过大
0x2~0x3:Reserved";
CM_ SG_ 1314 HCU_ExterTempLowHint "0x0:无提示
0x1:环境温度低切换为HEV模式
0x2:环境温度过低发动机运行中";
CM_ SG_ 1314 HCU_iTAS_Active "极限掉头激活状态（仪表）";
CM_ SG_ 1314 HCU_25_VehSpdOffroadRmn "漂移，掉头，专家，交叉轴，越野蠕行，越野竞速功能，用户在车辆未静止状态下点退出按钮或硬开关，仪表接收该信号0x1后显示“请将车辆禁止后再设置”";
CM_ SG_ 1314 HCU_DrivingModReq "HCU给IPB映射驾驶模式";
CM_ SG_ 1314 HCU_25_ADS_FctSts "智能驾驶功能激活状态";
CM_ SG_ 1314 HCU_25_DRIFTModeSetReq "漂移灵敏度开启信号(HCU判断完成后外发)";
CM_ SG_ 1314 HCU_25_CrossaxisReq "交叉轴开启信号(HCU判断完成后外发)";
CM_ SG_ 1314 HCU_25_CCOSwtReq "CCO开启信号(HCU判断完成后外发)";
CM_ SG_ 1314 HCU_CRC5_522h "Profile1A:E2E CRC (SAE J1850 CRC-8) for 8 Bytes
DataID:Reserved";
CM_ SG_ 1314 HCU_RollgCntr5_522h "Profile1A:E2E Rolling message counter(the maximum value of Alive counter is 14)";
CM_ SG_ 1314 HCU_25_ErrorCode "HCU接收各控制器故障等级后处理的故障码";
CM_ SG_ 1314 HCU_25_ErrorCount "用于上报当前HCU故障总数";
CM_ SG_ 1314 HCU_25_iDRIFT_Warn "0x0:无提示
0x1:请关好车门，系好安全带
0x2:请将车辆停止
0x3:系统故障，漂移模式暂无法开启
0x4:进入漂移模式后进行空簧高度调节";
CM_ SG_ 1314 HCU_25_SetVehSpdOffroad "越野模式切换车速条件不满足提示
0x0:无提示
0x1:请将车辆静止后再设置
0x2~0x3:Reserved";
CM_ SG_ 1314 HCU_25_LaunchMod_Warn "越野竞速弹射模式弹窗提示
0x0:无提示
0x1:弹射模式已激活，松开制动踏板，开始弹射
0x2:弹射模式已退出
0x3:条件不满足，弹射模式不可用
0x4~0x7:Reserved";
CM_ SG_ 1314 HCU_25_TAB_Warn "TAB功能提醒(T1J FL2华为智驾使用，D01及D01华为智驾版不使用)";
CM_ SG_ 1314 HCU_25_CCO_TextDisp "CCO功能提示信息
越野蠕行功能提示
(T1J FL2华为智驾使用，D01及D01华为智驾版不使用)";
CM_ SG_ 1314 HCU_25_DCM_Warn "纵横征服功能提示
0x0:No_Warn
0x1:请释放 EPB
0x2:请关好车门,系好安全带
0x3:请切换至D/R档开启攀爬模式
0x4:请关闭APA/ACC/CC巡航
0x5:请退出HDC 陡坡缓降/AVH自动驻车
0x6:请踩制动踏板
0x7:纵横征服 已退出
0x8: 请在车辆静止时进入或退出该模式
0x9:功率限制，功能无法正常使用
0xA: 请丢开加速踏板
0xB:请踩制动
0xC~0xF:Reserved";
CM_ SG_ 1314 HCU_25_CCMFed "攀爬设置开关反馈";
CM_ SG_ 1314 HCU_25_TABReq "HCU发送TAB功能请求(T1J FL2华为智驾使用，D01及D01华为智驾版不使用)";
CM_ SG_ 1314 HCU_SumElecCns "自清零后累计百公里电耗显示(仅仪表使用)";
CM_ SG_ 1314 HCU_CrossBorderSts "HCU 反馈飞车模式执行情况
0x1: On 表示飞车模式限制已开启
0x2: Off 表示飞车模式限制未开启";
CM_ SG_ 1314 HCU_DischgSetSOCFed "放电SOC设置状态反馈
0xFE:Abnormal
0xFF:Invalid";
CM_ SG_ 1314 HCU_facCleverDrvAct_522h "驾驶运动因子";
CM_ SG_ 1314 HCU_stCleverDrvAct_522h "智慧驾驶风格状态";
CM_ SG_ 1314 HCU_stCleverRgnAct_522h "智慧能量回收状态";
CM_ SG_ 1314 HCU_stCleverMainAct_522h "智慧能量管理状态";
CM_ SG_ 1314 EnergySavingModeSts_522h "节能模式设置反馈";
CM_ SG_ 1314 HCU_facCleverDrvActRstFed_522h "驾驶运动因子重置反馈";
CM_ SG_ 1314 HCU_SailramainingT_Indc_522h "剩余航行时间（对比）,真实显示的";
CM_ SG_ 1314 HCU_ATCM_Operation_REQ_522h "航行模式按键确认信号
0x0:Not Active
0x1:进入航行提示  Switch to sailfunc indiction
0x2:进入上滩提示Switch to upbeach indiction
0x3:陆地时点击航行物理开关误操作提示 misoperation indiction: press sailfunc sw when conenmod 
0x4:陆地时点击上滩物理开关误操作提示misoperation indiction: press upbeach  sw when conenmod 
0x5:涉水时点击上滩物理开关误操作提示misoperation indiction: press upbeach sw when wadests
0x6:reserved
0x7:reserved";
CM_ SG_ 1314 HCU_ModeSwFailureIndc_522h "模式切换失效提示
0x0: Not Active
0x1:进入航行失败：车门未关
Entry navigation failed: Car door is not closed
0x2：进入航行失败：后视镜未展开
Entry navigation failed: Rearview mirror not deployed
0x3:进入航行失败：进排气防水阀故障
Entry navigation failed: Intake and exhaust waterproof valve malfunction
0x4：进入航行失败：车速过大
Entry navigation failed: Speed too fast
0x5：进入航行失败：电量过低
Entry navigation failed: Low battery
0x6：进入航行失败：空调放水阀故障|散热风扇故障
Entry navigation failed: Air conditioning drain valve malfunction| Cooling fan malfunction";
CM_ SG_ 1314 HCU_Sailmode_522h "涉水模式
0x0:Convenmod
0x1:SalWadeSts  浅涉水
0x2:DpWadeSts 深涉水（保留）
0x3:SailingFunc  航行
0x4:UpbeachSts  上滩
0x5:WaitfinspSts 待检（保留）
0x6:EmerfloatingSts 应急浮水
0x7:Reserved2";
CM_ SG_ 1314 HCU_CarSickRelfModeFb "晕车舒缓状态反馈";
CM_ SG_ 1314 HCU_DeepSnowSts_522h "深雪模式状态信号";
CM_ SG_ 1314 DriveModeChangeFailReason_522h "驾驶模式切换失败原因提示";
CM_ SG_ 1314 HCU_CLIMBDisReason_522h "攀爬防溜设置失败原因提示
0x0:不提醒
0x1:请踩刹车上Ready
0x2:请挂入D档或N档
0x3:请切换到岩石模式
0x4:底盘限扭系统激活
0x5:请关闭智驾功能后重试
0x6:请减速后重试
0x7:驱动系统故障
0x8:纵向加速度无效
0x9:请退出越野蠕行
0xA:制动辅助不可用
0xB:IPB系统故障";
CM_ SG_ 1314 HCU_CarSickRelfModeDisReason "晕车舒缓开启失败原因
0x0:不提示
0x1:请退出越野模式
0x2:请退出越野蠕行
0X3:请退出节能模式
0X4:请退出拖挂模式
0X5:请退出被拖模式
0X6:请退出定速巡航模式
0X7:请退出智驾模式";
CM_ SG_ 1314 HCU_DCMSwtFed "纵横征服模式场景
0x0:not active
0x1:泥沙脱困
0x2:雪地暴行
0x3:攀爬挑战
0x4:丛林探路
0x5:拔河
0x6:救援
0x7:Reserved";
CM_ SG_ 1314 HCU_LightSandSts_522h "浅沙模式：
0x0:信号无作用
0x1:浅沙模式激活
0x1:浅沙模式关闭";
CM_ SG_ 1315 RMCU_2_G_InverterTemperature "后驱动电机控制器温度Current temperature of inverter";
CM_ SG_ 1315 RMCU_2_G_StatorTemperature "后驱动电机温度Temperature of stator";
CM_ SG_ 1315 RMCU_2_G_OutputTorque "后驱动电机输出扭矩Output torque which is currently provided by the electric machine";
CM_ SG_ 1315 RMCU_2_G_Speed "后驱动电机转速RMCU motor actual speed";
CM_ SG_ 1315 RMCU_2_GVoltageHV "后驱动电机控制器母线电压HV voltage at the DC/AC converter";
CM_ SG_ 1315 RMCU_2_G_CurrentHV "后驱动电机控制器母线电流HV current at the DC/AC converter";
CM_ SG_ 1338 FMCU_MotWorkState "前驱动电机工作状态";
CM_ SG_ 1403 RMCU_1_G_CRC "Profile1A:E2E CRC (SAE J1850 CRC-8) for 8 Bytes
DataID:No ASIL requirements.Not configure
CRC Reserved.";
CM_ SG_ 1403 RMCU_1_G_RollgCntr "Profile1A:E2E Rolling message counter(the maximum value of Alive counter is 14)";
CM_ SG_ 1403 RMCU_1_G_Resd "Profile1A:E2E Reserved";
CM_ SG_ 1403 RMCU_ErrLvlDis "后驱动电机控制器故障等级";
CM_ SG_ 1403 RMCU_InvTempAlarm "后驱动电机控制器过温报警";
CM_ SG_ 1403 RMCU_MotTempAlarm "后驱动电机过温报警";
CM_ SG_ 1403 RMCU_MotWorkState "后驱动电机控制器工作状态";
CM_ SG_ 1403 RMCU_MILSts "后驱动电机控制器MIL灯状态";
CM_ SG_ 1403 RMCU_Speed_EDR "后驱动电机实际转速";
CM_ SG_ 1403 RMCU_1_G_OvercurrentAlarm "后驱动电机过流故障";
CM_ SG_ 1403 RMCU_1_G_OverspeedAlarm "后驱动电机超速故障";
CM_ SG_ 1407 RMCU_Version_CRC1 "Profile1A:E2E CRC (SAE J1850 CRC-8) for 8 Bytes
DataID:No ASIL requirements.Not configure
CRC Reserved.";
CM_ SG_ 1407 RMCU_Version_RollgCntr1 "Profile1A:E2E Rolling message counter(the maximum value of Alive counter is 14)";
CM_ SG_ 1407 RMCU_Version_Resd1 "Profile1A:E2E Reserved";
CM_ SG_ 1407 RMCU_SupplierCode "后驱动电机供应商代码";
CM_ SG_ 1407 RMCU_HwVersion "后驱动电机硬件版本号";
CM_ SG_ 1407 RMCU_SwMajorVersion "后驱动电机主软件版本号";
CM_ SG_ 1407 RMCU_SwMinorVersion "后驱动电机辅软件版本号";
CM_ SG_ 1407 RMCU_SwPatchVersion "后驱动电机临时软件版本号";
CM_ SG_ 1407 TCUR_SwVersion "新增TCUR转发信号
TCUR软件版本";
CM_ SG_ 1479 FMCU_BoostInputVoltAct "Boost输入电压
T1N JS FL2 坤泰FMCU无升压模块，不需要发";
CM_ SG_ 1479 FMCU_BoostModeAct "Boost工作模式
T1N JS FL2 坤泰FMCU无升压模块，不需要发";
CM_ SG_ 1479 FMCU_BoostPhaseCurrentA "Boost A相电流
T1N JS FL2 坤泰FMCU无升压模块，不需要发";
CM_ SG_ 1479 FMCU_BoostPhaseCurrentB "Boost B相电流
T1N JS FL2 坤泰FMCU无升压模块，不需要发";
CM_ SG_ 1479 FMCU_BoostInductTempA "Boost A相电感温度
T1N JS FL2 坤泰FMCU无升压模块，不需要发";
CM_ SG_ 1479 FMCU_BoostInductTempB "Boost B相电感温度
T1N JS FL2 坤泰FMCU无升压模块，不需要发";
CM_ SG_ 1479 FMCU_BoostModuleTempA "Boost 功率模块A相温度
T1N JS FL2 坤泰FMCU无升压模块，不需要发";
CM_ SG_ 1479 FMCU_BoostModuleTempB "Boost 功率模块B相温度
T1N JS FL2 坤泰FMCU无升压模块，不需要发";
CM_ SG_ 1479 FMCU_GM_Oil_Valve_Current "电磁开关阀工作电流
T1N JS FL2 坤泰FMCU无升压模块，不需要发";
CM_ SG_ 1479 FMCU_GM_Oil_Valve_Sts "电磁开关阀工作状态
T1N JS FL2 坤泰FMCU无升压模块，不需要发";
CM_ SG_ 1521 EMS_TotalFaultNum "当前故障总数";
CM_ SG_ 1521 EMS_FrameIndex "帧序号";
CM_ SG_ 1521 EMS_SupplierNum "供应商代码";
CM_ SG_ 1521 EMS_FaultNum1 "故障列表1";
CM_ SG_ 1521 EMS_FaultNum2 "故障列表2";
CM_ SG_ 1521 EMS_FaultNum3 "故障列表3";
CM_ SG_ 1521 EMS_FaultNum4 "故障列表4";
CM_ SG_ 1521 EMS_FaultNum5 "故障列表5";
CM_ SG_ 1521 EMS_FaultNum6 "故障列表6";
CM_ SG_ 1521 EMS_FaultNum7 "故障列表7";
CM_ SG_ 1521 EMS_FaultNum8 "故障列表8";
CM_ SG_ 1521 EMS_FaultNum9 "故障列表9";
CM_ SG_ 1521 EMS_FaultNum10 "故障列表10";
CM_ SG_ 1521 EMS_FaultNum11 "故障列表11";
CM_ SG_ 1521 EMS_FaultNum12 "故障列表12";
CM_ SG_ 1521 EMS_FaultNum13 "故障列表13";
CM_ SG_ 1521 EMS_FaultNum14 "故障列表14";
CM_ SG_ 1521 EMS_FaultNum15 "故障列表15";
CM_ SG_ 1521 EMS_FaultNum16 "故障列表16";
CM_ SG_ 1521 EMS_FaultNum17 "故障列表17";
CM_ SG_ 1521 EMS_FaultNum18 "故障列表18";
CM_ SG_ 1521 EMS_FaultNum19 "故障列表19";
CM_ SG_ 1521 EMS_FaultNum20 "故障列表20";
CM_ SG_ 1582 RMR_RMCU "If set to 1 to force the network management of all other nodes on the bus into the re-peat message state.";
CM_ SG_ 1582 RMCU_Wakeup_Poweron "KL15 ON";
CM_ SG_ 1582 RMCU_Wakeup_NM "NM报文";
CM_ SG_ 1582 RMCU_Wakeup_Diag "Wakeup Source3 Reserved";
CM_ SG_ 1582 RMCU_Awake_Poweron "KL15 ON";
CM_ SG_ 1582 RMCU_Awake_NM "Awake Reason2 Reserved";
CM_ SG_ 1582 RMCU_Awake_Diag "接收到本部件相关的诊断报文";
CM_ SG_ 1582 RMCU_Awake_Discharge "放电中且放电未超时";
CM_ SG_ 1582 RMCU_Awake_HVON "整车处于高压状态";
CM_ SG_ 2019 Diag_OBD_RMCU_REQ "8~64Byte自适应";
BA_DEF_ SG_ "ASIL" ENUM "QM","A","B","C","D";
BA_DEF_ SG_ "E2EDataLength" INT 0 65535;
BA_DEF_ SG_ "GenSigInactiveValue" HEX 0 80000000;
BA_DEF_ SG_ "GenSigInvalidValue" HEX 0 281474976710655;
BA_DEF_ SG_ "GenSigStartValue" HEX 0 80000000;
BA_DEF_ SG_ "GenSigSendType" ENUM "Cyclic","OnWrite","OnWriteWithRepetition","OnChange","OnChangeWithRepetition","IfActive","IfActiveWithRepetition","NoSigSendType";
BA_DEF_ BO_ "CANFD_BRS" ENUM "0","1";
BA_DEF_ BO_ "DiagMessage" ENUM "No","Yes";
BA_DEF_ BO_ "DiagRequest" ENUM "No","Yes";
BA_DEF_ BO_ "DiagResponse" ENUM "No","Yes";
BA_DEF_ BO_ "DiagState" ENUM "No","Yes";
BA_DEF_ BO_ "DiagUudtResponse" ENUM "True","False";
BA_DEF_ BO_ "GenMsgCycleTime" INT 0 65535;
BA_DEF_ BO_ "GenMsgCycleTimeFast" INT 0 65535;
BA_DEF_ BO_ "GenMsgDelayTime" INT 0 65535;
BA_DEF_ BO_ "GenMsgILSupport" ENUM "No","Yes";
BA_DEF_ BO_ "GenMsgNrOfRepetition" INT 0 255;
BA_DEF_ BO_ "GenMsgSendType" ENUM "Cyclic","Event","IfActive","CE","CA","NoMsgSendType";
BA_DEF_ BO_ "MsgType" ENUM "IL","NM","DIAG","APPL";
BA_DEF_ BO_ "Msg_ASIL" ENUM "vector_leerstring","QM","A","B","C","D";
BA_DEF_ BO_ "NmAsrMessage" ENUM "No","Yes";
BA_DEF_ BO_ "NmMessage" ENUM "No","Yes";
BA_DEF_ BO_ "SCP_AuthInfoTxLength" INT 9 512;
BA_DEF_ BO_ "SCP_FreshnessValueLength" INT 0 512;
BA_DEF_ BO_ "SCP_FreshnessValueTxLength" INT 0 512;
BA_DEF_ BO_ "VFrameFormat" ENUM "StandardCAN","ExtendedCAN","reserved","J1939PG","reserved","reserved","reserved","reserved","reserved","reserved","reserved","reserved","reserved","reserved","StandardCAN_FD","ExtendedCAN_FD";
BA_DEF_DEF_ "ASIL" "QM";
BA_DEF_DEF_ "E2EDataLength" 64;
BA_DEF_DEF_ "GenSigInactiveValue" 0;
BA_DEF_DEF_ "GenSigInvalidValue" 0;
BA_DEF_DEF_ "GenSigStartValue" 0;
BA_DEF_DEF_ "GenSigSendType" "NoSigSendType";
BA_DEF_DEF_ "CANFD_BRS" "1";
BA_DEF_DEF_ "DiagMessage" "No";
BA_DEF_DEF_ "DiagRequest" "No";
BA_DEF_DEF_ "DiagResponse" "No";
BA_DEF_DEF_ "DiagState" "No";
BA_DEF_DEF_ "DiagUudtResponse" "True";
BA_DEF_DEF_ "GenMsgCycleTime" 0;
BA_DEF_DEF_ "GenMsgCycleTimeFast" 0;
BA_DEF_DEF_ "GenMsgDelayTime" 0;
BA_DEF_DEF_ "GenMsgILSupport" "Yes";
BA_DEF_DEF_ "GenMsgNrOfRepetition" 0;
BA_DEF_DEF_ "GenMsgSendType" "Cyclic";
BA_DEF_DEF_ "MsgType" "IL";
BA_DEF_DEF_ "Msg_ASIL" "vector_leerstring";
BA_DEF_DEF_ "NmAsrMessage" "No";
BA_DEF_DEF_ "NmMessage" "No";
BA_DEF_DEF_ "SCP_AuthInfoTxLength" 28;
BA_DEF_DEF_ "SCP_FreshnessValueLength" 48;
BA_DEF_DEF_ "SCP_FreshnessValueTxLength" 4;
BA_DEF_DEF_ "VFrameFormat" "J1939PG";
BA_ "GenMsgCycleTime" BO_ 754 20;
BA_ "VFrameFormat" BO_ 754 14;
BA_ "GenMsgCycleTime" BO_ 777 500;
BA_ "VFrameFormat" BO_ 777 14;
BA_ "GenMsgCycleTime" BO_ 782 50;
BA_ "VFrameFormat" BO_ 782 14;
BA_ "GenMsgCycleTime" BO_ 786 500;
BA_ "VFrameFormat" BO_ 786 14;
BA_ "GenMsgCycleTime" BO_ 808 50;
BA_ "VFrameFormat" BO_ 808 14;
BA_ "GenMsgCycleTime" BO_ 859 50;
BA_ "VFrameFormat" BO_ 859 14;
BA_ "GenMsgCycleTime" BO_ 884 50;
BA_ "VFrameFormat" BO_ 884 14;
BA_ "GenMsgSendType" BO_ 929 1;
BA_ "VFrameFormat" BO_ 929 14;
BA_ "GenMsgSendType" BO_ 938 1;
BA_ "VFrameFormat" BO_ 938 14;
BA_ "GenMsgSendType" BO_ 947 1;
BA_ "VFrameFormat" BO_ 947 14;
BA_ "GenMsgSendType" BO_ 952 1;
BA_ "VFrameFormat" BO_ 952 14;
BA_ "GenMsgCycleTime" BO_ 1022 100;
BA_ "VFrameFormat" BO_ 1022 14;
BA_ "GenMsgCycleTime" BO_ 1034 100;
BA_ "VFrameFormat" BO_ 1034 14;
BA_ "GenMsgCycleTime" BO_ 1044 100;
BA_ "VFrameFormat" BO_ 1044 14;
BA_ "GenMsgCycleTime" BO_ 1057 100;
BA_ "VFrameFormat" BO_ 1057 14;
BA_ "GenMsgCycleTime" BO_ 1064 50;
BA_ "GenMsgDelayTime" BO_ 1064 5;
BA_ "VFrameFormat" BO_ 1064 14;
BA_ "GenMsgNrOfRepetition" BO_ 1075 3;
BA_ "GenMsgDelayTime" BO_ 1075 5;
BA_ "GenMsgCycleTimeFast" BO_ 1075 100;
BA_ "GenMsgSendType" BO_ 1075 1;
BA_ "VFrameFormat" BO_ 1075 14;
BA_ "GenMsgCycleTime" BO_ 1097 100;
BA_ "VFrameFormat" BO_ 1097 14;
BA_ "GenMsgCycleTime" BO_ 1099 100;
BA_ "VFrameFormat" BO_ 1099 14;
BA_ "GenMsgCycleTime" BO_ 1103 100;
BA_ "VFrameFormat" BO_ 1103 14;
BA_ "GenMsgCycleTime" BO_ 1130 100;
BA_ "VFrameFormat" BO_ 1130 14;
BA_ "GenMsgNrOfRepetition" BO_ 1136 96;
BA_ "GenMsgDelayTime" BO_ 1136 5;
BA_ "GenMsgCycleTimeFast" BO_ 1136 100;
BA_ "GenMsgSendType" BO_ 1136 1;
BA_ "VFrameFormat" BO_ 1136 14;
BA_ "GenMsgCycleTime" BO_ 1162 100;
BA_ "VFrameFormat" BO_ 1162 14;
BA_ "GenMsgCycleTime" BO_ 1163 100;
BA_ "VFrameFormat" BO_ 1163 14;
BA_ "GenMsgCycleTime" BO_ 1166 100;
BA_ "VFrameFormat" BO_ 1166 14;
BA_ "GenMsgCycleTime" BO_ 1177 100;
BA_ "VFrameFormat" BO_ 1177 14;
BA_ "GenMsgCycleTime" BO_ 1202 100;
BA_ "VFrameFormat" BO_ 1202 14;
BA_ "GenMsgCycleTime" BO_ 1204 100;
BA_ "VFrameFormat" BO_ 1204 14;
BA_ "GenMsgCycleTime" BO_ 1207 100;
BA_ "VFrameFormat" BO_ 1207 14;
BA_ "GenMsgCycleTime" BO_ 1213 100;
BA_ "VFrameFormat" BO_ 1213 14;
BA_ "GenMsgCycleTime" BO_ 1241 100;
BA_ "VFrameFormat" BO_ 1241 14;
BA_ "GenMsgCycleTime" BO_ 1252 100;
BA_ "VFrameFormat" BO_ 1252 14;
BA_ "GenMsgCycleTime" BO_ 1296 500;
BA_ "VFrameFormat" BO_ 1296 14;
BA_ "GenMsgCycleTime" BO_ 1307 500;
BA_ "VFrameFormat" BO_ 1307 14;
BA_ "GenMsgCycleTime" BO_ 1314 100;
BA_ "VFrameFormat" BO_ 1314 14;
BA_ "GenMsgCycleTime" BO_ 1315 500;
BA_ "VFrameFormat" BO_ 1315 14;
BA_ "GenMsgCycleTime" BO_ 1338 500;
BA_ "VFrameFormat" BO_ 1338 14;
BA_ "GenMsgCycleTime" BO_ 1403 500;
BA_ "VFrameFormat" BO_ 1403 14;
BA_ "GenMsgCycleTime" BO_ 1407 1000;
BA_ "VFrameFormat" BO_ 1407 14;
BA_ "GenMsgCycleTime" BO_ 1479 500;
BA_ "VFrameFormat" BO_ 1479 14;
BA_ "GenMsgCycleTime" BO_ 1521 500;
BA_ "VFrameFormat" BO_ 1521 14;
BA_ "GenMsgCycleTime" BO_ 1582 1000;
BA_ "NmMessage" BO_ 1582 1;
BA_ "DiagUudtResponse" BO_ 1582 1;
BA_ "MsgType" BO_ 1582 1;
BA_ "NmAsrMessage" BO_ 1582 1;
BA_ "GenMsgILSupport" BO_ 1582 0;
BA_ "VFrameFormat" BO_ 1582 0;
BA_ "DiagRequest" BO_ 1818 1;
BA_ "MsgType" BO_ 1818 2;
BA_ "DiagMessage" BO_ 1818 1;
BA_ "DiagUudtResponse" BO_ 1818 1;
BA_ "GenMsgILSupport" BO_ 1818 0;
BA_ "GenMsgSendType" BO_ 1818 1;
BA_ "VFrameFormat" BO_ 1818 14;
BA_ "DiagMessage" BO_ 1843 1;
BA_ "DiagUudtResponse" BO_ 1843 1;
BA_ "DiagRequest" BO_ 1843 1;
BA_ "MsgType" BO_ 1843 2;
BA_ "GenMsgILSupport" BO_ 1843 0;
BA_ "GenMsgSendType" BO_ 1843 1;
BA_ "VFrameFormat" BO_ 1843 14;
BA_ "DiagResponse" BO_ 1946 1;
BA_ "MsgType" BO_ 1946 2;
BA_ "DiagMessage" BO_ 1946 1;
BA_ "DiagUudtResponse" BO_ 1946 1;
BA_ "GenMsgILSupport" BO_ 1946 0;
BA_ "GenMsgSendType" BO_ 1946 1;
BA_ "VFrameFormat" BO_ 1946 14;
BA_ "DiagResponse" BO_ 1971 1;
BA_ "MsgType" BO_ 1971 2;
BA_ "DiagMessage" BO_ 1971 1;
BA_ "DiagUudtResponse" BO_ 1971 1;
BA_ "GenMsgILSupport" BO_ 1971 0;
BA_ "GenMsgSendType" BO_ 1971 1;
BA_ "VFrameFormat" BO_ 1971 14;
BA_ "DiagMessage" BO_ 2015 1;
BA_ "DiagState" BO_ 2015 1;
BA_ "DiagUudtResponse" BO_ 2015 1;
BA_ "MsgType" BO_ 2015 2;
BA_ "GenMsgILSupport" BO_ 2015 0;
BA_ "GenMsgSendType" BO_ 2015 1;
BA_ "VFrameFormat" BO_ 2015 14;
BA_ "DiagMessage" BO_ 2019 1;
BA_ "DiagUudtResponse" BO_ 2019 1;
BA_ "DiagRequest" BO_ 2019 1;
BA_ "MsgType" BO_ 2019 2;
BA_ "GenMsgILSupport" BO_ 2019 0;
BA_ "GenMsgSendType" BO_ 2019 1;
BA_ "VFrameFormat" BO_ 2019 14;
BA_ "DiagResponse" BO_ 2027 1;
BA_ "MsgType" BO_ 2027 2;
BA_ "DiagMessage" BO_ 2027 1;
BA_ "DiagUudtResponse" BO_ 2027 1;
BA_ "GenMsgILSupport" BO_ 2027 0;
BA_ "GenMsgSendType" BO_ 2027 1;
BA_ "VFrameFormat" BO_ 2027 14;
BA_ "GenSigSendType" SG_ 754 EMS_26_CRC1 0;
BA_ "GenSigSendType" SG_ 754 EMS_26_RollgCntr1 0;
BA_ "GenSigSendType" SG_ 754 EMS_26_Resd1 0;
BA_ "GenSigSendType" SG_ 754 BaroPressureAbsolute 0;
BA_ "GenSigInvalidValue" SG_ 754 EngineDragTorq 255;
BA_ "GenSigStartValue" SG_ 754 EngineDragTorq 250;
BA_ "GenSigSendType" SG_ 754 EngineDragTorq 0;
BA_ "GenSigInvalidValue" SG_ 754 EngineTorqMax 511;
BA_ "GenSigStartValue" SG_ 754 EngineTorqMax 50;
BA_ "GenSigSendType" SG_ 754 EngineTorqMax 0;
BA_ "GenSigInvalidValue" SG_ 754 EngineTorqMin 511;
BA_ "GenSigStartValue" SG_ 754 EngineTorqMin 50;
BA_ "GenSigSendType" SG_ 754 EngineTorqMin 0;
BA_ "GenSigInvalidValue" SG_ 754 BaroPressureAbsoluteValid 1;
BA_ "GenSigSendType" SG_ 754 BaroPressureAbsoluteValid 0;
BA_ "GenSigSendType" SG_ 777 ISGF_ErrLvl 0;
BA_ "GenSigSendType" SG_ 782 RMCU_6_CRC 0;
BA_ "GenSigSendType" SG_ 782 RMCU_6_RollgCntr 0;
BA_ "GenSigSendType" SG_ 782 RMCU_6_Resd 0;
BA_ "GenSigSendType" SG_ 782 RMCU_6_Ratio 0;
BA_ "GenSigSendType" SG_ 782 TCUR_SubFaultFlag 0;
BA_ "GenSigSendType" SG_ 782 TCUR_ActrFailrSt 0;
BA_ "GenSigSendType" SG_ 786 ISGF_GateDrvSt 0;
BA_ "GenSigSendType" SG_ 808 RMCU_2_CRC1 0;
BA_ "GenSigSendType" SG_ 808 RMCU_2_RollgCntr1 0;
BA_ "GenSigSendType" SG_ 808 RMCU_2_Resd1 0;
BA_ "GenSigInvalidValue" SG_ 808 RMCU_2_InverterTemperature 255;
BA_ "GenSigStartValue" SG_ 808 RMCU_2_InverterTemperature 250;
BA_ "GenSigSendType" SG_ 808 RMCU_2_InverterTemperature 0;
BA_ "GenSigInvalidValue" SG_ 808 RMCU_2_StatorTemperature 511;
BA_ "GenSigStartValue" SG_ 808 RMCU_2_StatorTemperature 40;
BA_ "GenSigSendType" SG_ 808 RMCU_2_StatorTemperature 0;
BA_ "GenSigSendType" SG_ 808 RMCU_HeatRunFlg 0;
BA_ "GenSigSendType" SG_ 808 RMCU_Ratio 0;
BA_ "GenSigSendType" SG_ 808 RMCU_LowPwrSts 0;
BA_ "GenSigInvalidValue" SG_ 808 RMCU_InvSampTemperature 255;
BA_ "GenSigStartValue" SG_ 808 RMCU_InvSampTemperature 250;
BA_ "GenSigSendType" SG_ 808 RMCU_InvSampTemperature 0;
BA_ "GenSigSendType" SG_ 808 RMCU_2_CRC2 0;
BA_ "GenSigSendType" SG_ 808 RMCU_2_RollgCntr2 0;
BA_ "GenSigSendType" SG_ 808 RMCU_2_Resd2 0;
BA_ "GenSigInvalidValue" SG_ 808 RMCU_2_MaxHeatSpeed 65535;
BA_ "GenSigStartValue" SG_ 808 RMCU_2_MaxHeatSpeed 65533;
BA_ "GenSigSendType" SG_ 808 RMCU_2_MaxHeatSpeed 0;
BA_ "GenSigInvalidValue" SG_ 808 RMCU_2_MaxHeatTorque 4095;
BA_ "GenSigSendType" SG_ 808 RMCU_2_MaxHeatTorque 0;
BA_ "GenSigStartValue" SG_ 808 RMCU_immoResult 3;
BA_ "GenSigSendType" SG_ 808 RMCU_immoResult 0;
BA_ "GenSigStartValue" SG_ 859 TorqueReductReqRAValidData 1;
BA_ "ASIL" SG_ 859 TorqueReductReqRAValidData 3;
BA_ "GenSigSendType" SG_ 859 TorqueReductReqRAValidData 0;
BA_ "GenSigInvalidValue" SG_ 884 WPump3Duty 255;
BA_ "GenSigSendType" SG_ 884 WPump3Duty 0;
BA_ "GenSigSendType" SG_ 884 CoolingFanDuty 0;
BA_ "GenSigSendType" SG_ 929 IMMO_Auth_MCU 1;
BA_ "GenSigSendType" SG_ 938 IMMO_Teach_MCU 1;
BA_ "GenSigSendType" SG_ 947 MCU_Chall_IMMO 1;
BA_ "GenSigSendType" SG_ 952 MCU_Teach_IMMO 1;
BA_ "GenSigSendType" SG_ 1022 FLZCU_CarMode 0;
BA_ "GenSigSendType" SG_ 1034 HCU_1_G_CRC1 0;
BA_ "GenSigSendType" SG_ 1034 HCU_1_G_RollgCntr1 0;
BA_ "GenSigSendType" SG_ 1034 HCU_1_G_Resd1 0;
BA_ "GenSigInvalidValue" SG_ 1034 HCU_EmPwr 255;
BA_ "GenSigStartValue" SG_ 1034 HCU_EmPwr 128;
BA_ "GenSigSendType" SG_ 1034 HCU_EmPwr 0;
BA_ "ASIL" SG_ 1034 HCU_VehicleState 1;
BA_ "GenSigSendType" SG_ 1034 HCU_VehicleState 0;
BA_ "GenSigSendType" SG_ 1034 HCU_RunMode 0;
BA_ "GenSigSendType" SG_ 1034 HCU_TMNumber 0;
BA_ "GenSigSendType" SG_ 1034 HCU_PwrTrnModeDisp 0;
BA_ "GenSigSendType" SG_ 1034 HCU_IntelligentPowerSupply 0;
BA_ "ASIL" SG_ 1034 HCU_PowerModeFed 1;
BA_ "GenSigSendType" SG_ 1034 HCU_PowerModeFed 0;
BA_ "ASIL" SG_ 1034 HCU_LimpHomeMode 1;
BA_ "GenSigSendType" SG_ 1034 HCU_LimpHomeMode 0;
BA_ "GenSigSendType" SG_ 1034 HCU_ISGRegenerateSts 0;
BA_ "GenSigSendType" SG_ 1034 HCU_EmOverSpdWarn 0;
BA_ "GenSigSendType" SG_ 1034 HCU_PowertrainFault 0;
BA_ "ASIL" SG_ 1034 HCU_PrePTReady 1;
BA_ "GenSigSendType" SG_ 1034 HCU_PrePTReady 0;
BA_ "GenSigSendType" SG_ 1034 HCU_PowerModeChangeFail 0;
BA_ "GenSigSendType" SG_ 1034 BMSH_MILReq 0;
BA_ "ASIL" SG_ 1034 TMF_EngMilLampReq 1;
BA_ "GenSigSendType" SG_ 1034 TMF_EngMilLampReq 0;
BA_ "ASIL" SG_ 1034 TMR_EngMilLampReq 1;
BA_ "GenSigSendType" SG_ 1034 TMR_EngMilLampReq 0;
BA_ "ASIL" SG_ 1034 HCU_MILReq 1;
BA_ "GenSigSendType" SG_ 1034 HCU_MILReq 0;
BA_ "ASIL" SG_ 1034 HCU_HVReady 1;
BA_ "GenSigSendType" SG_ 1034 HCU_HVReady 0;
BA_ "ASIL" SG_ 1034 HCU_PTReady 1;
BA_ "GenSigSendType" SG_ 1034 HCU_PTReady 0;
BA_ "GenSigSendType" SG_ 1034 HCU_ChargingSts 0;
BA_ "GenSigSendType" SG_ 1034 HCU_PtSts 0;
BA_ "GenSigSendType" SG_ 1034 HCU_InHbStrtRes 0;
BA_ "GenSigInvalidValue" SG_ 1044 HCU_RangeAval 2047;
BA_ "GenSigSendType" SG_ 1044 HCU_RangeAval 0;
BA_ "GenSigSendType" SG_ 1044 HCU_EnergyFlow 0;
BA_ "GenSigSendType" SG_ 1044 HCU_ReplaceWarmupCycle 0;
BA_ "GenSigSendType" SG_ 1044 HCU_CLMOBDClearReq 0;
BA_ "GenSigSendType" SG_ 1044 HCU_2_G_ChgIncOper 0;
BA_ "GenSigSendType" SG_ 1044 HCU_2_G_ChgDepOper 0;
BA_ "GenSigSendType" SG_ 1044 HCU_SocManageFed_414h 0;
BA_ "GenSigInvalidValue" SG_ 1044 HCU_SetSOCFed 255;
BA_ "GenSigSendType" SG_ 1044 HCU_SetSOCFed 0;
BA_ "GenSigSendType" SG_ 1044 VCU_BrakePedalStsValidData 0;
BA_ "ASIL" SG_ 1044 VCU_BrakePedalSts 2;
BA_ "GenSigSendType" SG_ 1044 VCU_BrakePedalSts 0;
BA_ "GenSigSendType" SG_ 1044 HCU_EnergyFlowREEV 0;
BA_ "GenSigSendType" SG_ 1044 HCU_EmissionDetection 0;
BA_ "GenSigSendType" SG_ 1044 HCU_2_G_IntrptGpfRgtvSt 0;
BA_ "GenSigSendType" SG_ 1044 HCU_2_G_LowBatteryInfo 0;
BA_ "GenSigSendType" SG_ 1044 HCU_2_G_LowBatteryLowFuelInfo 0;
BA_ "GenSigSendType" SG_ 1044 HCU_2_G_HighTempLimit 0;
BA_ "GenSigSendType" SG_ 1057 VCU_shfChk 0;
BA_ "GenSigSendType" SG_ 1057 VCU_PowerLimitSOCLow 0;
BA_ "GenSigSendType" SG_ 1057 VCU_MCU_MilLampReq 0;
BA_ "GenSigSendType" SG_ 1057 VCU_OPDinfo 0;
BA_ "GenSigInvalidValue" SG_ 1057 VCU_ePTDrvPowerPcent 255;
BA_ "GenSigSendType" SG_ 1057 VCU_ePTDrvPowerPcent 0;
BA_ "GenSigSendType" SG_ 1057 VCU_TowingMode 0;
BA_ "GenSigSendType" SG_ 1057 VCU_EgyRegenLevelHighAllowed 0;
BA_ "GenSigSendType" SG_ 1057 VCU_SportDriveModeAvailable 0;
BA_ "GenSigSendType" SG_ 1057 VCU_RainSnowDriveModeAvailable 0;
BA_ "GenSigSendType" SG_ 1057 VCU_OffRoadDriveModeAvailable 0;
BA_ "GenSigSendType" SG_ 1057 VCU_CampAvailable 0;
BA_ "GenSigInvalidValue" SG_ 1057 VCU_DisChgSOCHighLim 255;
BA_ "GenSigStartValue" SG_ 1057 VCU_DisChgSOCHighLim 255;
BA_ "GenSigSendType" SG_ 1057 VCU_DisChgSOCHighLim 0;
BA_ "GenSigInvalidValue" SG_ 1057 VCU_DisChgSOCLowLim 255;
BA_ "GenSigStartValue" SG_ 1057 VCU_DisChgSOCLowLim 255;
BA_ "GenSigSendType" SG_ 1057 VCU_DisChgSOCLowLim 0;
BA_ "GenSigInvalidValue" SG_ 1057 VCU_ChgSocSetFed 255;
BA_ "GenSigStartValue" SG_ 1057 VCU_ChgSocSetFed 255;
BA_ "GenSigSendType" SG_ 1057 VCU_ChgSocSetFed 0;
BA_ "GenSigInvalidValue" SG_ 1057 VCU_EngyConsuPer10Km 4095;
BA_ "GenSigSendType" SG_ 1057 VCU_EngyConsuPer10Km 0;
BA_ "GenSigInvalidValue" SG_ 1057 VCU_EngyConsuPer25Km 4095;
BA_ "GenSigSendType" SG_ 1057 VCU_EngyConsuPer25Km 0;
BA_ "GenSigInvalidValue" SG_ 1057 VCU_EngyConsuPer50Km 4095;
BA_ "GenSigSendType" SG_ 1057 VCU_EngyConsuPer50Km 0;
BA_ "GenSigInvalidValue" SG_ 1057 VCU_EngyConsuPer100m 4095;
BA_ "GenSigSendType" SG_ 1057 VCU_EngyConsuPer100m 0;
BA_ "GenSigInvalidValue" SG_ 1057 VCU_DisChrgPwr 255;
BA_ "GenSigSendType" SG_ 1057 VCU_DisChrgPwr 0;
BA_ "GenSigSendType" SG_ 1057 VCU_BookChrgSetFailRes 0;
BA_ "GenSigSendType" SG_ 1057 VCU_BookChrgFailRes 0;
BA_ "GenSigSendType" SG_ 1057 VCU_HVILFault 0;
BA_ "GenSigInvalidValue" SG_ 1057 VCUExtendRang 1023;
BA_ "GenSigSendType" SG_ 1057 VCUExtendRang 0;
BA_ "GenSigSendType" SG_ 1057 VCU_KeepWarmFailReason 0;
BA_ "GenSigSendType" SG_ 1057 VCU_ExtremeEnergySavingModeAv 0;
BA_ "GenSigSendType" SG_ 1057 VCU_TowModeAvailable 0;
BA_ "GenSigSendType" SG_ 1057 VCU_StopModeSWStsResp 0;
BA_ "GenSigSendType" SG_ 1057 VCU_StopModeSWAllowed 0;
BA_ "GenSigSendType" SG_ 1057 VCU_ChgDisChgLedCtrl 0;
BA_ "GenSigInvalidValue" SG_ 1057 VCU_CPMaxVolt 255;
BA_ "GenSigSendType" SG_ 1057 VCU_CPMaxVolt 0;
BA_ "GenSigSendType" SG_ 1057 VCUExtremeEnergySavingModeReq 0;
BA_ "GenSigSendType" SG_ 1057 VCU_EpedalModeSts 0;
BA_ "GenSigSendType" SG_ 1057 VCU_BookChrgStsFb 0;
BA_ "GenSigSendType" SG_ 1057 VCU_HVNM 0;
BA_ "GenSigStartValue" SG_ 1057 VCU_DriveMode 6;
BA_ "ASIL" SG_ 1057 VCU_DriveMode 2;
BA_ "GenSigSendType" SG_ 1057 VCU_DriveMode 0;
BA_ "GenSigSendType" SG_ 1057 HCU_EnterForceEVFailRes 0;
BA_ "GenSigSendType" SG_ 1057 HCU_EngineSelfMaintain 0;
BA_ "GenSigSendType" SG_ 1057 HCU_EnterForceChrgFailRes 0;
BA_ "GenSigSendType" SG_ 1057 HCU_InStartRes 0;
BA_ "GenSigSendType" SG_ 1057 HCU_EnergyRegSetFed 0;
BA_ "GenSigSendType" SG_ 1064 WorkingSts 0;
BA_ "GenSigSendType" SG_ 1064 ADCC_AdsLowPowSts_333h 0;
BA_ "GenSigSendType" SG_ 1075 VCC_2_ConfigurationMessageTrg 2;
BA_ "GenSigSendType" SG_ 1097 TMS_RMCU_MotSelfHeatLvlReq 0;
BA_ "GenSigSendType" SG_ 1097 TMS_RMCU_MotSelfHeatEnReq 0;
BA_ "GenSigSendType" SG_ 1099 ISGF_LockedRotorFlag 0;
BA_ "GenSigInvalidValue" SG_ 1099 ISGF_StatTemp 511;
BA_ "GenSigStartValue" SG_ 1099 ISGF_StatTemp 40;
BA_ "GenSigSendType" SG_ 1099 ISGF_StatTemp 0;
BA_ "GenSigInvalidValue" SG_ 1099 ISGF_VoltageT30 63;
BA_ "GenSigSendType" SG_ 1099 ISGF_VoltageT30 0;
BA_ "GenSigSendType" SG_ 1099 ISGF_SysTempOvrInd 0;
BA_ "GenSigSendType" SG_ 1099 ISGF_MotOvrSpdWarn 0;
BA_ "GenSigSendType" SG_ 1099 ISGF_CalOffsetAngleReq 0;
BA_ "GenSigSendType" SG_ 1099 ISGF_HVILFault 0;
BA_ "GenSigSendType" SG_ 1099 ISGF_EngMilLampReq 0;
BA_ "GenSigSendType" SG_ 1099 ISGF_InvTempOvrErr 0;
BA_ "GenSigSendType" SG_ 1103 RMCU_WPhasecurrent 0;
BA_ "GenSigSendType" SG_ 1103 RMCU_VPhasecurrent 0;
BA_ "GenSigSendType" SG_ 1103 RMCU_UPhasecurrent 0;
BA_ "GenSigSendType" SG_ 1103 RMCU_4_CRC 0;
BA_ "GenSigSendType" SG_ 1103 RMCU_4_RollgCntr 0;
BA_ "GenSigSendType" SG_ 1103 RMCU_4_Resd 0;
BA_ "GenSigSendType" SG_ 1103 RMCU_TempW 0;
BA_ "GenSigSendType" SG_ 1103 RMCU_TempV 0;
BA_ "GenSigSendType" SG_ 1103 RMCU_TempU 0;
BA_ "GenSigSendType" SG_ 1103 RMCU_CoolantTemp 0;
BA_ "GenSigSendType" SG_ 1103 RMCU_RotorTemp 0;
BA_ "GenSigSendType" SG_ 1103 RMCU_Delta_TJ_Coolant 0;
BA_ "GenSigSendType" SG_ 1103 RMCU_TMS_MotSelfHeatLvlFb 0;
BA_ "GenSigSendType" SG_ 1103 RMCU_TMS_MotSelfHeatEnSts 0;
BA_ "GenSigSendType" SG_ 1103 RMCU_IGBTmode 0;
BA_ "GenSigSendType" SG_ 1130 TCU_23_CRC1 0;
BA_ "GenSigSendType" SG_ 1130 TCU_23_RollgCntr1 0;
BA_ "GenSigSendType" SG_ 1130 TCU_23_Resd1 0;
BA_ "GenSigSendType" SG_ 1130 TCU_23_ErrLever 0;
BA_ "GenSigSendType" SG_ 1130 TCU_23_GBFaultstatus 0;
BA_ "GenSigSendType" SG_ 1130 TCU_23_STAT_LeverModeDisp 0;
BA_ "GenSigSendType" SG_ 1130 TCU_23_GBWarmUpReq 0;
BA_ "GenSigSendType" SG_ 1130 TCU_23_TeachInState 0;
BA_ "GenSigSendType" SG_ 1130 TCU_23_CluSelfLrng 0;
BA_ "GenSigSendType" SG_ 1136 VCC_3_CRC 2;
BA_ "GenSigSendType" SG_ 1136 VCC_3_RollgCntr 2;
BA_ "GenSigSendType" SG_ 1136 VCC_3_Resd1 2;
BA_ "GenSigStartValue" SG_ 1136 VCC_3_SN 1;
BA_ "GenSigSendType" SG_ 1136 VCC_3_SN 2;
BA_ "GenSigInvalidValue" SG_ 1162 VehicleSpeedVSOSig 8191;
BA_ "ASIL" SG_ 1162 VehicleSpeedVSOSig 2;
BA_ "GenSigSendType" SG_ 1162 VehicleSpeedVSOSig 0;
BA_ "GenSigStartValue" SG_ 1162 VehicleSpeedVSOSigValidData 1;
BA_ "ASIL" SG_ 1162 VehicleSpeedVSOSigValidData 2;
BA_ "GenSigSendType" SG_ 1162 VehicleSpeedVSOSigValidData 0;
BA_ "ASIL" SG_ 1163 FMCU_DHT_TempStatus 3;
BA_ "GenSigSendType" SG_ 1163 FMCU_DHT_TempStatus 0;
BA_ "ASIL" SG_ 1163 FMCU_DHT_OvTempEngMilLampReq 3;
BA_ "GenSigSendType" SG_ 1163 FMCU_DHT_OvTempEngMilLampReq 0;
BA_ "ASIL" SG_ 1163 FMCU_DHT_OilTempFlag 3;
BA_ "GenSigSendType" SG_ 1163 FMCU_DHT_OilTempFlag 0;
BA_ "ASIL" SG_ 1163 FMCU_DHT_Oil_Temp 3;
BA_ "GenSigSendType" SG_ 1163 FMCU_DHT_Oil_Temp 0;
BA_ "GenSigSendType" SG_ 1166 RMCU_FailCode1 0;
BA_ "GenSigSendType" SG_ 1166 RMCU_FailCode2 0;
BA_ "GenSigSendType" SG_ 1166 RMCU_FailCode3 0;
BA_ "GenSigSendType" SG_ 1166 RMCU_FailCode4 0;
BA_ "GenSigSendType" SG_ 1177 FuelTankLidSts 0;
BA_ "GenSigSendType" SG_ 1177 FuelTankLidLockFailureSts 0;
BA_ "GenSigSendType" SG_ 1177 FuelTankLidSensorFailureSts 0;
BA_ "GenSigSendType" SG_ 1177 FuelTankLidSWFailureSts 0;
BA_ "GenSigInvalidValue" SG_ 1202 EngineCoolantTemperture 255;
BA_ "GenSigStartValue" SG_ 1202 EngineCoolantTemperture 91;
BA_ "GenSigSendType" SG_ 1202 EngineCoolantTemperture 0;
BA_ "GenSigInvalidValue" SG_ 1202 FuelRollingCounter 255;
BA_ "GenSigStartValue" SG_ 1202 FuelRollingCounter 255;
BA_ "GenSigSendType" SG_ 1202 FuelRollingCounter 0;
BA_ "GenSigInvalidValue" SG_ 1202 EngineSpeed 2047;
BA_ "GenSigSendType" SG_ 1202 EngineSpeed 0;
BA_ "GenSigStartValue" SG_ 1202 MILSts 2;
BA_ "GenSigSendType" SG_ 1202 MILSts 0;
BA_ "GenSigStartValue" SG_ 1202 IEMSts 1;
BA_ "GenSigSendType" SG_ 1202 IEMSts 0;
BA_ "GenSigSendType" SG_ 1202 GPFWarning 0;
BA_ "GenSigSendType" SG_ 1202 EngineCoolantTempertureFailSts 0;
BA_ "GenSigSendType" SG_ 1202 FuelRollingCounterValidData 0;
BA_ "GenSigSendType" SG_ 1202 EngineSpeedValidData 0;
BA_ "GenSigStartValue" SG_ 1202 EPCSts 1;
BA_ "GenSigSendType" SG_ 1202 EPCSts 0;
BA_ "GenSigSendType" SG_ 1202 EMS_1_G_EngineSts 0;
BA_ "GenSigSendType" SG_ 1202 EMS_EngineSts_Actual 0;
BA_ "GenSigSendType" SG_ 1202 OilPressureWarningLamp 0;
BA_ "GenSigSendType" SG_ 1204 VCU_1_G_CRC 0;
BA_ "GenSigSendType" SG_ 1204 VCU_1_G_RollgCntr 0;
BA_ "GenSigSendType" SG_ 1204 VCU_AcceleratorPosRawIVD 0;
BA_ "GenSigStartValue" SG_ 1204 VCU_1_G_Pwr 500;
BA_ "GenSigSendType" SG_ 1204 VCU_1_G_Pwr 0;
BA_ "ASIL" SG_ 1204 VCU_1_G_AcceleratorPosRaw 2;
BA_ "GenSigSendType" SG_ 1204 VCU_1_G_AcceleratorPosRaw 0;
BA_ "ASIL" SG_ 1204 VCU_1_G_PTReady 2;
BA_ "GenSigSendType" SG_ 1204 VCU_1_G_PTReady 0;
BA_ "GenSigStartValue" SG_ 1204 VCU_1_G_DriveMode 6;
BA_ "ASIL" SG_ 1204 VCU_1_G_DriveMode 2;
BA_ "GenSigSendType" SG_ 1204 VCU_1_G_DriveMode 0;
BA_ "GenSigSendType" SG_ 1204 VCU_1_G_BookChrgSetResponse 0;
BA_ "GenSigSendType" SG_ 1204 VCU_1_G_HvBattKeepWarmSts 0;
BA_ "GenSigSendType" SG_ 1204 VCU_1_G_HvBattKeepWarmActiveReq 0;
BA_ "GenSigInvalidValue" SG_ 1204 VCU_1_G_HundECAver 511;
BA_ "GenSigSendType" SG_ 1204 VCU_1_G_HundECAver 0;
BA_ "GenSigSendType" SG_ 1204 VCU_1_G_BookChrgSetStsFb 0;
BA_ "GenSigSendType" SG_ 1204 VCU_1_G_EgyRegenLevel 0;
BA_ "ASIL" SG_ 1204 VCU_1_G_PRNDGearAct 2;
BA_ "GenSigSendType" SG_ 1204 VCU_1_G_PRNDGearAct 0;
BA_ "GenSigInvalidValue" SG_ 1207 WPump3Duty_FB 255;
BA_ "GenSigSendType" SG_ 1207 WPump3Duty_FB 0;
BA_ "GenSigSendType" SG_ 1207 WPump3FltSt 0;
BA_ "GenSigSendType" SG_ 1207 CoolingFanFlt 0;
BA_ "GenSigSendType" SG_ 1213 PID04_LoadValueCalculated 0;
BA_ "GenSigSendType" SG_ 1213 PID11_AbsoluteThrottlePosition 0;
BA_ "GenSigInvalidValue" SG_ 1213 LoadValueCalculatedValidData 1;
BA_ "GenSigSendType" SG_ 1213 LoadValueCalculatedValidData 0;
BA_ "GenSigInvalidValue" SG_ 1213 AbsoluteThrottlePosValidData 1;
BA_ "GenSigSendType" SG_ 1213 AbsoluteThrottlePosValidData 0;
BA_ "GenSigSendType" SG_ 1213 OBD_DrivingCycle 0;
BA_ "GenSigSendType" SG_ 1213 OBD_WarmupCycle 0;
BA_ "GenSigSendType" SG_ 1213 OBD_PermanentFailureCycle 0;
BA_ "GenSigSendType" SG_ 1213 OBD_IgnCycle 0;
BA_ "GenSigSendType" SG_ 1213 OBD_GeneralDenomiantor 0;
BA_ "GenSigSendType" SG_ 1213 OBD_GeneralDenomiantorFreeze 0;
BA_ "GenSigSendType" SG_ 1213 EMS_28_GpfRgtvSt 0;
BA_ "GenSigInvalidValue" SG_ 1241 EMS_4_G_EngineSpeed_Actual 65535;
BA_ "GenSigSendType" SG_ 1241 EMS_4_G_EngineSpeed_Actual 0;
BA_ "GenSigSendType" SG_ 1241 LegisDiagStdardCnditionMet 0;
BA_ "GenSigSendType" SG_ 1241 EMS_4_G_Pump_SpeedSts 0;
BA_ "GenSigSendType" SG_ 1241 FuelTankLidLockReq 0;
BA_ "GenSigSendType" SG_ 1241 FuelTankLidSystemFailureSts 0;
BA_ "GenSigSendType" SG_ 1241 FuelTankPressureConditionReached 0;
BA_ "GenSigSendType" SG_ 1241 LegisPostDTCClrDriveCycleCmplte 0;
BA_ "GenSigSendType" SG_ 1241 LegisDiagStdardCnditionFltPresnt 0;
BA_ "GenSigInvalidValue" SG_ 1241 OilPressure_4D9h 24;
BA_ "GenSigSendType" SG_ 1241 OilPressure_4D9h 0;
BA_ "GenSigSendType" SG_ 1241 EMS_4_G_KL15Sts 0;
BA_ "GenSigInvalidValue" SG_ 1252 TotalOdometer_km_OBD 16777215;
BA_ "GenSigSendType" SG_ 1252 TotalOdometer_km_OBD 0;
BA_ "GenSigSendType" SG_ 1252 TotalOdometer_km_OBDValidData 0;
BA_ "GenSigSendType" SG_ 1296 CurrentTimeYear 0;
BA_ "GenSigStartValue" SG_ 1296 CurrentTimeMonth 1;
BA_ "GenSigSendType" SG_ 1296 CurrentTimeMonth 0;
BA_ "GenSigStartValue" SG_ 1296 CurrentTimeDay 1;
BA_ "GenSigSendType" SG_ 1296 CurrentTimeDay 0;
BA_ "GenSigSendType" SG_ 1296 CurrentTimeHour 0;
BA_ "GenSigSendType" SG_ 1296 CurrentTimeMinute 0;
BA_ "GenSigSendType" SG_ 1296 CurrentTimeSecond 0;
BA_ "GenSigSendType" SG_ 1307 RMCU_TotalFaultNum_51Bh 0;
BA_ "GenSigSendType" SG_ 1307 RMCU_FrameIndex_51Bh 0;
BA_ "GenSigSendType" SG_ 1307 RMCU_SupplierNum_51Bh 0;
BA_ "GenSigSendType" SG_ 1307 RMCU_FaultNum1_51Bh 0;
BA_ "GenSigSendType" SG_ 1307 RMCU_FaultNum2_51Bh 0;
BA_ "GenSigSendType" SG_ 1307 RMCU_FaultNum3_51Bh 0;
BA_ "GenSigSendType" SG_ 1307 RMCU_FaultNum4_51Bh 0;
BA_ "GenSigSendType" SG_ 1307 RMCU_FaultNum5_51Bh 0;
BA_ "GenSigSendType" SG_ 1307 RMCU_FaultNum6_51Bh 0;
BA_ "GenSigSendType" SG_ 1307 RMCU_FaultNum7_51Bh 0;
BA_ "GenSigSendType" SG_ 1307 RMCU_FaultNum8_51Bh 0;
BA_ "GenSigSendType" SG_ 1307 RMCU_FaultNum9_51Bh 0;
BA_ "GenSigSendType" SG_ 1307 RMCU_FaultNum10_51Bh 0;
BA_ "GenSigSendType" SG_ 1307 RMCU_FaultNum11_51Bh 0;
BA_ "GenSigSendType" SG_ 1307 RMCU_FaultNum12_51Bh 0;
BA_ "GenSigSendType" SG_ 1307 RMCU_FaultNum13_51Bh 0;
BA_ "GenSigSendType" SG_ 1307 RMCU_FaultNum14_51Bh 0;
BA_ "GenSigSendType" SG_ 1307 RMCU_FaultNum15_51Bh 0;
BA_ "GenSigSendType" SG_ 1307 RMCU_FaultNum16_51Bh 0;
BA_ "GenSigSendType" SG_ 1307 RMCU_FaultNum17_51Bh 0;
BA_ "GenSigSendType" SG_ 1307 RMCU_FaultNum18_51Bh 0;
BA_ "GenSigSendType" SG_ 1307 RMCU_FaultNum19_51Bh 0;
BA_ "GenSigSendType" SG_ 1307 RMCU_FaultNum20_51Bh 0;
BA_ "GenSigSendType" SG_ 1314 HCU_CRC1_522h 0;
BA_ "GenSigSendType" SG_ 1314 HCU_RollgCntr1_522h 0;
BA_ "GenSigSendType" SG_ 1314 HCU_Resd1_522h 0;
BA_ "GenSigSendType" SG_ 1314 HCU_V2lDisChgBck 0;
BA_ "GenSigSendType" SG_ 1314 HCU_DisChgMemFed 0;
BA_ "GenSigSendType" SG_ 1314 HCU_V2VDisChgBck 0;
BA_ "GenSigSendType" SG_ 1314 HCU_V2l_IntlDisChgBck 0;
BA_ "GenSigSendType" SG_ 1314 HCU_FuelDetnOpDefeated 0;
BA_ "GenSigInvalidValue" SG_ 1314 HCU_FuelDetnModSwtFed 3;
BA_ "GenSigSendType" SG_ 1314 HCU_FuelDetnModSwtFed 0;
BA_ "GenSigInvalidValue" SG_ 1314 HCU_FuelDetnStateFed 3;
BA_ "GenSigSendType" SG_ 1314 HCU_FuelDetnStateFed 0;
BA_ "GenSigInvalidValue" SG_ 1314 HCU_HVDownRepairModeFed 3;
BA_ "GenSigSendType" SG_ 1314 HCU_HVDownRepairModeFed 0;
BA_ "GenSigSendType" SG_ 1314 HCU_SumFuCns 0;
BA_ "GenSigInvalidValue" SG_ 1314 HCU_TrailerMode 3;
BA_ "GenSigSendType" SG_ 1314 HCU_TrailerMode 0;
BA_ "GenSigSendType" SG_ 1314 HCU_TABSwtFed_522h 0;
BA_ "GenSigSendType" SG_ 1314 HCU_MotSelfHeatLvlReq 0;
BA_ "GenSigSendType" SG_ 1314 HCU_MotSelfHeatEnReq 0;
BA_ "GenSigSendType" SG_ 1314 HCU_KeyDriveModememory 0;
BA_ "GenSigSendType" SG_ 1314 HCU_DrivePowerDispSetFed 0;
BA_ "GenSigSendType" SG_ 1314 HCU_TCMStsReq_522h 0;
BA_ "GenSigInvalidValue" SG_ 1314 HCU_EXPERTNormFed 3;
BA_ "GenSigSendType" SG_ 1314 HCU_EXPERTNormFed 0;
BA_ "GenSigSendType" SG_ 1314 HCU_4LModeFed 0;
BA_ "GenSigInvalidValue" SG_ 1314 HCU_EXPERTEcoFed 3;
BA_ "GenSigSendType" SG_ 1314 HCU_EXPERTEcoFed 0;
BA_ "GenSigSendType" SG_ 1314 HCU_SingleRegnRmn 0;
BA_ "GenSigSendType" SG_ 1314 HCU_DRIFTModeSts 0;
BA_ "GenSigSendType" SG_ 1314 HCU_CRC2_522h 0;
BA_ "GenSigSendType" SG_ 1314 HCU_RollgCntr2_522h 0;
BA_ "GenSigSendType" SG_ 1314 HCU_Resd2_522h 0;
BA_ "GenSigInvalidValue" SG_ 1314 HCU_EXPERTAWDFed 3;
BA_ "GenSigSendType" SG_ 1314 HCU_EXPERTAWDFed 0;
BA_ "GenSigInvalidValue" SG_ 1314 HCU_EXPERTRWDFed 3;
BA_ "GenSigSendType" SG_ 1314 HCU_EXPERTRWDFed 0;
BA_ "GenSigInvalidValue" SG_ 1314 HCU_CrossaxisFed 3;
BA_ "GenSigSendType" SG_ 1314 HCU_CrossaxisFed 0;
BA_ "GenSigInvalidValue" SG_ 1314 HCU_EXPERTSportFed 3;
BA_ "GenSigSendType" SG_ 1314 HCU_EXPERTSportFed 0;
BA_ "GenSigSendType" SG_ 1314 HCU_StopChrgnModeFed 0;
BA_ "GenSigInvalidValue" SG_ 1314 HCU_StopChrgnFed 3;
BA_ "GenSigSendType" SG_ 1314 HCU_StopChrgnFed 0;
BA_ "GenSigInvalidValue" SG_ 1314 HCU_CLIMBFed 3;
BA_ "GenSigSendType" SG_ 1314 HCU_CLIMBFed 0;
BA_ "GenSigInvalidValue" SG_ 1314 HCU_EXPERTAutoFed 3;
BA_ "GenSigSendType" SG_ 1314 HCU_EXPERTAutoFed 0;
BA_ "GenSigSendType" SG_ 1314 HCU_HEV_FunctionLimit 0;
BA_ "GenSigSendType" SG_ 1314 HCU_ParkingChargeReminder 0;
BA_ "GenSigSendType" SG_ 1314 HCU_PowerCut 0;
BA_ "GenSigSendType" SG_ 1314 HCU_IMMOReleaseSignal 0;
BA_ "GenSigSendType" SG_ 1314 HCU_LVPowSupSYSAbn_lit 0;
BA_ "GenSigSendType" SG_ 1314 HCU_ChrgnFctMemSt 0;
BA_ "GenSigSendType" SG_ 1314 HCU_PowerModeChangeInhibit 0;
BA_ "GenSigSendType" SG_ 1314 HCU_DisconnectChagWarn 0;
BA_ "GenSigSendType" SG_ 1314 HCU_EngineRunClmReq 0;
BA_ "GenSigSendType" SG_ 1314 HCU_VehicleSpeedMax_Limit 0;
BA_ "GenSigSendType" SG_ 1314 HCU_AccleAbility_Limit 0;
BA_ "GenSigSendType" SG_ 1314 HCU_DriveInhibit_GearP 0;
BA_ "GenSigSendType" SG_ 1314 HCU_SetModeNotChange 0;
BA_ "GenSigSendType" SG_ 1314 HCU_UTURNSnowFed 0;
BA_ "GenSigSendType" SG_ 1314 HCU_PowerLevel 0;
BA_ "GenSigSendType" SG_ 1314 HCU_TowingModeEna 0;
BA_ "GenSigSendType" SG_ 1314 HCU_LeaveVehicleWarning 0;
BA_ "GenSigSendType" SG_ 1314 HCU_DedicatedModeInhibit 0;
BA_ "GenSigSendType" SG_ 1314 HCU_DisChargeStopFault 0;
BA_ "GenSigSendType" SG_ 1314 HCU_RearEDLSts 0;
BA_ "GenSigSendType" SG_ 1314 HCU_FrntEDLSts 0;
BA_ "GenSigSendType" SG_ 1314 HCU_CRC3_522h 0;
BA_ "GenSigSendType" SG_ 1314 HCU_RollgCntr3_522h 0;
BA_ "GenSigSendType" SG_ 1314 HCU_Resd3_522h 0;
BA_ "GenSigSendType" SG_ 1314 HCU_CruiseLimitSpeedValue 0;
BA_ "GenSigSendType" SG_ 1314 HCU_DriveMode_JT 0;
BA_ "GenSigSendType" SG_ 1314 HCU_SocManageFed 0;
BA_ "GenSigSendType" SG_ 1314 HCU_SinglePedalMemFed 0;
BA_ "GenSigSendType" SG_ 1314 HCU_CCOSwtFed 0;
BA_ "GenSigStartValue" SG_ 1314 HCU_Pwr 2000;
BA_ "GenSigSendType" SG_ 1314 HCU_Pwr 0;
BA_ "GenSigSendType" SG_ 1314 HCU_DrvGearShiftFailureIndcn 0;
BA_ "GenSigSendType" SG_ 1314 HCU_UTURNSandFed 0;
BA_ "GenSigSendType" SG_ 1314 HCU_CruiseControlStatus 0;
BA_ "GenSigSendType" SG_ 1314 HCU_EXPERTEESPSet 0;
BA_ "GenSigSendType" SG_ 1314 HCU_EgyRegenLevel 0;
BA_ "GenSigSendType" SG_ 1314 HCU_CRC4_522h 0;
BA_ "GenSigSendType" SG_ 1314 HCU_RollgCntr4_522h 0;
BA_ "GenSigSendType" SG_ 1314 HCU_Resd4_522h 0;
BA_ "GenSigSendType" SG_ 1314 HCU_EngyFlowToDisp 0;
BA_ "GenSigSendType" SG_ 1314 HCU_UTURNGrassFed 0;
BA_ "GenSigSendType" SG_ 1314 HCU_UTURNMudFed 0;
BA_ "GenSigSendType" SG_ 1314 HCU_LTCDispFed 0;
BA_ "GenSigSendType" SG_ 1314 HCU_iTAS_Warn 0;
BA_ "GenSigSendType" SG_ 1314 HCU_iCCO_Warn 0;
BA_ "GenSigSendType" SG_ 1314 HCU_DriveModeChangeFail 0;
BA_ "GenSigSendType" SG_ 1314 HCU_25_Crossaxis_Warn 0;
BA_ "GenSigSendType" SG_ 1314 HCU_25_EDLFed 0;
BA_ "GenSigSendType" SG_ 1314 HCU_DraggingModeRemind 0;
BA_ "GenSigSendType" SG_ 1314 HCU_iTASSceneReq 0;
BA_ "GenSigSendType" SG_ 1314 HCU_25_iTAS_SlopWarn 0;
BA_ "GenSigSendType" SG_ 1314 HCU_ExterTempLowHint 0;
BA_ "GenSigSendType" SG_ 1314 HCU_iTAS_Active 0;
BA_ "GenSigSendType" SG_ 1314 HCU_25_VehSpdOffroadRmn 0;
BA_ "GenSigSendType" SG_ 1314 HCU_DrivingModReq 0;
BA_ "GenSigSendType" SG_ 1314 HCU_25_ADS_FctSts 0;
BA_ "GenSigSendType" SG_ 1314 HCU_25_DRIFTModeSetReq 0;
BA_ "GenSigSendType" SG_ 1314 HCU_25_CrossaxisReq 0;
BA_ "GenSigSendType" SG_ 1314 HCU_25_CCOSwtReq 0;
BA_ "GenSigSendType" SG_ 1314 HCU_CRC5_522h 0;
BA_ "GenSigSendType" SG_ 1314 HCU_RollgCntr5_522h 0;
BA_ "GenSigSendType" SG_ 1314 HCU_Resd5_522h 0;
BA_ "GenSigSendType" SG_ 1314 HCU_25_ErrorCode 0;
BA_ "GenSigSendType" SG_ 1314 HCU_25_ErrorCount 0;
BA_ "GenSigSendType" SG_ 1314 HCU_25_iDRIFT_Warn 0;
BA_ "GenSigSendType" SG_ 1314 HCU_25_SetVehSpdOffroad 0;
BA_ "GenSigSendType" SG_ 1314 HCU_25_LaunchMod_Warn 0;
BA_ "GenSigSendType" SG_ 1314 HCU_25_TAB_Warn 0;
BA_ "GenSigSendType" SG_ 1314 HCU_25_CCO_TextDisp 0;
BA_ "GenSigSendType" SG_ 1314 HCU_25_DCM_Warn 0;
BA_ "GenSigSendType" SG_ 1314 HCU_25_CCMFed 0;
BA_ "GenSigSendType" SG_ 1314 HCU_25_TABReq 0;
BA_ "GenSigInvalidValue" SG_ 1314 HCU_SumElecCns 4095;
BA_ "GenSigSendType" SG_ 1314 HCU_SumElecCns 0;
BA_ "GenSigSendType" SG_ 1314 HCU_CrossBorderSts 0;
BA_ "GenSigSendType" SG_ 1314 HCU_DischgSetSOCFed 0;
BA_ "GenSigSendType" SG_ 1314 HCU_facCleverDrvAct_522h 0;
BA_ "GenSigSendType" SG_ 1314 HCU_stCleverDrvAct_522h 0;
BA_ "GenSigSendType" SG_ 1314 HCU_stCleverRgnAct_522h 0;
BA_ "GenSigSendType" SG_ 1314 HCU_stCleverMainAct_522h 0;
BA_ "GenSigSendType" SG_ 1314 EnergySavingModeSts_522h 0;
BA_ "GenSigSendType" SG_ 1314 HCU_facCleverDrvActRstFed_522h 0;
BA_ "GenSigSendType" SG_ 1314 HCU_SailramainingT_Indc_522h 0;
BA_ "GenSigSendType" SG_ 1314 HCU_ATCM_Operation_REQ_522h 0;
BA_ "GenSigSendType" SG_ 1314 HCU_ModeSwFailureIndc_522h 0;
BA_ "GenSigSendType" SG_ 1314 HCU_Sailmode_522h 0;
BA_ "GenSigSendType" SG_ 1314 HCU_CarSickRelfModeFb 0;
BA_ "GenSigSendType" SG_ 1314 HCU_DeepSnowSts_522h 0;
BA_ "GenSigSendType" SG_ 1314 DriveModeChangeFailReason_522h 0;
BA_ "GenSigSendType" SG_ 1314 HCU_CLIMBDisReason_522h 0;
BA_ "GenSigSendType" SG_ 1314 HCU_CarSickRelfModeDisReason 0;
BA_ "GenSigSendType" SG_ 1314 HCU_DCMSwtFed 0;
BA_ "GenSigSendType" SG_ 1314 HCU_LightSandSts_522h 0;
BA_ "GenSigInvalidValue" SG_ 1315 RMCU_2_G_InverterTemperature 255;
BA_ "GenSigStartValue" SG_ 1315 RMCU_2_G_InverterTemperature 250;
BA_ "GenSigSendType" SG_ 1315 RMCU_2_G_InverterTemperature 0;
BA_ "GenSigInvalidValue" SG_ 1315 RMCU_2_G_StatorTemperature 511;
BA_ "GenSigStartValue" SG_ 1315 RMCU_2_G_StatorTemperature 40;
BA_ "GenSigSendType" SG_ 1315 RMCU_2_G_StatorTemperature 0;
BA_ "GenSigInvalidValue" SG_ 1315 RMCU_2_G_OutputTorque 4095;
BA_ "GenSigStartValue" SG_ 1315 RMCU_2_G_OutputTorque 4004;
BA_ "GenSigSendType" SG_ 1315 RMCU_2_G_OutputTorque 0;
BA_ "GenSigInvalidValue" SG_ 1315 RMCU_2_G_Speed 65535;
BA_ "GenSigSendType" SG_ 1315 RMCU_2_G_Speed 0;
BA_ "GenSigInvalidValue" SG_ 1315 RMCU_2_GVoltageHV 1023;
BA_ "GenSigStartValue" SG_ 1315 RMCU_2_GVoltageHV 1022;
BA_ "GenSigSendType" SG_ 1315 RMCU_2_GVoltageHV 0;
BA_ "GenSigInvalidValue" SG_ 1315 RMCU_2_G_CurrentHV 2047;
BA_ "GenSigSendType" SG_ 1315 RMCU_2_G_CurrentHV 0;
BA_ "GenSigSendType" SG_ 1338 FMCU_MotWorkState 0;
BA_ "GenSigSendType" SG_ 1403 RMCU_1_G_CRC 0;
BA_ "GenSigSendType" SG_ 1403 RMCU_1_G_RollgCntr 0;
BA_ "GenSigSendType" SG_ 1403 RMCU_1_G_Resd 0;
BA_ "GenSigSendType" SG_ 1403 RMCU_ErrLvlDis 0;
BA_ "GenSigSendType" SG_ 1403 RMCU_InvTempAlarm 0;
BA_ "GenSigSendType" SG_ 1403 RMCU_MotTempAlarm 0;
BA_ "GenSigInvalidValue" SG_ 1403 RMCU_MotWorkState 7;
BA_ "GenSigSendType" SG_ 1403 RMCU_MotWorkState 0;
BA_ "GenSigStartValue" SG_ 1403 RMCU_MILSts 2;
BA_ "GenSigSendType" SG_ 1403 RMCU_MILSts 0;
BA_ "GenSigInvalidValue" SG_ 1403 RMCU_Speed_EDR 65535;
BA_ "GenSigSendType" SG_ 1403 RMCU_Speed_EDR 0;
BA_ "GenSigSendType" SG_ 1403 RMCU_1_G_OvercurrentAlarm 0;
BA_ "GenSigSendType" SG_ 1403 RMCU_1_G_OverspeedAlarm 0;
BA_ "GenSigSendType" SG_ 1407 RMCU_Version_CRC1 0;
BA_ "GenSigSendType" SG_ 1407 RMCU_Version_RollgCntr1 0;
BA_ "GenSigSendType" SG_ 1407 RMCU_Version_Resd1 0;
BA_ "GenSigSendType" SG_ 1407 RMCU_SupplierCode 0;
BA_ "GenSigSendType" SG_ 1407 RMCU_HwVersion 0;
BA_ "GenSigSendType" SG_ 1407 RMCU_SwMajorVersion 0;
BA_ "GenSigSendType" SG_ 1407 RMCU_SwMinorVersion 0;
BA_ "GenSigSendType" SG_ 1407 RMCU_SwPatchVersion 0;
BA_ "GenSigSendType" SG_ 1407 TCUR_SwVersion 0;
BA_ "GenSigSendType" SG_ 1479 FMCU_BoostInputVoltAct 0;
BA_ "GenSigSendType" SG_ 1479 FMCU_BoostModeAct 0;
BA_ "GenSigSendType" SG_ 1479 FMCU_BoostPhaseCurrentA 0;
BA_ "GenSigSendType" SG_ 1479 FMCU_BoostPhaseCurrentB 0;
BA_ "GenSigSendType" SG_ 1479 FMCU_BoostInductTempA 0;
BA_ "GenSigSendType" SG_ 1479 FMCU_BoostInductTempB 0;
BA_ "GenSigSendType" SG_ 1479 FMCU_BoostModuleTempA 0;
BA_ "GenSigSendType" SG_ 1479 FMCU_BoostModuleTempB 0;
BA_ "GenSigInvalidValue" SG_ 1479 FMCU_GM_Oil_Valve_Current 1023;
BA_ "GenSigSendType" SG_ 1479 FMCU_GM_Oil_Valve_Current 0;
BA_ "GenSigSendType" SG_ 1479 FMCU_GM_Oil_Valve_Sts 0;
BA_ "GenSigSendType" SG_ 1521 EMS_TotalFaultNum 0;
BA_ "GenSigSendType" SG_ 1521 EMS_FrameIndex 0;
BA_ "GenSigSendType" SG_ 1521 EMS_SupplierNum 0;
BA_ "GenSigSendType" SG_ 1521 EMS_FaultNum1 0;
BA_ "GenSigSendType" SG_ 1521 EMS_FaultNum2 0;
BA_ "GenSigSendType" SG_ 1521 EMS_FaultNum3 0;
BA_ "GenSigSendType" SG_ 1521 EMS_FaultNum4 0;
BA_ "GenSigSendType" SG_ 1521 EMS_FaultNum5 0;
BA_ "GenSigSendType" SG_ 1521 EMS_FaultNum6 0;
BA_ "GenSigSendType" SG_ 1521 EMS_FaultNum7 0;
BA_ "GenSigSendType" SG_ 1521 EMS_FaultNum8 0;
BA_ "GenSigSendType" SG_ 1521 EMS_FaultNum9 0;
BA_ "GenSigSendType" SG_ 1521 EMS_FaultNum10 0;
BA_ "GenSigSendType" SG_ 1521 EMS_FaultNum11 0;
BA_ "GenSigSendType" SG_ 1521 EMS_FaultNum12 0;
BA_ "GenSigSendType" SG_ 1521 EMS_FaultNum13 0;
BA_ "GenSigSendType" SG_ 1521 EMS_FaultNum14 0;
BA_ "GenSigSendType" SG_ 1521 EMS_FaultNum15 0;
BA_ "GenSigSendType" SG_ 1521 EMS_FaultNum16 0;
BA_ "GenSigSendType" SG_ 1521 EMS_FaultNum17 0;
BA_ "GenSigSendType" SG_ 1521 EMS_FaultNum18 0;
BA_ "GenSigSendType" SG_ 1521 EMS_FaultNum19 0;
BA_ "GenSigSendType" SG_ 1521 EMS_FaultNum20 0;
BA_ "GenSigStartValue" SG_ 1582 srcNodeID_RMCU 46;
BA_ "GenSigSendType" SG_ 1582 srcNodeID_RMCU 0;
BA_ "GenSigSendType" SG_ 1582 RMR_RMCU 0;
BA_ "GenSigSendType" SG_ 1582 NMm_RMCU_Reserved1 0;
BA_ "GenSigSendType" SG_ 1582 RMCU_Wakeup_Poweron 0;
BA_ "GenSigSendType" SG_ 1582 RMCU_Wakeup_NM 0;
BA_ "GenSigSendType" SG_ 1582 RMCU_Wakeup_Diag 0;
BA_ "GenSigSendType" SG_ 1582 RMCU_Awake_Poweron 0;
BA_ "GenSigSendType" SG_ 1582 RMCU_Awake_NM 0;
BA_ "GenSigSendType" SG_ 1582 RMCU_Awake_Diag 0;
BA_ "GenSigSendType" SG_ 1582 RMCU_Awake_Discharge 0;
BA_ "GenSigSendType" SG_ 1582 RMCU_Awake_HVON 0;
BA_ "GenSigSendType" SG_ 1818 Diag_RMCU_REQ 1;
BA_ "GenSigSendType" SG_ 1843 Diag_TCUR_REQ 1;
BA_ "GenSigSendType" SG_ 1946 Diag_RMCU_RES 1;
BA_ "GenSigSendType" SG_ 1971 Diag_TCUR_RES 1;
BA_ "GenSigSendType" SG_ 2015 Diag_Functional_REQ 1;
BA_ "GenSigSendType" SG_ 2019 Diag_OBD_RMCU_REQ 1;
BA_ "GenSigSendType" SG_ 2027 Diag_OBD_RMCU_RES 1;
VAL_ 754 EngineDragTorq 255 "Invalid";
VAL_ 754 EngineTorqMax 511 "Invalid";
VAL_ 754 EngineTorqMin 511 "Invalid";
VAL_ 754 BaroPressureAbsoluteValid 0 "Valid" 1 "Invalid";
VAL_ 777 ISGF_ErrLvl 0 "No Error" 1 "Err_level1" 2 "Err_level2" 3 "Err_level3" 4 "Err_level4" 5 "Err_level5" 6 "Err_level6";
VAL_ 786 ISGF_GateDrvSt 0 "FreeWheel" 1 "PWMrun" 2 "Discharge" 3 "ShortCircuit";
VAL_ 808 RMCU_2_InverterTemperature 255 "Invalid";
VAL_ 808 RMCU_2_StatorTemperature 511 "Invalid";
VAL_ 808 RMCU_HeatRunFlg 0 "OFF" 1 "ON";
VAL_ 808 RMCU_LowPwrSts 0 "Not Active" 1 "Active";
VAL_ 808 RMCU_InvSampTemperature 255 "Invalid";
VAL_ 808 RMCU_2_MaxHeatSpeed 65535 "Invalid";
VAL_ 808 RMCU_2_MaxHeatTorque 4095 "Invalid";
VAL_ 808 RMCU_immoResult 0 "not learnt" 1 "Authentication OK" 2 "Authentication Failure" 3 "Authenticating" 4 "No Authentication";
VAL_ 859 TorqueReductReqRAValidData 0 "Not valid" 1 "Valid";
VAL_ 1022 FLZCU_CarMode 0 "Normal Mode" 1 "Factory Mode" 2 "Transport Mode" 3 "Exhibition Mode" 4 "Reserved" 5 "Reserved" 6 "Reserved" 7 "Not active";
VAL_ 1034 HCU_VehicleState 0 "Init" 1 "Sleep" 2 "PowerUp" 3 "Charging" 4 "Reserved" 5 "Reserved" 6 "Reserved" 7 "Reserved" 8 "Reserved" 9 "Reserved" 10 "Reserved" 11 "Reserved" 12 "Reserved" 13 "Reserved" 14 "Reserved" 15 "Reserved";
VAL_ 1034 HCU_RunMode 0 "EV" 1 "HEV" 2 "ICE" 3 "Reserved";
VAL_ 1034 HCU_PwrTrnModeDisp 0 "Static" 1 "Regenerating" 2 "ICE Only" 3 "EV Only" 4 "Hybrid Mode" 5 "REEV" 6 "Reserved" 7 "Reserved";
VAL_ 1034 HCU_IntelligentPowerSupply 0 "Charge Inhibit" 1 "No Request" 2 "Charging" 3 "Charge Complete" 4 "Reserved" 5 "Reserved" 6 "Reserved" 7 "Reserved";
VAL_ 1034 HCU_PowerModeFed 0 "Not Active" 1 "EV" 2 "HEV" 3 "EV+";
VAL_ 1034 HCU_LimpHomeMode 0 "Normal Mode" 1 "E-Drive Only" 2 "ICE-Drive Only" 3 "REEV Only";
VAL_ 1034 HCU_ISGRegenerateSts 0 "Not Active" 1 "Active";
VAL_ 1034 HCU_EmOverSpdWarn 0 "Not Warn" 1 "Warn";
VAL_ 1034 HCU_PowertrainFault 0 "No Fault" 1 "Fault";
VAL_ 1034 HCU_PrePTReady 0 "OFF" 1 "ON";
VAL_ 1034 HCU_PowerModeChangeFail 0 "NOT FAIL" 1 "FAIL";
VAL_ 1034 BMSH_MILReq 0 "No request" 1 "Request";
VAL_ 1034 TMF_EngMilLampReq 0 "No request" 1 "Request";
VAL_ 1034 TMR_EngMilLampReq 0 "No request" 1 "Request";
VAL_ 1034 HCU_MILReq 0 "No request" 1 "Request";
VAL_ 1034 HCU_HVReady 0 "LmpOFF" 1 "LmpON";
VAL_ 1034 HCU_PTReady 0 "LmpOFF" 1 "LmpON";
VAL_ 1034 HCU_ChargingSts 0 "No Charging" 1 "Stop Charging" 2 "Run Charging" 3 "Charge Complete";
VAL_ 1034 HCU_PtSts 0 "Powertrain Not Active" 1 "Park Engine Off" 2 "E Drive" 3 "Engine Starting" 4 "Engine Stopping" 5 "Series Charging" 6 "Idle Charging" 7 "Idle No Charging" 8 "Motor Drag Engine" 9 "Reserved" 10 "Reserved" 11 "Reserved" 12 "Reserved" 13 "Reserved" 14 "Reserved" 15 "Reserved";
VAL_ 1034 HCU_InHbStrtRes 0 "default" 1 "PT fault" 2 "Hood open" 3 "fuel door open" 4 "Insufficient torque" 5 "out of fuel" 6 "out of speed" 7 "third start failed" 8 "gun connect" 9 "reserve" 10 "reserve" 11 "reserve" 12 "reserve" 13 "reserve" 14 "reserve" 15 "reserve";
VAL_ 1044 HCU_RangeAval 2047 "Invalid";
VAL_ 1044 HCU_EnergyFlow 0 "OFF" 1 "Ready" 2 "2WD_EV" 3 "4WD_EV" 4 "2WD_ExtendRangeDisCharge" 5 "2WD_ExtendRangeCharge" 6 "4WD_ExtendRangeDisCharge" 7 "4WD_ExtendRangeCharge" 8 "2WD_Parallel" 9 "4WD_Parallel" 10 "Engine" 11 "Running_Generate" 12 "Parking_Generate" 13 "2WD_ReGenerateBrake" 14 "4WD_ReGenerateBrake" 15 "Charge";
VAL_ 1044 HCU_ReplaceWarmupCycle 0 "Not Active" 1 "Active";
VAL_ 1044 HCU_CLMOBDClearReq 0 "No Request" 1 "Request";
VAL_ 1044 HCU_2_G_ChgIncOper 0 "Not Active" 1 "active";
VAL_ 1044 HCU_2_G_ChgDepOper 0 "Not Active" 1 "active";
VAL_ 1044 HCU_SocManageFed_414h 0 "Default" 1 "Pure electricity priority mode" 2 "Fuel priority mode" 3 "SOC hold mode" 4 "Reserved" 5 "Reserved" 6 "Reserved" 7 "Reserved";
VAL_ 1044 HCU_SetSOCFed 255 "Invalid";
VAL_ 1044 VCU_BrakePedalStsValidData 0 "Valid" 1 "Not_Valid";
VAL_ 1044 VCU_BrakePedalSts 0 "Not_applied" 1 "Applied";
VAL_ 1044 HCU_EnergyFlowREEV 0 "OFF" 1 "during Start" 2 "Idle" 3 "Running_Generate" 4 "Reserved" 5 "Reserved" 6 "Reserved" 7 "Reserved" 8 "Reserved" 9 "Reserved" 10 "Reserved" 11 "Reserved" 12 "Reserved" 13 "Reserved" 14 "Reserved" 15 "Reserved" 16 "Reserved" 17 "Reserved" 18 "Reserved" 19 "Reserved" 20 "Reserved" 21 "Reserved" 22 "Reserved" 23 "Reserved" 24 "Reserved" 25 "Reserved" 26 "Reserved" 27 "Reserved" 28 "Reserved" 29 "Reserved" 30 "Reserved" 31 "Reserved";
VAL_ 1044 HCU_EmissionDetection 0 "Not Active" 1 "Active";
VAL_ 1044 HCU_2_G_IntrptGpfRgtvSt 0 "Not Active" 1 "Interrupt" 2 "Reserved" 3 "Reserved";
VAL_ 1044 HCU_2_G_LowBatteryInfo 0 "Not Active" 1 "NoRequest" 2 "Request" 3 "Sail Request";
VAL_ 1044 HCU_2_G_LowBatteryLowFuelInfo 0 "Not Active" 1 "NoRequest" 2 "Request" 3 "Reserved";
VAL_ 1044 HCU_2_G_HighTempLimit 0 "Not Active" 1 "Nolimit" 2 "limit" 3 "Reserved";
VAL_ 1057 VCU_shfChk 0 "LampOff" 1 "LampON";
VAL_ 1057 VCU_PowerLimitSOCLow 0 "NoLimit" 1 "DrvPwLimit" 2 "AcPwLimit" 3 "PTCPwLimit" 4 "DCDCPwLimit" 5 "Reserved";
VAL_ 1057 VCU_MCU_MilLampReq 0 "No request" 1 "Request";
VAL_ 1057 VCU_OPDinfo 0 "No request" 1 "OPD Inactive" 2 "OPD Not Allowed" 3 "Stop Mode Inactive" 4 "Stop Not Allowed" 5 "Reserved" 6 "Reserved" 7 "Reserved";
VAL_ 1057 VCU_ePTDrvPowerPcent 255 "Invalid";
VAL_ 1057 VCU_TowingMode 0 "NotActive" 1 "Active" 2 "Reserved";
VAL_ 1057 VCU_EgyRegenLevelHighAllowed 0 "Not Allowed" 1 "Allowed" 2 "High" 3 "Reserved";
VAL_ 1057 VCU_SportDriveModeAvailable 0 "Available" 1 "NotAvailable";
VAL_ 1057 VCU_RainSnowDriveModeAvailable 0 "Available" 1 "NotAvailable";
VAL_ 1057 VCU_OffRoadDriveModeAvailable 0 "Available" 1 "NotAvailable";
VAL_ 1057 VCU_CampAvailable 0 "Not Available" 1 "Available";
VAL_ 1057 VCU_DisChgSOCHighLim 255 "Invalid";
VAL_ 1057 VCU_DisChgSOCLowLim 255 "Invalid";
VAL_ 1057 VCU_EngyConsuPer10Km 4095 "Invalid";
VAL_ 1057 VCU_EngyConsuPer25Km 4095 "Invalid";
VAL_ 1057 VCU_EngyConsuPer50Km 4095 "Invalid";
VAL_ 1057 VCU_EngyConsuPer100m 4095 "Invalid";
VAL_ 1057 VCU_BookChrgSetFailRes 0 "Default" 1 "OBC Fault" 2 "HvBatt Fault" 3 "DCDC Fault" 4 "Vehicle Fault" 5 "Reserved" 6 "Reserved" 7 "Reserved";
VAL_ 1057 VCU_BookChrgFailRes 0 "Default" 1 "OBC Fault" 2 "HvBatt Fault" 3 "DCDC Fault" 4 "Vehicle Fault" 5 "ChargeStationFault" 6 "BNCMfault" 7 "EVSEandBNCMConnectFault" 8 "Reserved";
VAL_ 1057 VCU_HVILFault 0 "No fault" 1 "Fault";
VAL_ 1057 VCUExtendRang 1023 "Invalid";
VAL_ 1057 VCU_KeepWarmFailReason 0 "default" 1 "ChargeLineNotConnect" 2 "WarmNoNeed" 3 "VehicleFault" 4 "ChargeStationFault" 5 "BNCM fault" 6 "EVSEAuthrizeFail" 7 "Charging" 8 "PreHeating" 9 "Reserved" 10 "Reserved";
VAL_ 1057 VCU_ExtremeEnergySavingModeAv 0 "Unavailable" 1 "Available";
VAL_ 1057 VCU_TowModeAvailable 0 "Available" 1 "NotAvailable";
VAL_ 1057 VCU_StopModeSWStsResp 0 "Reserved" 1 "Creep" 2 "stop" 3 "Reserved";
VAL_ 1057 VCU_StopModeSWAllowed 0 "Not Allowed" 1 "Allowed";
VAL_ 1057 VCU_ChgDisChgLedCtrl 0 "Default(PortClose)" 1 "PortOpen" 2 "WaitingStart" 3 "BookChrgWaiting" 4 "PreHeat" 5 "KeepWarm" 6 "Charging" 7 "ChargePause" 8 "DisCharging" 9 "ChargeComplete" 10 "ChargeFault" 11 "ErrorConnection";
VAL_ 1057 VCU_CPMaxVolt 255 "Invalid";
VAL_ 1057 VCUExtremeEnergySavingModeReq 0 "NoRequest" 1 "Request_ADSoff" 2 "Request_ADSon";
VAL_ 1057 VCU_EpedalModeSts 0 "OFF" 1 "ON";
VAL_ 1057 VCU_BookChrgStsFb 0 "Default" 1 "Charging" 2 "ChargeFinished" 3 "Reserved";
VAL_ 1057 VCU_HVNM 0 "No Request" 1 "Request";
VAL_ 1057 VCU_DriveMode 0 "ECO" 1 "NORMAL" 2 "SPORT" 3 "RainSNOW" 4 "MUD(Res)" 5 "Offroad" 6 "Individual(Res)" 7 "SAND(Res)";
VAL_ 1057 HCU_EnterForceEVFailRes 0 "defaut" 1 "SOC Low" 2 "HVBattPwrLow" 3 "EngineAutoStrt" 4 "Reserved" 5 "Reserved" 6 "Reserved" 7 "Reserved";
VAL_ 1057 HCU_EngineSelfMaintain 0 "Not Active" 1 "Active" 2 "Reserved" 3 "Reserved";
VAL_ 1057 HCU_EnterForceChrgFailRes 0 "defaut" 1 "Fuel Empty" 2 "Engine Fault" 3 "ISG Fault" 4 "HVBattFault" 5 "SOC High" 6 "PTFault" 7 "Reserved";
VAL_ 1057 HCU_InStartRes 0 "defaut" 1 "Fuel Empty" 2 "Engine Fault" 3 "ISG Fault" 4 "BMSFault" 5 "PTFault" 6 "Reserved" 7 "Reserved";
VAL_ 1064 WorkingSts 0 "Not_Active" 1 "Active";
VAL_ 1064 ADCC_AdsLowPowSts_333h 0 "Not_active" 1 "ON" 2 "OFF";
VAL_ 1075 VCC_2_ConfigurationMessageTrg 0 "not active" 1 "active";
VAL_ 1097 TMS_RMCU_MotSelfHeatLvlReq 0 "No Request" 1 "Level 1" 2 "Level 2" 3 "Level 3" 4 "Level 4" 5 "Level 5" 6 "Reserved" 7 "Reserved";
VAL_ 1097 TMS_RMCU_MotSelfHeatEnReq 0 "Prohibit" 1 "Permission";
VAL_ 1099 ISGF_LockedRotorFlag 0 "Not Active" 1 "Active";
VAL_ 1099 ISGF_StatTemp 511 "Invalid";
VAL_ 1099 ISGF_VoltageT30 63 "Invalid";
VAL_ 1099 ISGF_SysTempOvrInd 0 "Lamp off" 1 "Lamp on";
VAL_ 1099 ISGF_MotOvrSpdWarn 0 "No Warning" 1 "Warning";
VAL_ 1099 ISGF_CalOffsetAngleReq 0 "No Request" 1 "Request";
VAL_ 1099 ISGF_HVILFault 0 "No Fault" 1 "Fault";
VAL_ 1099 ISGF_EngMilLampReq 0 "No request" 1 "Request";
VAL_ 1099 ISGF_InvTempOvrErr 0 "No Error" 1 "Error";
VAL_ 1103 RMCU_TMS_MotSelfHeatLvlFb 0 "No Request" 1 "Level1" 2 "Level2" 3 "Level3" 4 "Level4" 5 "Level5" 6 "Reserved" 7 "Reserved";
VAL_ 1103 RMCU_TMS_MotSelfHeatEnSts 0 "Prohibit Status" 1 "Permission Status";
VAL_ 1103 RMCU_IGBTmode 0 "FW" 1 "ASC" 2 "PWM_Run" 3 "Reserved" 4 "Reserved" 5 "Reserved" 6 "Reserved" 7 "Reserved";
VAL_ 1130 TCU_23_ErrLever 0 "No Error" 1 "Err_level1" 2 "Err_level2" 3 "Err_level3" 4 "Err_level4" 5 "Err_level5";
VAL_ 1130 TCU_23_GBFaultstatus 0 "No failure" 1 "GB failure" 2 "High oil over temperature" 3 "Clutch over temperature";
VAL_ 1130 TCU_23_STAT_LeverModeDisp 0 "No Display" 1 "Display P" 2 "Display R" 3 "Display N" 4 "Display D" 5 "Display M" 6 "Failure value" 7 "Invalid";
VAL_ 1130 TCU_23_GBWarmUpReq 0 "No Request" 1 "Warm Up Request";
VAL_ 1130 TCU_23_TeachInState 0 "Default" 1 "Successful" 2 "Fault" 3 "Teach in process" 4 "require teach in" 5 "teach in done";
VAL_ 1130 TCU_23_CluSelfLrng 0 "No Request" 1 "ClutchSelfLearnEnb";
VAL_ 1162 VehicleSpeedVSOSigValidData 0 "Valid" 1 "Not valid";
VAL_ 1163 FMCU_DHT_TempStatus 0 "Normal" 1 "High Temp Warning" 2 "Over Temp Failure" 3 "Reserved";
VAL_ 1163 FMCU_DHT_OvTempEngMilLampReq 0 "No Request For MIL Light" 1 "Request For MIL Light";
VAL_ 1163 FMCU_DHT_OilTempFlag 0 "Not Active" 1 "Active";
VAL_ 1177 FuelTankLidSts 0 "Close" 1 "Open";
VAL_ 1177 FuelTankLidLockFailureSts 0 "No failure" 1 "Failure";
VAL_ 1177 FuelTankLidSensorFailureSts 0 "No failure" 1 "Failure";
VAL_ 1177 FuelTankLidSWFailureSts 0 "No failure" 1 "Failure";
VAL_ 1202 EngineCoolantTemperture 255 "Invalid";
VAL_ 1202 FuelRollingCounter 255 "Invalid";
VAL_ 1202 EngineSpeed 2047 "Invalid";
VAL_ 1202 MILSts 0 "Off" 1 "Not used" 2 "Active" 3 "Not used";
VAL_ 1202 IEMSts 0 "Lamp Off" 1 "Lamp On";
VAL_ 1202 GPFWarning 0 "No GPF warning" 1 "GPF Full" 2 "GPF Overlimited" 3 "Reserved";
VAL_ 1202 EngineCoolantTempertureFailSts 0 "Fail Not Present" 1 "Fail Present";
VAL_ 1202 FuelRollingCounterValidData 0 "Valid" 1 "Not valid";
VAL_ 1202 EngineSpeedValidData 0 "Valid" 1 "Not valid";
VAL_ 1202 EPCSts 0 "Off" 1 "Active";
VAL_ 1202 EMS_1_G_EngineSts 0 "Not Run" 1 "Run";
VAL_ 1202 EMS_EngineSts_Actual 0 "Not Run" 1 "Run";
VAL_ 1202 OilPressureWarningLamp 0 "Off" 1 "On";
VAL_ 1204 VCU_AcceleratorPosRawIVD 0 "Valid" 1 "Invalid";
VAL_ 1204 VCU_1_G_PTReady 0 "LmpOFF" 1 "LmpON";
VAL_ 1204 VCU_1_G_DriveMode 0 "Not Active" 1 "ECO" 2 "Normal" 3 "Sport" 4 "Snow" 5 "Off Road" 6 "Individual" 7 "Reserved";
VAL_ 1204 VCU_1_G_BookChrgSetResponse 0 "Default" 1 "Success" 2 "Cancelled" 3 "Fail" 4 "Reserved";
VAL_ 1204 VCU_1_G_HvBattKeepWarmSts 0 "NotWarm" 1 "Warming" 2 "ExitWarm" 3 "WarmCompete" 4 "Reserved" 5 "Reserved" 6 "Reserved" 7 "Reserved";
VAL_ 1204 VCU_1_G_HvBattKeepWarmActiveReq 0 "default" 1 "StartWarm" 2 "EndWarm" 3 "Reserved";
VAL_ 1204 VCU_1_G_HundECAver 511 "Invalid";
VAL_ 1204 VCU_1_G_BookChrgSetStsFb 0 "NotBook" 1 "Booked" 2 "Reserved";
VAL_ 1204 VCU_1_G_EgyRegenLevel 0 "Off" 1 "Low" 2 "High" 3 "Reserved";
VAL_ 1204 VCU_1_G_PRNDGearAct 0 "Init" 1 "P" 2 "R" 3 "N" 4 "D" 5 "Reserved" 6 "Reserved" 7 "Reserved";
VAL_ 1207 WPump3FltSt 0 "Normal" 1 "Short_circuit" 2 "Open_circuit" 3 "Stall" 4 "Communication_error" 5 "Dryrun" 6 "OverVol" 7 "BelowVol" 8 "OverTempReduction" 9 "OverTempShutDown";
VAL_ 1207 CoolingFanFlt 0 "Normal" 1 "Stall" 2 "Circuit Open" 3 "Circuit Short" 4 "Over Current" 5 "Inter Fault";
VAL_ 1213 LoadValueCalculatedValidData 0 "Valid" 1 "Invalid";
VAL_ 1213 AbsoluteThrottlePosValidData 0 "Valid" 1 "Invalid";
VAL_ 1213 OBD_DrivingCycle 0 "Propulsion System Not Active" 1 "Propulsion System Active";
VAL_ 1213 OBD_WarmupCycle 0 "Not Active" 1 "Active";
VAL_ 1213 OBD_PermanentFailureCycle 0 "Not Active" 1 "Active";
VAL_ 1213 OBD_IgnCycle 0 "No active" 1 "Active";
VAL_ 1213 OBD_GeneralDenomiantor 0 "Not Active" 1 "Active";
VAL_ 1213 OBD_GeneralDenomiantorFreeze 0 "Not Active" 1 "Active";
VAL_ 1213 EMS_28_GpfRgtvSt 0 "Init" 1 "In progress" 2 "Abnormal exit" 3 "camplete";
VAL_ 1241 EMS_4_G_EngineSpeed_Actual 65535 "Invalid";
VAL_ 1241 LegisDiagStdardCnditionMet 0 "Invalid";
VAL_ 1241 FuelTankLidLockReq 0 "Not Active" 1 "Lock" 2 "Unlock" 3 "Reserved";
VAL_ 1241 FuelTankLidSystemFailureSts 0 "No failure" 1 "Failure";
VAL_ 1241 FuelTankPressureConditionReached 0 "Not Active" 1 "Wait to refuel" 2 "Ready to refuel" 3 "Reserved";
VAL_ 1241 LegisPostDTCClrDriveCycleCmplte 0 "Invalid";
VAL_ 1241 LegisDiagStdardCnditionFltPresnt 0 "Invalid";
VAL_ 1241 EMS_4_G_KL15Sts 0 "Lmp Off" 1 "Lmp On";
VAL_ 1252 TotalOdometer_km_OBD 16777215 "Invalid";
VAL_ 1252 TotalOdometer_km_OBDValidData 0 "Valid" 1 "Not valid";
VAL_ 1314 HCU_V2lDisChgBck 0 "Not_Active" 1 "V2L_ON" 2 "OFF";
VAL_ 1314 HCU_DisChgMemFed 0 "Not_Active" 1 "Remember" 2 "No_Remember" 3 "Reserved";
VAL_ 1314 HCU_V2VDisChgBck 0 "Not_Active" 1 "V2V_ON" 2 "OFF";
VAL_ 1314 HCU_V2l_IntlDisChgBck 0 "Not_Active" 1 "V2L_ON" 2 "OFF";
VAL_ 1314 HCU_FuelDetnOpDefeated 0 "No_Prompt" 1 "Prompt";
VAL_ 1314 HCU_FuelDetnModSwtFed 0 "Not_Active" 1 "ON" 2 "OFF" 3 "Invalid";
VAL_ 1314 HCU_FuelDetnStateFed 0 "Not_Active" 1 "HighIdle" 2 "LowIdle" 3 "Invalid";
VAL_ 1314 HCU_HVDownRepairModeFed 0 "Not_Active" 1 "ON" 2 "OFF" 3 "Invalid";
VAL_ 1314 HCU_TrailerMode 0 "Not_Active" 1 "ON" 2 "OFF" 3 "Invalid";
VAL_ 1314 HCU_TABSwtFed_522h 0 "Not_Active" 1 "Active" 2 "Stand_by" 3 "Failed";
VAL_ 1314 HCU_MotSelfHeatLvlReq 0 "No Request" 1 "Level 1" 2 "Level 2" 3 "Level 3" 4 "Level 4" 5 "Level 5" 6 "Reserved" 7 "Reserved";
VAL_ 1314 HCU_MotSelfHeatEnReq 0 "Prohibit" 1 "Permission";
VAL_ 1314 HCU_KeyDriveModememory 0 "Not_Active" 1 "Remember" 2 "No_Remember";
VAL_ 1314 HCU_DrivePowerDispSetFed 0 "Not_Active" 1 "PercentDisp" 2 "kWDisp";
VAL_ 1314 HCU_TCMStsReq_522h 0 "Disable" 1 "Enable";
VAL_ 1314 HCU_EXPERTNormFed 0 "Not_Active" 1 "ON" 2 "OFF" 3 "Invalid";
VAL_ 1314 HCU_4LModeFed 0 "Not_Active" 1 "Active";
VAL_ 1314 HCU_EXPERTEcoFed 0 "Not_Active" 1 "ON" 2 "OFF" 3 "Invalid";
VAL_ 1314 HCU_SingleRegnRmn 0 "Not_Active" 1 "Active";
VAL_ 1314 HCU_DRIFTModeSts 0 "Not_Active" 1 "Entry_Mode" 2 "Master_mode" 3 "Expert_mode";
VAL_ 1314 HCU_EXPERTAWDFed 0 "Not_Active" 1 "ON" 2 "OFF" 3 "Invalid";
VAL_ 1314 HCU_EXPERTRWDFed 0 "Not_Active" 1 "ON" 2 "OFF" 3 "Invalid";
VAL_ 1314 HCU_CrossaxisFed 0 "Not_Active" 1 "Active" 2 "Stand_by" 3 "Failed";
VAL_ 1314 HCU_EXPERTSportFed 0 "Not_Active" 1 "ON" 2 "OFF" 3 "Invalid";
VAL_ 1314 HCU_StopChrgnModeFed 0 "Not_Active" 1 "Silence" 2 "Quick";
VAL_ 1314 HCU_StopChrgnFed 0 "Not_Active" 1 "ON" 2 "OFF" 3 "Invalid";
VAL_ 1314 HCU_CLIMBFed 0 "Not_Active" 1 "ON" 2 "OFF" 3 "InValid";
VAL_ 1314 HCU_EXPERTAutoFed 0 "Not_Active" 1 "ON" 2 "OFF" 3 "Invalid";
VAL_ 1314 HCU_HEV_FunctionLimit 0 "Not_Active" 1 "Active";
VAL_ 1314 HCU_ParkingChargeReminder 0 "Not_Active" 1 "Active";
VAL_ 1314 HCU_PowerCut 0 "Not_Active" 1 "Active";
VAL_ 1314 HCU_IMMOReleaseSignal 0 "Not_Active" 1 "Active";
VAL_ 1314 HCU_LVPowSupSYSAbn_lit 0 "Not_Active" 1 "Active";
VAL_ 1314 HCU_ChrgnFctMemSt 0 "Not_Active" 1 "Remember" 2 "No_Remember" 3 "Reserved";
VAL_ 1314 HCU_PowerModeChangeInhibit 0 "Not_Active" 1 "Active";
VAL_ 1314 HCU_DisconnectChagWarn 0 "Not_Active" 1 "Active";
VAL_ 1314 HCU_EngineRunClmReq 0 "Not_Active" 1 "Active";
VAL_ 1314 HCU_VehicleSpeedMax_Limit 0 "Not_Active" 1 "Active";
VAL_ 1314 HCU_AccleAbility_Limit 0 "Not_Active" 1 "Active";
VAL_ 1314 HCU_DriveInhibit_GearP 0 "Not_Active" 1 "Active";
VAL_ 1314 HCU_SetModeNotChange 0 "Not_Active" 1 "Active";
VAL_ 1314 HCU_UTURNSnowFed 0 "Not_Active" 1 "Active";
VAL_ 1314 HCU_PowerLevel 0 "Init" 1 "Level_1" 2 "Level_2" 3 "Level_3" 4 "Level_4";
VAL_ 1314 HCU_TowingModeEna 0 "No Prompt" 1 "Prompt";
VAL_ 1314 HCU_LeaveVehicleWarning 0 "Not_Active" 1 "Active";
VAL_ 1314 HCU_DedicatedModeInhibit 0 "Not_Active" 1 "Active";
VAL_ 1314 HCU_DisChargeStopFault 0 "Init" 1 "LowSOC" 2 "LowFuel";
VAL_ 1314 HCU_RearEDLSts 0 "No Lock" 1 "UNLock" 2 "Lock" 3 "Warning" 4 "UnAvailable" 5 "Stuck_Open" 6 "Stuck_Close" 7 "Reserved" 8 "Reserved" 9 "Reserved";
VAL_ 1314 HCU_FrntEDLSts 0 "No Lock" 1 "UNLock" 2 "Lock" 3 "Warning" 4 "UnAvailable" 5 "Stuck Open" 6 "Stuck Close" 7 "Rear4LReq" 8 "RearReq" 9 "4LReq";
VAL_ 1314 HCU_DriveMode_JT 0 "ECO" 1 "NORMAL" 2 "SPORT" 3 "SNOW" 4 "MUD" 5 "OffRoad" 6 "SAND" 7 "ROCK" 8 "EXPERT" 9 "X" 10 "WADE" 11 "UTURN" 12 "DRIFT" 13 "TOW" 14 "OffroadRace" 15 "CarSickRelfMode" 16 "CleverEngy" 17 "DCM";
VAL_ 1314 HCU_SocManageFed 0 "Default" 1 "Pure_electricity_priority_mode" 2 "Fuel_priority_mode" 3 "SOC_hold_mode" 4 "SAVE" 5 "Charge";
VAL_ 1314 HCU_SinglePedalMemFed 0 "ON" 1 "OFF";
VAL_ 1314 HCU_CCOSwtFed 0 "Not_Active" 1 "Active" 2 "Stand_by" 3 "Failed";
VAL_ 1314 HCU_DrvGearShiftFailureIndcn 0 "No_Command" 1 "brake_pedal_applied" 2 "Over_Speed" 3 "Charge_Gun_Connect" 4 "EPB_Can_Not_Lock" 5 "EPB_Can_Not_Release" 6 "Invalid_shift" 7 "Shift_fault" 8 "BrkPedl_to_start" 9 "OpenDoor_Shift";
VAL_ 1314 HCU_UTURNSandFed 0 "OFF" 1 "ON";
VAL_ 1314 HCU_CruiseControlStatus 0 "Not_Active" 1 "Active" 2 "Stand_by" 3 "Fault";
VAL_ 1314 HCU_EXPERTEESPSet 0 "ALLON" 1 "TCS_VDC_OFF" 2 "ALLOFF" 3 "Reserved";
VAL_ 1314 HCU_EgyRegenLevel 0 "Off" 1 "Low" 2 "High" 3 "middle" 4 "SinglePedl";
VAL_ 1314 HCU_EngyFlowToDisp 0 "Init" 1 "No_EngyFlow" 2 "Engine Idling" 3 "EV_FWD" 4 "EV_FWD_Regene" 5 "EV_RWD" 6 "EV_RWD_Regene" 7 "EV_4WD" 8 "EV_4WD_Regene" 9 "Series_FWD_BattChg" 10 "Series_FWD_BattDisChg" 11 "Series_FWD_BattNoCurr" 12 "Series_FWD_Regene" 13 "Series_RWD_BattChg" 14 "Series_RWD_BattDisChg" 15 "Series_RWD_BattNoCurr" 16 "Series_RWD_Regene" 17 "Series_4WD_BattChg" 18 "Series_4WD_BattDisChg" 19 "Series_4WD_BattNoCurr" 20 "Series_4WD_Regene" 21 "Parallel_FWD_BattChg" 22 "Parallel_FWD_BattDisChg" 23 "Parallel_FWD_BattNoCurr" 24 "Parallel_FWD_Regene" 25 "Parallel_4WD_BattChg" 26 "Parallel_4WD_BattDisChg" 27 "Parallel_4WD_BattNoCurr" 28 "Parallel_4WD_Regene" 29 "StopCharging_BatChg" 30 "StopCharging_BatDChg" 31 "StopCharging_BatNoCurr";
VAL_ 1314 HCU_UTURNGrassFed 0 "OFF" 1 "ON";
VAL_ 1314 HCU_UTURNMudFed 0 "OFF" 1 "ON";
VAL_ 1314 HCU_LTCDispFed 0 "Not Active" 1 "WLTC" 2 "CLTC";
VAL_ 1314 HCU_iTAS_Warn 0 "No_Warn" 1 "ELD Unable to lock" 2 "Please_Release_EPB" 3 "Please_slow_down" 4 "Disc temperature too high" 5 "vehicle is stuck" 6 "iTAS active max time" 7 "Please Open in D";
VAL_ 1314 HCU_iCCO_Warn 0 "No_Warn" 1 "Please_Release_EPB" 2 "Please_slow_down" 3 "Please_Close_ Door and Belt" 4 "Please_Open in D or N" 5 "Please_Close_APA/ACC/CC" 6 "Please_Exit_HDC/AVH" 7 "Please_Switch to Snow/Mud/Sand/Rock" 8 "Please Depress the brake pedal" 9 "iCCO Exited" 10 "Reserved" 11 "Reserved" 12 "Reserved" 13 "Reserved" 14 "Reserved" 15 "Reserved";
VAL_ 1314 HCU_DriveModeChangeFail 0 "NOT FAIL" 1 "FAIL";
VAL_ 1314 HCU_25_Crossaxis_Warn 0 "No_Warn" 1 "Please_Release_EPB" 2 "Crossaxis Exited" 3 "Please_Open in D" 4 "Please_Close_ Door and Belt" 5 "Please Depress the brake pedal" 6 "Not Adjust Suspension Height" 7 "Reserved";
VAL_ 1314 HCU_25_EDLFed 0 "Not_Active" 1 "Forward" 2 "Backward" 3 "Reserved";
VAL_ 1314 HCU_DraggingModeRemind 0 "Not_Active" 1 "Enter" 2 "Working" 3 "Exit" 4 "Reserved" 5 "Reserved" 6 "Reserved" 7 "Reserved";
VAL_ 1314 HCU_iTASSceneReq 0 "Not Active" 1 "Snow" 2 "Mud" 3 "Sand" 4 "Grass" 5 "Exit";
VAL_ 1314 HCU_25_iTAS_SlopWarn 0 "No_Warn" 1 "Active" 2 "Reserved" 3 "Reserved";
VAL_ 1314 HCU_ExterTempLowHint 0 "Init" 1 "Temp to HEV" 2 "Temp to EngRun" 3 "reserved";
VAL_ 1314 HCU_iTAS_Active 0 "Not_Active" 1 "Standby" 2 "Active" 3 "Filed";
VAL_ 1314 HCU_25_VehSpdOffroadRmn 0 "Not Acitve" 1 "Acitve";
VAL_ 1314 HCU_DrivingModReq 0 "Normal" 1 "Snow" 2 "Mud" 3 "Sand" 4 "Rock" 5 "Wade" 6 "Expert" 7 "UTURN" 8 "DRIFT" 9 "OffroadRace" 10 "DCM" 11 "Reserved" 12 "Reserved" 13 "Reserved" 14 "Reserved" 15 "Reserved" 16 "Reserved" 17 "Reserved" 18 "Reserved" 19 "Reserved" 20 "Reserved" 21 "Reserved" 22 "Reserved" 23 "Reserved" 24 "Reserved" 25 "Reserved" 26 "Reserved" 27 "Reserved" 28 "Reserved" 29 "Reserved" 30 "Reserved" 31 "invalid";
VAL_ 1314 HCU_25_ADS_FctSts 0 "Off" 1 "On";
VAL_ 1314 HCU_25_DRIFTModeSetReq 0 "Not Active" 1 "Entry Mode" 2 "Master mode" 3 "Expert mode";
VAL_ 1314 HCU_25_CrossaxisReq 0 "Not Active" 1 "ON" 2 "OFF" 3 "Not used";
VAL_ 1314 HCU_25_CCOSwtReq 0 "Not Active" 1 "ON" 2 "OFF" 3 "invalid";
VAL_ 1314 HCU_25_iDRIFT_Warn 0 "No_Warn" 1 "Please_Close_ Door and Belt" 2 "Please stop the vehicle" 3 "Error" 4 "Not Adjust Suspension Height";
VAL_ 1314 HCU_25_SetVehSpdOffroad 0 "No_Warn" 1 "Active" 2 "Reserved" 3 "Reserved";
VAL_ 1314 HCU_25_LaunchMod_Warn 0 "No_Warn" 1 "Active" 2 "Exit" 3 "Error" 4 "Reserved" 5 "Reserved" 6 "Reserved" 7 "Reserved";
VAL_ 1314 HCU_25_TAB_Warn 0 "No Warn" 1 "Please open CCO" 2 "Please Unlock EDL" 3 "Prohibit locking EDL" 4 "Reserved";
VAL_ 1314 HCU_25_CCO_TextDisp 0 "No_Warn" 1 "Please_Release_EPB" 2 "Please_Slow_Down" 3 "Please_Close_ Door and Belt" 4 "Please_Open in D" 5 "Please_Close_APA/ACC/CC" 6 "Please_Exit_HDC" 7 "Please_Switch to Mud/Sand/Rock" 8 "Reduce_Speed_Below 12kph" 9 "Please_Close_CCO" 10 "CC0 Exited";
VAL_ 1314 HCU_25_DCM_Warn 0 "No_Warn" 1 "Please_Release_EPB" 2 "Please_Close_ Door and Belt" 3 "Please_Open in D/R" 4 "Please_Close_APA/ACC/CC" 5 "Please_Exit_HDC" 6 "Please Depress the brake pedal" 7 "CCM Exited" 8 "Please enter or exit this mode when the vehicle is stationary" 9 "power limit" 10 "Please release the accelerator pedal" 11 "Please depress the brake pedal" 12 "Reserved" 13 "Reserved" 14 "Reserved" 15 "Reserved";
VAL_ 1314 HCU_25_CCMFed 0 "Not Active" 1 "On" 2 "Off" 3 "Reserved";
VAL_ 1314 HCU_25_TABReq 0 "Not Active" 1 "ON" 2 "OFF" 3 "Not used";
VAL_ 1314 HCU_CrossBorderSts 0 "Not Active" 1 "On" 2 "Off" 3 "Reserved";
VAL_ 1314 HCU_stCleverDrvAct_522h 0 "OFF" 1 "ON" 2 "Reserved" 3 "Invalid";
VAL_ 1314 HCU_stCleverRgnAct_522h 0 "OFF" 1 "ON" 2 "Reserved" 3 "Invalid";
VAL_ 1314 HCU_stCleverMainAct_522h 0 "OFF" 1 "ON" 2 "Reserved" 3 "Invalid";
VAL_ 1314 EnergySavingModeSts_522h 0 "Not Active" 1 "ON" 2 "OFF" 3 "Reserved";
VAL_ 1314 HCU_facCleverDrvActRstFed_522h 0 "Not Active" 1 "success" 2 "Fail" 3 "Reserved";
VAL_ 1314 HCU_ATCM_Operation_REQ_522h 0 "Not Active" 1 "Switch to sailfunc indiction" 2 "Switch to upbeach indiction" 3 "misoperation indiction”press sailfunc sw when conenmod “" 4 "misoperation indiction”press upbeach  sw when conenmod“" 5 "misoperation indiction”press upbeach sw when wadests“" 6 "reserved" 7 "reserved";
VAL_ 1314 HCU_ModeSwFailureIndc_522h 0 "Not Active" 1 "Entry navigation failed“Car door is not closed”" 2 "Entry navigation failed“Rearview mirror not deployed”" 3 "Entry navigation failed“Intake and exhaust waterproof valve malfunction”" 4 "Entry navigation failed“Speed too fast”" 5 "Entry navigation failed“Low battery”" 6 "Entry navigation failed“Air conditioning drain valve malfunction|Cooling fan malfunction”";
VAL_ 1314 HCU_Sailmode_522h 0 "Convenmod" 1 "SalWadeSts" 2 "DpWadeSts" 3 "SailingFunc" 4 "UpbeachSts" 5 "WaitfinspSts" 6 "EmerfloatingSts" 7 "Reserved";
VAL_ 1314 HCU_CarSickRelfModeFb 0 "NotActive" 1 "ON" 2 "OFF";
VAL_ 1314 HCU_DeepSnowSts_522h 0 "NOT ACTIVE" 1 "ON" 2 "OFF";
VAL_ 1314 DriveModeChangeFailReason_522h 0 "NOT FAIL" 1 "Fail" 2 "EngySavMod_Fail" 3 "Reserved";
VAL_ 1314 HCU_CLIMBDisReason_522h 0 "No_Warn" 1 "Please_brake_to_PtReady" 2 "Please_Open in D or N" 3 "Please_Switch to Rock" 4 "TCS/DTC/AVH/ABS_Active" 5 "Please_Close_APA/ACC/CC" 6 "Please_Slow_Down" 7 "Drive_System_Err" 8 "LongitudinalAcceleration_Invld" 9 "Pleased quit iCCO" 10 "OPD_Brake_not_Available" 11 "IPB_System_Err" 12 "Reserved" 13 "Reserved" 14 "Reserved" 15 "Reserved";
VAL_ 1314 HCU_CarSickRelfModeDisReason 0 "No prompts" 1 "Please exit off-road mode" 2 "Please exit CCO mode" 3 "Please exit power saving mode" 4 "Please exit Towing Mode" 5 "Please exit TrailerMode" 6 "Please exit CCMode" 7 "Please exit ADS mode";
VAL_ 1314 HCU_DCMSwtFed 0 "not active" 1 "sand" 2 "snow" 3 "crawl" 4 "forest" 5 "Tug of war" 6 "Rescue" 7 "Reserved";
VAL_ 1314 HCU_LightSandSts_522h 0 "Inactive" 1 "ON" 2 "OFF";
VAL_ 1315 RMCU_2_G_InverterTemperature 255 "Invalid";
VAL_ 1315 RMCU_2_G_StatorTemperature 511 "Invalid";
VAL_ 1315 RMCU_2_G_OutputTorque 4095 "Invalid";
VAL_ 1315 RMCU_2_G_Speed 65535 "Invalid";
VAL_ 1315 RMCU_2_GVoltageHV 1023 "Invalid";
VAL_ 1315 RMCU_2_G_CurrentHV 2047 "Invalid";
VAL_ 1338 FMCU_MotWorkState 0 "standby" 1 "electric" 2 "generation" 3 "Reserved";
VAL_ 1403 RMCU_ErrLvlDis 0 "No Error" 1 "Err_level1" 2 "Err_level2" 3 "Err_level3" 4 "Err_level4" 5 "Err_level5" 6 "Err_level6";
VAL_ 1403 RMCU_InvTempAlarm 0 "no fault" 1 "Fault";
VAL_ 1403 RMCU_MotTempAlarm 0 "no fault" 1 "Fault";
VAL_ 1403 RMCU_MotWorkState 0 "Reserved" 1 "electric" 2 "generation" 3 "poweroff" 4 "standby" 5 "Fault" 6 "Reserved" 7 "invalid";
VAL_ 1403 RMCU_MILSts 0 "Off" 1 "Not used(Reserved)" 2 "Active" 3 "Not used(Reserved)";
VAL_ 1403 RMCU_Speed_EDR 65535 "Invalid";
VAL_ 1403 RMCU_1_G_OvercurrentAlarm 0 "no fault" 1 "fault";
VAL_ 1403 RMCU_1_G_OverspeedAlarm 0 "no fault" 1 "fault";
VAL_ 1407 RMCU_SupplierCode 0 "unkown" 1 "UAES" 2 "INOVANCE";
VAL_ 1479 FMCU_BoostModeAct 0 "Direct Mode" 1 "Boost Mode" 2 "Buck Mode" 3 "Fault";
VAL_ 1479 FMCU_GM_Oil_Valve_Sts 0 "Open" 1 "Closed" 2 "Fault" 3 "Reserved";
VAL_ 1582 RMR_RMCU 0 "Inactive" 1 "Active";
VAL_ 1582 RMCU_Wakeup_Poweron 0 "Inactive" 1 "Active";
VAL_ 1582 RMCU_Wakeup_NM 0 "Inactive" 1 "Active";
VAL_ 1582 RMCU_Wakeup_Diag 0 "Inactive" 1 "Active";
VAL_ 1582 RMCU_Awake_Poweron 0 "Inactive" 1 "Active";
VAL_ 1582 RMCU_Awake_NM 0 "Inactive" 1 "Active";
VAL_ 1582 RMCU_Awake_Diag 0 "Inactive" 1 "Active";
VAL_ 1582 RMCU_Awake_Discharge 0 "Inactive" 1 "Active";
VAL_ 1582 RMCU_Awake_HVON 0 "Inactive" 1 "Active";
